VERSION ""

NS_ :

BS_:

BU_:

BO_ 3221225472 VECTOR__INDEPENDENT_SIG_MSG: 0 Vector__XXX
 SG_ ascii_space : 0|8@1+ (1,0) [0|255] "" Vector__XXX
 SG_ TransmissionCurrentRange : 0|8@1+ (1,0) [0|255] "" Vector__XXX
 SG_ ONCmd : 0|1@1+ (1,0) [0|1] "" Vector__XXX
 SG_ NotOff2Cmd : 0|1@1+ (1,0) [0|1] "" Vector__XXX
 SG_ NotOff3Cmd : 0|1@1+ (1,0) [0|1] "" Vector__XXX
 SG_ Enable : 0|1@1+ (1,0) [0|1] "" Vector__XXX
 SG_ NotHLGResetCmd : 0|1@1+ (1,0) [0|1] "" Vector__XXX
 SG_ NotRFGStopCmd : 0|1@1+ (1,0) [0|1] "" Vector__XXX
 SG_ SetpointEn : 0|1@1+ (1,0) [0|1] "" Vector__XXX
 SG_ AckResetQuit : 0|1@1+ (1,0) [0|1] "" Vector__XXX
 SG_ AuxInv1Spd : 0|16@1- (1,0) [-32768|32767] "rpm" Vector__XXX
 SG_ ONCmd : 0|1@1+ (1,0) [0|1] "" Vector__XXX
 SG_ NotOff2Cmd : 0|1@1+ (1,0) [0|1] "" Vector__XXX
 SG_ NotOff3Cmd : 0|1@1+ (1,0) [0|1] "" Vector__XXX
 SG_ Enable : 0|1@1+ (1,0) [0|1] "" Vector__XXX
 SG_ NotHLGResetCmd : 0|1@1+ (1,0) [0|1] "" Vector__XXX
 SG_ NotRFGStopCmd : 0|1@1+ (1,0) [0|1] "" Vector__XXX
 SG_ SetpointEn : 0|1@1+ (1,0) [0|1] "" Vector__XXX
 SG_ AckResetQuit : 0|1@1+ (1,0) [0|1] "" Vector__XXX
 SG_ AuxInv2Spd : 0|16@1- (1,0) [-32768|32767] "rpm" Vector__XXX
 SG_ Requestgear : 0|8@1+ (1,0) [0|255] "" Vector__XXX
 SG_ DNR_led_CurrentLED : 0|8@1+ (1,0) [0|255] "" Vector__XXX
 SG_ DNR_LED_Curt_ASCCI : 0|8@1+ (1,0) [0|255] "" Vector__XXX
 SG_ OBC_charge_enable : 0|2@1+ (1,0) [0|3] "" Vector__XXX
 SG_ Plug_lock_request : 0|2@1+ (1,0) [0|3] "" Vector__XXX
 SG_ Vehicle_Insulation_Monitoring : 0|2@1+ (1,0) [0|3] "" Vector__XXX
 SG_ reserved7 : 0|2@1+ (1,0) [0|3] "" Vector__XXX
 SG_ EV_DisconnectingDevice : 0|2@1+ (1,0) [0|3] "" Vector__XXX
 SG_ reserved8 : 0|12@1+ (1,0) [0|4095] "" Vector__XXX
 SG_ reserved9 : 0|32@1+ (1,0) [0|65535] "" Vector__XXX
 SG_ Inlet_LED_Green : 0|2@1+ (1,0) [0|3] "" Vector__XXX
 SG_ Inlet_LED_Blue : 0|2@1+ (1,0) [0|3] "" Vector__XXX
 SG_ Inlet_LED_Red : 0|2@1+ (1,0) [0|3] "" Vector__XXX
 SG_ EV_DisconnectingDevicePlus : 0|2@1+ (1,0) [0|3] "" Vector__XXX
 SG_ EV_DisconnectingDeviceMinus : 0|2@1+ (1,0) [0|3] "" Vector__XXX
 SG_ EVEnergyRequest : 0|16@1+ (100,0) [0|3276700] "Wh" Vector__XXX
 SG_ EVEnergyCapacity : 0|16@1+ (100,0) [0|3276700] "Wh" Vector__XXX
 SG_ reserved43 : 0|32@1+ (1,0) [0|4294967295] "" Vector__XXX
 SG_ EVSECompatible : 0|2@1+ (1,0) [0|3] "" Vector__XXX
 SG_ VoltageMatch : 0|2@1+ (1,0) [0|3] "" Vector__XXX
 SG_ ControlPilotState : 0|4@1+ (1,0) [0|15] "" Vector__XXX
 SG_ ControlPilotDutyCycle : 0|7@1+ (1,0) [0|100] "%" Vector__XXX
 SG_ TCPStatus : 0|2@1+ (1,0) [0|3] "" Vector__XXX
 SG_ ActualChargeProtocol : 0|4@1+ (1,0) [0|15] "" Vector__XXX
 SG_ Charge_Plug_Locked : 0|2@1+ (1,0) [0|3] "" Vector__XXX
 SG_ ProximityPinState : 0|4@1+ (1,0) [0|15] "" Vector__XXX
 SG_ StateMachineState : 0|4@1+ (1,0) [0|15] "" Vector__XXX
 SG_ reserved3 : 0|1@1+ (1,0) [0|1] "" Vector__XXX
 SG_ reserved4 : 0|2@1+ (1,0) [0|3] "" Vector__XXX
 SG_ reserved5 : 0|6@1+ (1,0) [0|63] "" Vector__XXX
 SG_ reserved6 : 0|24@1+ (1,0) [0|16777215] "" Vector__XXX
 SG_ EVSECurrentRegulationTolerance : 0|8@1+ (0.2,0) [0|50] "A" Vector__XXX
 SG_ EVSEPeakCurrentRipple : 0|8@1+ (0.2,0) [0|50] "A" Vector__XXX
 SG_ EVSEMinVoltage : 0|16@1+ (0.1,0) [0|6500] "V" Vector__XXX
 SG_ EVSEMinCurrent : 0|16@1+ (0.1,-3250) [-3250|3250] "A" Vector__XXX
 SG_ reserved13 : 0|16@1+ (1,0) [0|65535] "" Vector__XXX
 SG_ EVSEEnergyToBeDelivered : 0|16@1+ (100,0) [0|3276700] "Wh" Vector__XXX
 SG_ EVSEMaxPower : 0|16@1+ (100,0) [0|3276700] "W" Vector__XXX
 SG_ EVSEMaxVoltage : 0|16@1+ (0.1,0) [0|6500] "V" Vector__XXX
 SG_ EVSEMaxCurrent : 0|16@1+ (0.1,0) [0|6500] "A" Vector__XXX
 SG_ EVWeldingDetectionEnable : 0|2@1+ (1,0) [0|3] "" Vector__XXX
 SG_ EVReady : 0|2@1+ (1,0) [0|3] "" Vector__XXX
 SG_ ChargeStopIndication : 0|2@1+ (1,0) [0|3] "" Vector__XXX
 SG_ ChargeProgressIndication : 0|2@1+ (1,0) [0|3] "" Vector__XXX
 SG_ reserved19 : 0|24@1+ (1,0) [0|16777215] "" Vector__XXX
 SG_ reserved20 : 0|24@1+ (1,0) [0|16777215] "" Vector__XXX
 SG_ ChargeProtocolPriority : 0|8@1+ (1,0) [0|255] "" Vector__XXX
 SG_ EVRESSConditioning : 0|2@1+ (1,0) [0|3] "" Vector__XXX
 SG_ EVTimeToFullSoC : 0|18@1+ (1,0) [0|262142] "s" Vector__XXX
 SG_ EVTimeToBulkSoC : 0|18@1+ (1,0) [0|262142] "s" Vector__XXX
 SG_ EVErrorCode : 0|4@1+ (1,0) [0|15] "" Vector__XXX
 SG_ EVCabinConditioning : 0|2@1+ (1,0) [0|3] "" Vector__XXX
 SG_ EVBulkChargingComplete : 0|2@1+ (1,0) [0|3] "" Vector__XXX
 SG_ EVChargingComplete : 0|2@1+ (1,0) [0|3] "" Vector__XXX
 SG_ EVSoC : 0|8@1+ (0.5,0) [0|100] "" Vector__XXX
 SG_ reserved21 : 0|2@1+ (1,0) [0|3] "" Vector__XXX
 SG_ reserved22 : 0|6@1+ (1,0) [0|63] "" Vector__XXX
 SG_ EVPreChargeVoltage : 0|16@1+ (0.1,0) [0|6500] "V" Vector__XXX
 SG_ EVTargetVoltage : 0|16@1+ (0.1,0) [0|6500] "V" Vector__XXX
 SG_ EVTargetCurrent : 0|16@1+ (0.1,-3250) [-3250|3250] "A" Vector__XXX
 SG_ reserved17 : 0|16@1+ (1,0) [0|65535] "" Vector__XXX
 SG_ EVBulkSoC : 0|8@1+ (0.5,0) [0|100] "%" Vector__XXX
 SG_ EVFullSoC : 0|8@1+ (0.5,0) [0|100] "%" Vector__XXX
 SG_ EVMaxVoltage : 0|16@1+ (0.1,0) [0|6500] "V" Vector__XXX
 SG_ EVMaxPower : 0|16@1+ (100,0) [0|3276700] "W" Vector__XXX
 SG_ EVMaxCurrent : 0|16@1+ (0.1,0) [0|6500] "A" Vector__XXX
 SG_ EVSEStatusCode : 0|4@1+ (1,0) [0|15] "" Vector__XXX
 SG_ EVSEPowerLimitAchieved : 0|2@1+ (1,0) [0|3] "" Vector__XXX
 SG_ EVSEVoltageLimitAchieved : 0|2@1+ (1,0) [0|3] "" Vector__XXX
 SG_ EVSECurrentLimitAchieved : 0|2@1+ (1,0) [0|3] "" Vector__XXX
 SG_ EVSEIsolationStatus : 0|3@1+ (1,0) [0|7] "" Vector__XXX
 SG_ EVSEPresentCurrent : 0|16@1+ (0.1,-3250) [-3250|3250] "A" Vector__XXX
 SG_ EVSEPresentVoltage : 0|16@1+ (0.1,0) [0|6500] "V" Vector__XXX
 SG_ reserved14 : 0|1@1+ (1,0) [0|1] "" Vector__XXX
 SG_ reserved15 : 0|2@1+ (1,0) [0|3] "" Vector__XXX
 SG_ reserved16 : 0|16@1+ (1,0) [0|65535] "" Vector__XXX
 SG_ EVPreChargeVoltage : 0|16@1+ (0.1,0) [0|6500] "V" Vector__XXX
 SG_ EVTargetVoltage : 0|16@1+ (0.1,0) [0|6500] "V" Vector__XXX
 SG_ EVTargetCurrent : 0|16@1+ (0.1,-3250) [-3250|3250] "A" Vector__XXX
 SG_ reserved18 : 0|16@1+ (1,0) [0|65535] "" Vector__XXX
 SG_ AdjustSeconds : 0|8@1+ (0.25,0) [0|62.5] "s" Vector__XXX
 SG_ AdjustMinutes : 0|8@1+ (1,0) [0|250] "min" Vector__XXX
 SG_ AdjustHours : 0|8@1+ (1,0) [0|250] "h" Vector__XXX
 SG_ AdjustMonth : 0|8@1+ (1,0) [0|250] "month" Vector__XXX
 SG_ AdjustDay : 0|8@1+ (0.25,0) [0|62.5] "Days" Vector__XXX
 SG_ AdjustYear : 0|8@1+ (1,1985) [1985|2235] "year" Vector__XXX
 SG_ AdjustLocalMinuteOffset : 0|8@1+ (1,-125) [-125|125] "min" Vector__XXX
 SG_ AdjustLocalHourOffset : 0|8@1+ (1,-125) [-125|125] "h" Vector__XXX
 SG_ BatteryVoltage : 0|16@1+ (0.1,0) [0|6553.5] "V" Vector__XXX
 SG_ Reserved : 0|2@1+ (1,0) [0|3] "" Vector__XXX
 SG_ Tire_Press_Threshold_Detection : 0|3@1+ (1,0) [0|7] "" Vector__XXX
 SG_ Tire_Temp_Threshold_Detection : 0|3@1+ (1,0) [0|7] "" Vector__XXX
 SG_ Sensor_Battery_Level_Status : 0|2@1+ (1,0) [0|3] "" Vector__XXX
 SG_ Sensor_Battery_Level : 0|8@1+ (1,0) [0|100] "%" Vector__XXX
 SG_ Sensor_RSSI : 0|8@1+ (1,0) [0|100] "dbm" Vector__XXX
 SG_ CTI_Wheel_End_Electrical_Fault : 0|2@1+ (1,0) [0|3] "" Vector__XXX
 SG_ CTI_Tire_Status : 0|2@1+ (1,0) [0|3] "" Vector__XXX
 SG_ Sensor_Status : 0|2@1+ (1,0) [0|3] "" Vector__XXX
 SG_ Tire_Temperature : 0|16@1- (0.03125,-273) [-273|750.96875] "deg C" Vector__XXX
 SG_ Tire_Pressure : 0|8@1+ (5.5,0) [0|1400] "kPa" Vector__XXX
 SG_ Tire_Location : 0|8@1+ (1,0) [0|255] "" Vector__XXX
 SG_ TP_Front_Left : 0|8@1+ (1,0) [0|1] "PSI" Vector__XXX
 SG_ TP_Front_Right : 0|8@1+ (1,0) [0|255] "PSI" Vector__XXX
 SG_ TP_Rear_Left_Outer : 0|8@1+ (1,0) [0|255] "PSI" Vector__XXX
 SG_ TP_Rear_Left_Inner : 0|8@1+ (1,0) [0|255] "PSI" Vector__XXX
 SG_ TP_Rear_Right_Outer : 0|8@1+ (1,0) [0|255] "PSI" Vector__XXX
 SG_ TP_Rear_Right_Inner : 0|8@1+ (1,0) [0|255] "PSI" Vector__XXX
 SG_ Seat_Belt : 0|1@1+ (1,0) [0|1] "" Vector__XXX
 SG_ Crash_Detection : 0|1@1+ (1,0) [0|1] "" Vector__XXX
 SG_ Harsh_Braking : 0|1@1+ (1,0) [0|1] "" Vector__XXX
 SG_ TP_Spare_Tire : 0|8@1+ (1,0) [0|255] "PSL" Vector__XXX
 SG_ TT_Front_Left : 0|8@1+ (1,0) [0|255] "degree C" Vector__XXX
 SG_ TT_Front_Right : 0|8@1+ (1,0) [0|255] "degree C" Vector__XXX
 SG_ TT_Rear_Left_Outer : 0|8@1+ (1,0) [0|255] "degree C" Vector__XXX
 SG_ TT_Rear_Left_Inner : 0|8@1+ (1,0) [0|1] "degree C" Vector__XXX
 SG_ TT_Rear_Right_Outer : 0|8@1+ (1,0) [0|255] "degree C" Vector__XXX
 SG_ TT_Rear_Right_Inner : 0|8@1+ (1,0) [0|255] "degree C" Vector__XXX
 SG_ TT_Spare_Tire : 0|8@1+ (1,0) [0|1] "degree C" Vector__XXX
 SG_ Tel_SOC : 0|8@1+ (1,0) [0|100] "" Vector__XXX
 SG_ Tel_Battery_Current : 0|16@1+ (1,-255) [-255|32767] "" Vector__XXX
 SG_ Tel_Battery_Voltage : 0|8@1+ (4,0) [0|1020] "" Vector__XXX
 SG_ Tel_KWh_remaining : 0|8@1+ (1,0) [0|200] "" Vector__XXX
 SG_ Tel_SOH : 0|8@1+ (1,0) [0|100] "" Vector__XXX
 SG_ Tel_Battery_System_Fault : 0|1@1+ (1,0) [0|1] "" Vector__XXX
 SG_ Tel_Regeneration : 0|1@1+ (1,0) [0|1] "" Vector__XXX
 SG_ Tel_Low_Pressure : 0|1@1+ (1,0) [0|1] "" Vector__XXX
 SG_ Tel_Charging_Status : 0|1@1+ (1,0) [0|1] "" Vector__XXX
 SG_ Tel_Charge_Plug_Status : 0|1@1+ (1,0) [0|1] "" Vector__XXX
 SG_ Tel_Bat_Temp : 0|8@1+ (1,0) [0|255] "C" Vector__XXX
 SG_ Tel_BCS_Comp_En : 0|1@1+ (1,0) [0|1] "" Vector__XXX
 SG_ Tel_BCS_Pump_En : 0|1@1+ (1,0) [0|1] "" Vector__XXX
 SG_ Tel_motor_speed : 0|8@1+ (10,0) [0|2550] "" Vector__XXX
 SG_ Tel_Vehicle_Speed : 0|8@1+ (1,0) [0|100] "" Vector__XXX
 SG_ Tel_Motor_Temperature : 0|8@1+ (1,0) [0|200] "" Vector__XXX
 SG_ Tel_Front_End_Aux_Fault : 0|1@1+ (1,0) [0|1] "" Vector__XXX
 SG_ Tel_Traction_System_Fault : 0|1@1+ (1,0) [0|1] "" Vector__XXX
 SG_ Tel_LV_System_Fault : 0|1@1+ (1,0) [0|1] "" Vector__XXX
 SG_ Energy_Consumption_per_km : 0|16@1- (0.001,0) [-32.768|32.767] "kwh/km" Vector__XXX
 SG_ Instant_Energy_Cons_per_km : 0|16@1- (0.001,0) [-32.768|32.767] "" Vector__XXX
 SG_ Charge_Plug_Locked : 0|1@1+ (1,0) [0|1] "" Vector__XXX
 SG_ State_Machine_State : 0|4@1+ (1,0) [0|15] "" Vector__XXX
 SG_ IVT_Voltage_Inlet_Value : 0|32@1- (0.001,0) [-2147483.648|2147483.647] "V" Vector__XXX
 SG_ IVT_Voltage_Inlet_ResultState : 0|4@1+ (1,0) [0|15] "" Vector__XXX
 SG_ IVT_Voltage_Inlet_MsgCount : 0|4@1+ (1,0) [0|15] "" Vector__XXX
 SG_ IVT_Voltage_Inlet_MuxId : 0|8@1+ (1,0) [0|255] "" Vector__XXX
 SG_ IVT_Voltage_Vehicle_Value : 0|32@1- (0.001,0) [-2147483.648|2147483.647] "" Vector__XXX
 SG_ IVT_Voltage_Vehicle_ResultState : 0|4@1+ (1,0) [0|15] "" Vector__XXX
 SG_ IVT_Voltage_Vehicle_MsgCount : 0|4@1+ (1,0) [0|15] "" Vector__XXX
 SG_ IVT_Voltage_Vehicle_MuxId : 0|8@1+ (1,0) [0|255] "" Vector__XXX
 SG_ IVT_Current_Value : 0|32@1- (0.001,0) [-2147483.648|2147483.647] "" Vector__XXX
 SG_ IVT_Current_ResultState : 0|4@1+ (1,0) [0|15] "" Vector__XXX
 SG_ IVT_Current_MsgCount : 0|4@1+ (1,0) [0|15] "" Vector__XXX
 SG_ IVT_Current_MuxId : 0|8@1+ (1,0) [0|255] "" Vector__XXX
 SG_ EVSEBptMinDischargeCurrent : 0|16@1+ (0.1,0) [0|160] "A" Vector__XXX
 SG_ EVSEBptMaxDischargeCurrent : 0|16@1+ (0.1,0) [0|160] "A" Vector__XXX
 SG_ EVSEBptGenMode : 0|2@1+ (1,0) [0|3] "" Vector__XXX
 SG_ EVBptTargetEnergyReq : 0|16@1+ (0.1,-1000) [-819|819] "kWh" Vector__XXX
 SG_ EVBptMinVoltage : 0|16@1+ (0.1,0) [0|1500] "V" Vector__XXX
 SG_ EVBptMinV2XEnergyReq : 0|16@1+ (0.1,-1000) [-819|819] "kWh" Vector__XXX
 SG_ EVBptMaxV2XEnergyReq : 0|16@1+ (0.1,-1000) [-819|819] "kWh" Vector__XXX
 SG_ EVBptMinEnergyReq : 0|16@1+ (0.1,-1000) [-819|819] "kWh" Vector__XXX
 SG_ EVBptMaxDischargePower : 0|24@1+ (1,0) [0|1300000] "W" Vector__XXX
 SG_ EVBptMaxDischargeCurrent : 0|16@1+ (0.1,0) [0|160] "A" Vector__XXX
 SG_ EVBptMaxEnergyReq : 0|16@1+ (0.1,-1000) [-819|819] "kWh" Vector__XXX
 SG_ EVBptMaxChargePower : 0|24@1+ (1,0) [0|1300000] "W" Vector__XXX
 SG_ EVBptMaxChargeCurrent : 0|16@1+ (0.1,0) [0|160] "A" Vector__XXX
 SG_ EVBptMinDischargeCurrent : 0|16@1+ (0.1,0) [0|160] "A" Vector__XXX
 SG_ EVBptMinChargeCurrent : 0|16@1+ (0.1,0) [0|160] "A" Vector__XXX
 SG_ EVBptTargetSoc : 0|8@1+ (1,0) [0|100] "" Vector__XXX
 SG_ EVBptReq : 0|1@1+ (1,0) [0|1] "" Vector__XXX
 SG_ EVBptCat : 0|2@1+ (1,0) [0|3] "" Vector__XXX
 SG_ EVBptMinDischargePower : 0|24@1+ (1,0) [0|1300000] "W" Vector__XXX
 SG_ EVBptMinChargePower : 0|24@1+ (1,0) [0|1300000] "W" Vector__XXX
 SG_ CCL_ControlPilotState : 0|8@1+ (1,0) [0|255] "" Vector__XXX
 SG_ CCL_ACChargingPossible : 0|1@1+ (1,0) [0|1] "" Vector__XXX
 SG_ CCL_ProximityPinState : 0|4@1+ (1,0) [0|15] "" Vector__XXX
 SG_ CCL_ControlPilotDutyCycle : 0|7@1+ (1,0) [0|100] "%" Vector__XXX
 SG_ CCL_InletACTemperature : 0|16@1+ (0.1,-50) [-50|150] "�C" Vector__XXX
 SG_ CCL_HVPlugTemperature : 0|16@1+ (0.1,-50) [-50|150] "�C" Vector__XXX
 SG_ CCL_HVSwitchTemperature : 0|16@1+ (0.1,-50) [-50|150] "�C" Vector__XXX
 SG_ CCL_InletDCTemperature : 0|16@1+ (0.1,-50) [-50|150] "�C" Vector__XXX
 SG_ EVSE_EVSEID : 0|64@1+ (1,0) [0|1.84467440737096E+19] "" Vector__XXX
 SG_ VCU_EVCCID : 0|64@1+ (1,0) [0|1.84467440737096E+19] "" Vector__XXX
 SG_ VCU_LED4PWM : 0|10@1+ (0.1,0) [0|100] "%" Vector__XXX
 SG_ VCU_LED3PWM : 0|10@1+ (0.1,0) [0|100] "%" Vector__XXX
 SG_ VCU_LED2PWM : 0|10@1+ (0.1,0) [0|100] "%" Vector__XXX
 SG_ VCU_LED1PWM : 0|10@1+ (0.1,0) [0|100] "%" Vector__XXX
 SG_ EVSE_PresentVoltage : 0|16@1+ (0.1,0) [0|6500] "V" Vector__XXX
 SG_ EVSE_PresentCurrent : 0|16@1+ (0.1,-3250) [-3250|3250] "A" Vector__XXX
 SG_ VCU_InletVoltage : 0|16@1+ (0.1,0) [0|6500] "V" Vector__XXX
 SG_ VCU_HVSW2State : 0|2@1+ (1,0) [0|3] "" Vector__XXX
 SG_ VCU_HVSW1State : 0|2@1+ (1,0) [0|3] "" Vector__XXX
 SG_ VCU_CRC : 0|8@1+ (1,0) [0|255] "" Vector__XXX
 SG_ VCU_SequenceCounter : 0|4@1+ (1,0) [0|15] "" Vector__XXX
 SG_ VCU_VehicleVoltage : 0|16@1+ (0.1,0) [0|6500] "V" Vector__XXX
 SG_ VCU_EmergencySeparation : 0|1@1+ (1,0) [0|1] "" Vector__XXX
 SG_ CCL_HVSW2StateRequest : 0|2@1+ (1,0) [0|3] "" Vector__XXX
 SG_ CCL_HVSW1StateRequest : 0|2@1+ (1,0) [0|3] "" Vector__XXX
 SG_ CCL_SequenceCounter : 0|4@1+ (1,0) [0|15] "" Vector__XXX
 SG_ CCL_CRC : 0|8@1+ (1,0) [0|255] "" Vector__XXX
 SG_ CCL_IL_HVInlet : 0|2@1+ (1,0) [0|1] "" Vector__XXX
 SG_ CCL_IL_HVGrid : 0|2@1+ (1,0) [0|1] "" Vector__XXX
 SG_ CCL_EmergencyShutdown : 0|1@1+ (1,0) [0|1] "" Vector__XXX
 SG_ CCL_PlugState : 0|4@1+ (1,0) [0|15] "" Vector__XXX
 SG_ VCU_EVCabinConditioning : 0|2@1+ (1,0) [0|1] "" Vector__XXX
 SG_ VCU_EVRESSConditioning : 0|2@1+ (1,0) [0|1] "" Vector__XXX
 SG_ VCU_EVRemainingTimeToFullSoC : 0|18@1+ (1,0) [0|172800] "s" Vector__XXX
 SG_ VCU_EVRemainingTimeToBulkSoC : 0|18@1+ (1,0) [0|172800] "s" Vector__XXX
 SG_ VCU_EVBulkChargingComplete : 0|2@1+ (1,0) [0|1] "" Vector__XXX
 SG_ VCU_EVFullSOC : 0|8@1+ (0.5,0) [0|100] "%" Vector__XXX
 SG_ VCU_EVBulkSOC : 0|8@1+ (0.5,0) [0|100] "%" Vector__XXX
 SG_ CCL_HWVersion : 0|8@1+ (1,0) [0|255] "" Vector__XXX
 SG_ CCL_CANVersion : 0|8@1+ (1,0) [0|255] "" Vector__XXX
 SG_ CCL_SWMajorVersion : 0|8@1+ (1,0) [0|255] "" Vector__XXX
 SG_ CCL_SWBuildVersion : 0|8@1+ (1,0) [0|255] "" Vector__XXX
 SG_ CCL_SWMinorVersion : 0|8@1+ (1,0) [0|255] "" Vector__XXX
 SG_ EVSE_MinimumCurrentLimit : 0|16@1+ (0.1,-3250) [-3250|3250] "A" Vector__XXX
 SG_ EVSE_MinimumVoltageLimit : 0|16@1+ (0.1,0) [0|6500] "V" Vector__XXX
 SG_ EVSE_State : 0|4@1+ (1,0) [0|15] "" Vector__XXX
 SG_ EVSE_EnergyToBeDelivered : 0|16@1+ (100,0) [0|3276700] "Wh" Vector__XXX
 SG_ EVSE_PeakCurrentRipple : 0|8@1+ (0.2,0) [0|50] "A" Vector__XXX
 SG_ EVSE_CurrentRegTolerance : 0|8@1+ (0.2,0) [0|50] "A" Vector__XXX
 SG_ EVSE_CurrentLimitAchieved : 0|1@1+ (1,0) [0|1] "" Vector__XXX
 SG_ EVSE_VoltageLimitAchieved : 0|1@1+ (1,0) [0|1] "" Vector__XXX
 SG_ EVSE_PowerLimitAchieved : 0|1@1+ (1,0) [0|1] "" Vector__XXX
 SG_ CCL_ActualChargingProtocol : 0|4@1+ (1,0) [0|15] "" Vector__XXX
 SG_ CCL_DTC_RSL : 0|1@1+ (1,0) [0|1] "" Vector__XXX
 SG_ CCL_DTC_PL : 0|1@1+ (1,0) [0|1] "" Vector__XXX
 SG_ CCL_DTC_AWL : 0|1@1+ (1,0) [0|1] "" Vector__XXX
 SG_ CCL_ChargingMode : 0|4@1+ (1,0) [0|15] "" Vector__XXX
 SG_ CCL_WakeUpReason : 0|4@1+ (1,0) [0|15] "" Vector__XXX
 SG_ CCL_LockState : 0|4@1+ (1,0) [0|15] "" Vector__XXX
 SG_ CCL_HVSWState : 0|4@1+ (1,0) [0|15] "" Vector__XXX
 SG_ CCL_TargetCurrent : 0|16@1+ (0.1,-3250) [-3250|3250] "A" Vector__XXX
 SG_ CCL_State : 0|4@1+ (1,0) [0|15] "" Vector__XXX
 SG_ EVSE_MaximumCurrentLimit : 0|16@1+ (0.1,0) [0|6500] "A" Vector__XXX
 SG_ EVSE_MaximumVoltageLimit : 0|16@1+ (0.1,0) [0|6500] "V" Vector__XXX
 SG_ EVSE_MaximumPowerLimit : 0|16@1+ (100,0) [0|3276700] "W" Vector__XXX
 SG_ CCL_ShutdownRequest : 0|1@1+ (1,0) [0|1] "" Vector__XXX
 SG_ CCL_ErrorNumber : 0|16@1+ (1,0) [0|65535] "" Vector__XXX
 SG_ EVSE_StatusCode : 0|4@1+ (1,0) [0|15] "" Vector__XXX
 SG_ CCL_ButtonState : 0|2@1+ (1,0) [0|3] "" Vector__XXX
 SG_ VCU_EVEnergyRequest : 0|16@1+ (100,0) [0|3276700] "Wh" Vector__XXX
 SG_ VCU_EVTargetCurrent : 0|16@1+ (0.1,-3250) [-3250|3250] "A" Vector__XXX
 SG_ VCU_EVTargetVoltage : 0|16@1+ (0.1,0) [0|6500] "V" Vector__XXX
 SG_ VCU_EVSOC : 0|8@1+ (0.5,0) [0|100] "%" Vector__XXX
 SG_ VCU_EVError : 0|8@1+ (1,0) [0|255] "" Vector__XXX
 SG_ VCU_EVDCMaximumCurrentLimit : 0|16@1+ (0.1,0) [0|3250] "A" Vector__XXX
 SG_ VCU_EVDCMaximumPowerLimit : 0|16@1+ (100,0) [0|3276700] "W" Vector__XXX
 SG_ VCU_EVDCMaximumVoltageLimit : 0|16@1+ (0.1,0) [0|6500] "V" Vector__XXX
 SG_ VCU_EVEnergyCapacity : 0|16@1+ (100,0) [0|3276700] "Wh" Vector__XXX
 SG_ VCU_LockPermission : 0|1@1+ (1,0) [0|1] "" Vector__XXX
 SG_ VCU_UnlockPermission : 0|1@1+ (1,0) [0|1] "" Vector__XXX
 SG_ VCU_HVReady : 0|1@1+ (1,0) [0|1] "" Vector__XXX
 SG_ VCU_ChargePermission : 0|1@1+ (1,0) [0|1] "" Vector__XXX
 SG_ COUNT : 0|64@1+ (1,0) [0|1.84467440737096E+19] "" Vector__XXX
 SG_ Time_to_Full : 0|16@1+ (1,0) [0|65535] "" Vector__XXX
 SG_ Distance_To_Empty : 0|16@1+ (1,0) [0|65535] "" Vector__XXX
 SG_ Traction_BATTERY_VOLTAGE : 0|12@1+ (0.25,0) [0|1000] "volts" Vector__XXX
 SG_ Motor_Regenration_Status : 0|2@1+ (1,0) [0|3] "" Vector__XXX
 SG_ LV_Battery_Not_Charging : 0|2@1+ (1,0) [0|1] "" Vector__XXX
 SG_ Low_Air_Pressure : 0|2@1+ (1,0) [0|1] "" Vector__XXX
 SG_ Limp_home : 0|2@1+ (1,0) [0|1] "" Vector__XXX
 SG_ Ev_Isolation : 0|2@1+ (1,0) [0|1] "" Vector__XXX
 SG_ Hill_Hold : 0|2@1+ (1,0) [0|1] "" Vector__XXX
 SG_ Charge_Plug_Connected : 0|2@1+ (1,0) [0|1] "" Vector__XXX
 SG_ Motor_Temp_Warning : 0|2@1+ (1,0) [0|1] "" Vector__XXX
 SG_ SOC_Level : 0|2@1+ (1,0) [0|1] "" Vector__XXX
 SG_ Drive_D : 0|1@1+ (1,0) [0|1] "" Vector__XXX
 SG_ Neutral_N : 0|1@1+ (1,0) [0|1] "" Vector__XXX
 SG_ Reverse_R : 0|1@1+ (1,0) [0|1] "" Vector__XXX
 SG_ SOC : 0|8@1+ (0.5,0) [0|100] "%" Vector__XXX
 SG_ TotalVehicleDistance_ODO : 0|32@1+ (0.1,0) [0|429496729.5] "km" Vector__XXX
 SG_ TripDistance : 0|32@1+ (0.1,0) [0|429496729.5] "km" Vector__XXX
 SG_ Traction_Battery_Total_Used : 0|32@1+ (0.05,0) [0|214748364.75] "Wh" Vector__XXX
 SG_ Traction_Battery_Temperature : 0|8@1+ (1,-40) [-40|210] "deg C" Vector__XXX
 SG_ Traction_Motor_Temp : 0|8@1+ (1,-40) [-40|210] "deg C" Vector__XXX
 SG_ Motor_Speed_RPM : 0|16@1+ (0.125,0) [0|8191.875] "rpm" Vector__XXX
 SG_ WheelBasedVehicleSpeed : 0|16@1+ (0.004,0) [0|255.9961] "km/h" Vector__XXX
 SG_ Air_Pressure1 : 0|8@1+ (1,0) [0|210] "" Vector__XXX
 SG_ Air_Pressure2 : 0|8@1+ (1,0) [0|210] "" Vector__XXX
 SG_ ODO : 0|24@1+ (0.1,0) [0|1677721.5] "" Vector__XXX
 SG_ Air_Comp_Energy_Cons : 0|8@1+ (0.1,0) [0|25.5] "kwh" Vector__XXX
 SG_ PS_Energy_Cons : 0|8@1+ (0.2,0) [0|51] "kwh" Vector__XXX
 SG_ BCS_Energy_Cons : 0|8@1+ (0.2,0) [0|51] "kwh" Vector__XXX
 SG_ DCDC_Energy_Consumption : 0|8@1+ (0.2,0) [0|51] "kwh" Vector__XXX
 SG_ Motor_Energy_Consumption : 0|8@1+ (1,0) [0|255] "kwh" Vector__XXX
 SG_ Total_Energy_Consumption : 0|8@1+ (1,0) [0|255] "kwh" Vector__XXX
 SG_ Reg_Energy : 0|8@1+ (1,0) [0|1] "" Vector__XXX
 SG_ Battery_Pack_A_Engy : 0|8@1+ (1,0) [0|255] "KWh" Vector__XXX
 SG_ Battery_Pack_B_Engy : 0|8@1+ (1,0) [0|255] "KWh" Vector__XXX
 SG_ Total_Battery_Engy : 0|16@1+ (1,0) [0|255] "KWh" Vector__XXX
 SG_ EVSE_Engy_Delv : 0|8@1+ (1,0) [0|1] "KWH" Vector__XXX
 SG_ Coasting_Regn_KWH : 0|8@1+ (1,0) [0|255] "KWH" Vector__XXX
 SG_ BRK_Regn : 0|8@1+ (1,0) [0|255] "KWH" Vector__XXX
 SG_ EPKM_trip1 : 0|8@1+ (0.01,0) [0|2.55] "KWH/KM" Vector__XXX
 SG_ EPKM_trip2 : 0|8@1+ (0.01,0) [0|2.55] "KWH/KM" Vector__XXX
 SG_ EPKM_trip3 : 0|8@1+ (0.01,0) [0|2.55] "KWH/KM" Vector__XXX
 SG_ KM_Trip1 : 0|9@1+ (1,0) [0|511] "KWH/KM" Vector__XXX
 SG_ KM_Trip2 : 0|9@1+ (1,0) [0|511] "KWH/KM" Vector__XXX
 SG_ KM_Trip3 : 0|9@1+ (1,0) [0|511] "KWH/KM" Vector__XXX
 SG_ CHARGER_PRESENT_CURRENT : 0|16@0+ (0.1,0) [0|6553.5] "Amps" Vector__XXX
 SG_ CHARGER_PRESENT_VOLTAGE : 0|16@0+ (0.1,0) [0|6553.5] "Volts" Vector__XXX
 SG_ CHARGER_MAX_POWER : 0|16@0+ (10,0) [0|655350] "Watt" Vector__XXX
 SG_ CHARGER_MIN_VOLTAGE : 0|16@0+ (0.1,0) [0|6553.5] "Volts" Vector__XXX
 SG_ SOFTWARE_VERSION : 0|8@0+ (0.1,0) [0|25.5] "Num" Vector__XXX
 SG_ CHARGER_MAX_VOLTAGE : 0|16@0+ (0.1,0) [0|6553.5] "Volts" Vector__XXX
 SG_ CHARGER_MIN_CURRENT : 0|16@0+ (0.1,0) [0|6553.5] "Amps" Vector__XXX
 SG_ CHARGER_MAX_CURRENT : 0|16@0+ (0.1,0) [0|6553.5] "Amps" Vector__XXX
 SG_ SELECTED_APP_PROTOCOL : 0|8@0+ (1,0) [0|3] "" Vector__XXX
 SG_ CP_STATE : 0|8@0+ (1,0) [0|255] "" Vector__XXX
 SG_ EVSE_ERROR_CODE : 0|8@0+ (1,0) [0|255] "" Vector__XXX
 SG_ EVCC_ERROR_CODES : 0|8@0+ (1,0) [0|255] "" Vector__XXX
 SG_ TERMINATION_DETAIL : 0|8@0+ (1,0) [0|255] "" Vector__XXX
 SG_ HV_READY : 0|1@0+ (1,0) [0|1] "" Vector__XXX
 SG_ FORCE_ACTUATOR_UNLOCK : 0|1@0+ (1,0) [0|1] "" Vector__XXX
 SG_ NOMINAL_BATT_CAPACITY : 0|16@0+ (1,0) [0|1000] "Ah" Vector__XXX
 SG_ REMAINING_BATT_CAPACITY : 0|8@0+ (1,0) [0|255] "KWh" Vector__XXX
 SG_ EV_ERROR_CODE : 0|8@0+ (1,0) [0|255] "" Vector__XXX
 SG_ VEH_STOP_CHARGING_FLAG : 0|1@0+ (1,0) [0|1] "" Vector__XXX
 SG_ CHARGING_COMPLETE_FLAG : 0|1@0+ (1,0) [0|1] "" Vector__XXX
 SG_ EV_READY_FLAG : 0|1@0+ (1,0) [0|1] "" Vector__XXX
 SG_ EVSE_Protocol_Priority_Selection : 0|8@0+ (1,0) [0|1] "" Vector__XXX
 SG_ BATT_PACK_PRESENT_VOLTAGE : 0|16@0+ (0.25,0) [0|1000] "Volt" Vector__XXX
 SG_ EV_CONTINEOUS_CHRG_CURR_LIMIT : 0|8@0+ (1,0) [0|255] "Amps" Vector__XXX
 SG_ SOC : 0|8@0+ (0.5,0) [0|100] "%" Vector__XXX
 SG_ EV_MAX_CHRG_CURR_LIMIT : 0|16@0+ (0.25,0) [0|1000] "Amps" Vector__XXX
 SG_ VEHICLE_IMMOBILIZE : 0|1@0+ (1,0) [0|1] "" Vector__XXX
 SG_ EVCC_GUN_UNLOCK_REQUEST_STATUS : 0|1@0+ (1,0) [0|1] "" Vector__XXX
 SG_ EVCC_GUN_LOCK_REQUEST_STATUS : 0|1@0+ (1,0) [0|1] "" Vector__XXX
 SG_ GUN_LOCK_FEEDBACK : 0|1@0+ (1,0) [0|1] "" Vector__XXX
 SG_ GUN_LOCK_FAULT : 0|1@0+ (1,0) [0|1] "" Vector__XXX
 SG_ TEMP_2_FAULT : 0|1@0+ (1,0) [0|1] "" Vector__XXX
 SG_ TEMP_1_FAULT : 0|1@0+ (1,0) [0|1] "" Vector__XXX
 SG_ OBC_DERATING_FACTOR : 0|8@0+ (1,0) [0|100] "%" Vector__XXX
 SG_ TEMPERATURE_2_VALUE : 0|16@0- (0.1,0) [-50|200] "DegC" Vector__XXX
 SG_ TEMPERATURE_1_VALUE : 0|16@0- (0.1,0) [-50|200] "DegC" Vector__XXX
 SG_ EV_Error_Code : 0|8@0+ (1,0) [0|255] "" Vector__XXX
 SG_ SELECTED_ATTENUATION_IN_DB : 0|8@0+ (1,0) [0|255] "" Vector__XXX
 SG_ CP_DUTY_CYCLE : 0|8@0+ (1,0) [0|100] "%" Vector__XXX
 SG_ PP_GUN_RESISTANCE : 0|16@0+ (1,0) [0|65535] "Ohm" Vector__XXX
 SG_ DIFFERENTIAL_CURRENT_MEAS : 0|8@0+ (1,0) [0|255] "" Vector__XXX
 SG_ NEGATIVE_CONTACTOR_CONTROL : 0|1@0+ (1,0) [0|1] "" Vector__XXX
 SG_ CHARGING_STATUS : 0|1@0+ (1,0) [0|1] "" Vector__XXX
 SG_ POSITIVE_CONTACTOR_CONTROL : 0|1@0+ (1,0) [0|1] "" Vector__XXX
 SG_ GUN_DETECTED : 0|1@0+ (1,0) [0|1] "" Vector__XXX
 SG_ EVCC_READY : 0|1@0+ (1,0) [0|1] "" Vector__XXX
 SG_ EVCC_STATUS_CODE : 0|8@0+ (1,0) [0|255] "" Vector__XXX
 SG_ TMS_Comp_Spd : 0|16@0+ (1,0) [0|6000] "rpm" Vector__XXX
 SG_ TMS_DCDC_Voltage : 0|16@1- (0.1,0) [-3276.8|3276.7] "V" Vector__XXX
 SG_ TMS_DCDC_Current : 0|16@1- (0.1,0) [-3276.8|3276.7] "A" Vector__XXX
 SG_ TMS_Comp_Voltage : 0|16@0- (0.1,0) [-3276.8|3276.7] "V" Vector__XXX
 SG_ TMS_Comp_Current : 0|16@0- (0.1,0) [-3276.8|3276.7] "A" Vector__XXX
 SG_ VCU_T_SetpointReq : 0|8@1+ (1,-40) [-40|215] "�C" Vector__XXX
 SG_ VCU_Mode : 0|2@1+ (1,0) [0|3] "" Vector__XXX
 SG_ VCU_Ctrl_Mode : 0|1@1+ (1,0) [0|1] "" Vector__XXX
 SG_ VCU_Blower_SpdReq : 0|3@1+ (20,0) [0|100] "%" Vector__XXX
 SG_ TMS_T_Room : 0|16@1+ (0.03125,-273) [-273|1774.96875] "�C" Vector__XXX
 SG_ TMS_T_Ambient : 0|16@1+ (0.03125,-273) [-273|1774.96875] "�C" Vector__XXX
 SG_ SetPointCompressor : 0|8@1+ (0.4,0) [0|102] "%" Vector__XXX
 SG_ SetPointAxialFans : 0|8@1+ (0.4,0) [0|102] "%" Vector__XXX
 SG_ SetPointRadialBlowers : 0|8@1+ (0.4,0) [0|102] "%" Vector__XXX
 SG_ Error_Error_T_Coolant_1 : 0|2@1+ (1,0) [0|3] "" Vector__XXX
 SG_ Error_Error_T_Coolant_2 : 0|2@1+ (1,0) [0|3] "" Vector__XXX
 SG_ Error_PTCAOvertemp : 0|2@1+ (1,0) [0|3] "" Vector__XXX
 SG_ Error_PTCBOvertemp : 0|2@1+ (1,0) [0|3] "" Vector__XXX
 SG_ Error_Slave : 0|2@1+ (1,0) [0|3] "" Vector__XXX
 SG_ Error_Error_Tice_local : 0|2@1+ (1,0) [0|3] "" Vector__XXX
 SG_ Error_Undervoltage_local : 0|2@1+ (1,0) [0|3] "" Vector__XXX
 SG_ Error_T_InnerHX : 0|2@1+ (1,0) [0|3] "" Vector__XXX
 SG_ Error_T_OuterHX : 0|2@1+ (1,0) [0|3] "" Vector__XXX
 SG_ Error_SwitchingValve : 0|2@1+ (1,0) [0|3] "" Vector__XXX
 SG_ Error_HVACCAN : 0|2@1+ (1,0) [0|3] "" Vector__XXX
 SG_ Error_PTC_CU_Defect : 0|2@1+ (1,0) [0|3] "" Vector__XXX
 SG_ Error_PTC_CU_SLIFail : 0|2@1+ (1,0) [0|3] "" Vector__XXX
 SG_ Error_PTC_CU_HVFail : 0|2@1+ (1,0) [0|3] "" Vector__XXX
 SG_ Error_PTC_Defect : 0|2@1+ (1,0) [0|3] "" Vector__XXX
 SG_ Error_PTC_StuckOnDefect : 0|2@1+ (1,0) [0|3] "" Vector__XXX
 SG_ Error_SLIVTooHigh : 0|2@1+ (1,0) [0|3] "" Vector__XXX
 SG_ Error_Undervoltage : 0|2@1+ (1,0) [0|3] "" Vector__XXX
 SG_ Error_CompressorBLimit : 0|2@1+ (1,0) [0|3] "" Vector__XXX
 SG_ Error_CompressorHighPressure : 0|2@1+ (1,0) [0|3] "" Vector__XXX
 SG_ Error_HVTooHigh : 0|2@1+ (1,0) [0|3] "" Vector__XXX
 SG_ Error_CompressorALimit : 0|2@1+ (1,0) [0|3] "" Vector__XXX
 SG_ Error_CompressorAInverter : 0|2@1+ (1,0) [0|3] "" Vector__XXX
 SG_ Error_RoomTemperatureSensor : 0|2@1+ (1,0) [0|3] "" Vector__XXX
 SG_ Error_Motor2 : 0|2@1+ (1,0) [0|3] "" Vector__XXX
 SG_ Error_Motor1 : 0|2@1+ (1,0) [0|3] "" Vector__XXX
 SG_ Error_LowPressureSensor : 0|2@1+ (1,0) [0|3] "" Vector__XXX
 SG_ Error_HVACType : 0|2@1+ (1,0) [0|3] "" Vector__XXX
 SG_ Error_HighPressureSensor : 0|2@1+ (1,0) [0|3] "" Vector__XXX
 SG_ Error_DuctTemperatureSensor : 0|2@1+ (1,0) [0|3] "" Vector__XXX
 SG_ Error_CAN : 0|2@1+ (1,0) [0|3] "" Vector__XXX
 SG_ Error_ApplicationAddressing : 0|2@1+ (1,0) [0|3] "" Vector__XXX
 SG_ Error_AmbientTemperatureSensor : 0|2@1+ (1,0) [0|3] "" Vector__XXX
 SG_ Error_CompressorALimitInfo : 0|2@1+ (1,0) [0|3] "" Vector__XXX
 SG_ Error_CompressorBLimitInfo : 0|2@1+ (1,0) [0|3] "" Vector__XXX
 SG_ Error_EmergStop : 0|2@1+ (1,0) [0|3] "" Vector__XXX
 SG_ Error_T_Ice : 0|2@1+ (1,0) [0|3] "" Vector__XXX
 SG_ Error_Heater : 0|2@1+ (1,0) [0|3] "" Vector__XXX
 SG_ Error_Motor3 : 0|2@1+ (1,0) [0|3] "" Vector__XXX
 SG_ Error_Motor4 : 0|2@1+ (1,0) [0|3] "" Vector__XXX
 SG_ Error_CompressorACommonEDS : 0|2@1+ (1,0) [0|3] "" Vector__XXX
 SG_ Error_CompressorBCommonEDS : 0|2@1+ (1,0) [0|3] "" Vector__XXX
 SG_ Error_CompressorBInverter : 0|2@1+ (1,0) [0|3] "" Vector__XXX
 SG_ Error_CompressorLowPressure : 0|2@1+ (1,0) [0|3] "" Vector__XXX
 SG_ Error_CompressorIcing : 0|2@1+ (1,0) [0|3] "" Vector__XXX
 SG_ Error_UndervoltageHV : 0|2@1+ (1,0) [0|3] "" Vector__XXX
 SG_ Inp_bError_T_Floor_1 : 0|2@1+ (1,0) [0|3] "" Vector__XXX
 SG_ Error_T_Floor_2 : 0|2@1+ (1,0) [0|3] "" Vector__XXX
 SG_ VCU_BenchTestSpeedLimitEnable : 0|1@1+ (1,0) [0|1] "" Vector__XXX
 SG_ VCU_ZeroTorqueSlope : 0|8@1+ (1,0) [0|255] "ms/20Nm" Vector__XXX
 SG_ VCU_Mode_R : 0|1@1+ (1,0) [0|1] "" Vector__XXX
 SG_ VCU_Mode_Braking : 0|1@1+ (1,0) [0|1] "" Vector__XXX
 SG_ VCU_Reserved : 0|1@1+ (1,0) [0|1] "" Vector__XXX
 SG_ VCU_Mode_D : 0|1@1+ (1,0) [0|1] "" Vector__XXX
 SG_ VCU_ASCEnable : 0|1@1+ (1,0) [0|1] "" Vector__XXX
 SG_ VCU_HillHoldEnable : 0|1@1+ (1,0) [0|1] "" Vector__XXX
 SG_ VCU_ControlMode : 0|1@1+ (1,0) [0|1] "" Vector__XXX
 SG_ VCU_Mode_N : 0|1@1+ (1,0) [0|1] "" Vector__XXX
 SG_ VCU_Canlife : 0|4@1+ (1,0) [0|15] "" Vector__XXX
 SG_ VCU_MainRelay : 0|1@1+ (1,0) [0|1] "" Vector__XXX
 SG_ VCU_PreChargedStatus : 0|1@1+ (1,0) [0|1] "" Vector__XXX
 SG_ VCU_Discharge : 0|1@1+ (1,0) [0|1] "" Vector__XXX
 SG_ VCU_Enable : 0|1@1+ (1,0) [0|1] "" Vector__XXX
 SG_ VCU_SpdReq : 0|16@1+ (1,-32000) [-32000|33535] "rpm" Vector__XXX
 SG_ VCU_TrqReq : 0|16@1+ (0.1,-3200) [-3200|3353.5] "Nm" Vector__XXX
 SG_ D_BMS_DOD : 0|10@1+ (0.1,0) [0|102.3] "%" Vector__XXX
 SG_ D_BMS_Serial_number : 0|16@1+ (1,0) [0|65535] "" Vector__XXX
 SG_ D_BMS_Rank_3_Fault : 0|8@1+ (1,0) [0|255] "" Vector__XXX
 SG_ D_BMS_Rank_2_Fault : 0|8@1+ (1,0) [0|255] "" Vector__XXX
 SG_ D_BMS_Rank_1_Fault : 0|8@1+ (1,0) [0|255] "" Vector__XXX
 SG_ C_BMS_DOD : 0|10@1+ (0.1,0) [0|102.3] "%" Vector__XXX
 SG_ C_BMS_Serial_number : 0|16@1+ (1,0) [0|65535] "" Vector__XXX
 SG_ C_BMS_Rank_3_Fault : 0|8@1+ (1,0) [0|255] "" Vector__XXX
 SG_ C_BMS_Rank_2_Fault : 0|8@1+ (1,0) [0|255] "" Vector__XXX
 SG_ C_BMS_Rank_1_Fault : 0|8@1+ (1,0) [0|255] "" Vector__XXX
 SG_ B_BMS_DOD : 0|10@1+ (0.1,0) [0|102.3] "%" Vector__XXX
 SG_ B_BMS_Serial_number : 0|16@1+ (1,0) [0|65535] "" Vector__XXX
 SG_ B_BMS_Rank_3_Fault : 0|8@1+ (1,0) [0|255] "" Vector__XXX
 SG_ B_BMS_Rank_2_Fault : 0|8@1+ (1,0) [0|255] "" Vector__XXX
 SG_ B_BMS_Rank_1_Fault : 0|8@1+ (1,0) [0|255] "" Vector__XXX
 SG_ A_BMS_DOD : 0|10@1+ (0.1,0) [0|102.3] "%" Vector__XXX
 SG_ A_BMS_Serial_number : 0|16@1+ (1,0) [0|65535] "" Vector__XXX
 SG_ A_BMS_Rank_3_Fault : 0|8@1+ (1,0) [0|255] "" Vector__XXX
 SG_ A_BMS_Rank_2_Fault : 0|8@1+ (1,0) [0|255] "" Vector__XXX
 SG_ A_BMS_Rank_1_Fault : 0|8@1+ (1,0) [0|255] "" Vector__XXX
 SG_ D_BMS_Accu_Regen_Energy : 0|21@1+ (0.1,0) [0|209714] "KWh" Vector__XXX
 SG_ D_BMS_Accu_Dischg_Energy : 0|21@1+ (0.1,0) [0|209714] "KWh" Vector__XXX
 SG_ D_BMS_Accu_Chrg_Energy : 0|21@1+ (0.1,0) [0|209714] "KWh" Vector__XXX
 SG_ C_BMS_Accu_Regen_Energy : 0|21@1+ (0.1,0) [0|209714] "KWh" Vector__XXX
 SG_ C_BMS_Accu_Dischg_Energy : 0|21@1+ (0.1,0) [0|209714] "KWh" Vector__XXX
 SG_ C_BMS_Accu_Chrg_Energy : 0|21@1+ (0.1,0) [0|209714] "KWh" Vector__XXX
 SG_ B_BMS_Accu_Regen_Energy : 0|21@1+ (0.1,0) [0|209714] "KWh" Vector__XXX
 SG_ B_BMS_Accu_Dischg_Energy : 0|21@1+ (0.1,0) [0|209714] "KWh" Vector__XXX
 SG_ B_BMS_Accu_Chrg_Energy : 0|21@1+ (0.1,0) [0|209714] "KWh" Vector__XXX
 SG_ A_BMS_Accu_Regen_Energy : 0|21@1+ (0.1,0) [0|209714] "KWh" Vector__XXX
 SG_ A_BMS_Accu_Dischg_Energy : 0|21@1+ (0.1,0) [0|209714] "KWh" Vector__XXX
 SG_ A_BMS_Accu_Chrg_Energy : 0|21@1+ (0.1,0) [0|209714] "KWh" Vector__XXX
 SG_ Local_hour_offser : 0|8@1+ (1,-125) [-125|125] "hr" Vector__XXX
 SG_ Local_minute_offset : 0|8@1+ (1,-125) [-125|130] "min" Vector__XXX
 SG_ Year : 0|8@1+ (1,1985) [1985|2235] "year" Vector__XXX
 SG_ Day : 0|8@1+ (0.25,0) [0|62.5] "day" Vector__XXX
 SG_ Month : 0|8@1+ (1,0) [0|250] "month" Vector__XXX
 SG_ Hours : 0|8@1+ (1,0) [0|250] "hr" Vector__XXX
 SG_ Minutes : 0|8@1+ (1,0) [0|255] "mins" Vector__XXX
 SG_ Seconds : 0|8@1+ (0.25,0) [0|62.5] "sec" Vector__XXX
 SG_ VCU_CRC : 0|8@1+ (1,0) [0|255] "" Vector__XXX
 SG_ VCU_RC : 0|4@1+ (1,0) [0|7] "" Vector__XXX
 SG_ VCU_BMS_No_of_Packs : 0|3@1+ (1,0) [0|4] "" Vector__XXX
 SG_ VCU_Busbar_Voltage : 0|16@1+ (0.02,0) [0|1000] "V" Vector__XXX
 SG_ Reserved : 0|1@1+ (1,0) [0|1] "" Vector__XXX
 SG_ VCU_BMS_Response_CRC_Fail : 0|1@1+ (1,0) [0|1] "" Vector__XXX
 SG_ VCU_BMS_Charge_Flag : 0|1@1+ (1,0) [0|1] "" Vector__XXX
 SG_ VCU_BMS_Insulation_Enable : 0|1@1+ (1,0) [0|1] "" Vector__XXX
 SG_ VCU_BMS_MainC_Close : 0|1@1+ (1,0) [0|1] "" Vector__XXX
 SG_ VCU_BMS_EPO : 0|1@1+ (1,0) [0|1] "" Vector__XXX
 SG_ VCU_BMS_Enable : 0|1@1+ (1,0) [0|1] "" Vector__XXX
 SG_ A_BMS_Smoke_Concentration : 0|14@1+ (1,0) [0|16383] "ug/m3" Vector__XXX
 SG_ A_BMS_Smoke_Sensor_Status : 0|5@1+ (1,0) [0|31] "" Vector__XXX
 SG_ A_BMS_IR_Value_Neg : 0|14@1+ (1,0) [0|12000] "kOhm" Vector__XXX
 SG_ A_BMS_IR_Value_Pos : 0|14@1+ (1,0) [0|12000] "kOhm" Vector__XXX
 SG_ A_BMS_Insulation_Value : 0|14@1+ (1,0) [0|12000] "kOhm" Vector__XXX
 SG_ A_BMS_Cell_Temp_N_plus_5 : 0|8@1+ (1,-40) [-40|215] "DegC" Vector__XXX
 SG_ A_BMS_Cell_Temp_N_plus_4 : 0|8@1+ (1,-40) [-40|215] "DegC" Vector__XXX
 SG_ A_BMS_Cell_Temp_N_plus_3 : 0|8@1+ (1,-40) [-40|215] "DegC" Vector__XXX
 SG_ A_BMS_Cell_Temp_N_plus_2 : 0|8@1+ (1,-40) [-40|215] "DegC" Vector__XXX
 SG_ A_BMS_Cell_Temp_N_plus_1 : 0|8@1+ (1,-40) [-40|215] "DegC" Vector__XXX
 SG_ A_BMS_Cell_Temp_N : 0|8@1+ (1,-40) [-40|215] "DegC" Vector__XXX
 SG_ A_BMS_Mux_Temp_Data_Counter : 0|3@1+ (1,0) [0|7] "" Vector__XXX
 SG_ A_BMS_CRC_18FFF1F3 : 0|8@1+ (1,0) [0|255] "" Vector__XXX
 SG_ A_BMS_Counter_18FFF1F3 : 0|4@1+ (1,0) [0|7] "" Vector__XXX
 SG_ A_BMS_P2P_Comm_Status4 : 0|1@1+ (1,0) [0|1] "" Vector__XXX
 SG_ A_BMS_P2P_Comm_Status3 : 0|1@1+ (1,0) [0|1] "" Vector__XXX
 SG_ A_BMS_P2P_Comm_Status2 : 0|1@1+ (1,0) [0|1] "" Vector__XXX
 SG_ A_BMS_P2P_Comm_Status1 : 0|1@1+ (1,0) [0|1] "" Vector__XXX
 SG_ A_BMS_CCL_Derate : 0|2@1+ (1,0) [0|3] "" Vector__XXX
 SG_ A_BMS_Pack_Voltage : 0|13@1+ (0.1,0) [0|800] "V" Vector__XXX
 SG_ A_BMS_Abs_Current : 0|14@1+ (0.1,0) [0|1638] "A" Vector__XXX
 SG_ A_BMS_Pack_No : 0|4@1+ (1,0) [0|15] "" Vector__XXX
 SG_ A_BMS_Oper_Mode : 0|4@1+ (1,0) [0|15] "" Vector__XXX
 SG_ A_BMS_IR_Measure_Seq : 0|3@1+ (1,0) [0|7] "" Vector__XXX
 SG_ A_BMS_CRC_CFF32F3 : 0|8@1+ (1,0) [0|255] "" Vector__XXX
 SG_ A_BMS_Counter_CFF32F3 : 0|4@1+ (1,0) [0|7] "" Vector__XXX
 SG_ A_BMS_Total_No_Cells : 0|8@1+ (1,0) [0|255] "" Vector__XXX
 SG_ A_BMS_Total_Energy : 0|10@1+ (0.1,0) [0|102.3] "Kwh" Vector__XXX
 SG_ A_BMS_Nominal_Capacity : 0|8@1+ (1,0) [0|255] "Ah" Vector__XXX
 SG_ A_BMS_Nominal_Voltage : 0|10@1+ (1,0) [0|1000] "V" Vector__XXX
 SG_ A_BMS_SW_Version : 0|16@1+ (1,0) [0|65535] "" Vector__XXX
 SG_ A_BMS_CRC_CFF43F3 : 0|8@1+ (1,0) [0|255] "" Vector__XXX
 SG_ A_BMS_Counter_CFF43F3 : 0|4@1+ (1,0) [0|7] "" Vector__XXX
 SG_ A_BMS_Slave_Rolling_Counter : 0|4@1+ (1,0) [0|7] "" Vector__XXX
 SG_ A_BMS_Slave_Comm_Status : 0|1@1+ (1,0) [0|1] "" Vector__XXX
 SG_ A_BMS_Slave_Vsense_Status : 0|1@1+ (1,0) [0|1] "" Vector__XXX
 SG_ A_BMS_Slave_AFE_Status : 0|1@1+ (1,0) [0|1] "" Vector__XXX
 SG_ A_BMS_Slave_LV_Supply : 0|9@1+ (0.1,0) [0|40] "V" Vector__XXX
 SG_ A_BMS_Slave_SW_Version : 0|16@1+ (1,0) [0|65535] "" Vector__XXX
 SG_ A_BMS_Slave_No : 0|2@1+ (1,0) [0|2] "" Vector__XXX
 SG_ A_BMS_Remain_Energy : 0|10@1+ (0.1,0) [0|102.3] "kwh" Vector__XXX
 SG_ A_BMS_CRC_CFF8FF3 : 0|8@1+ (1,0) [0|255] "" Vector__XXX
 SG_ A_BMS_Counter_CFF8FF3 : 0|4@1+ (1,0) [0|7] "" Vector__XXX
 SG_ A_BMS_SOC_Diff_Value : 0|10@1+ (0.1,0) [0|100] "%" Vector__XXX
 SG_ A_BMS_SOCCal_Flag : 0|8@1+ (1,0) [0|255] "" Vector__XXX
 SG_ A_BMS_Real_SOC : 0|10@1+ (0.1,0) [0|100] "%" Vector__XXX
 SG_ A_BMS_User_SOC : 0|10@1+ (0.1,0) [0|100] "%" Vector__XXX
 SG_ A_BMS_Smoke_Sensor_RC : 0|4@1+ (1,0) [0|15] "" Vector__XXX
 SG_ A_BMS_Coolant_Leak_Value : 0|12@1+ (1,0) [0|4095] "" Vector__XXX
 SG_ A_BMS_Vsense_Loose_No : 0|8@1+ (1,0) [0|255] "" Vector__XXX
 SG_ A_BMS_DTC_Code : 0|8@1+ (1,0) [0|255] "" Vector__XXX
 SG_ A_BMS_MapAccumAhSoh : 0|20@1+ (1,1) [1|1048575] "Ah" Vector__XXX
 SG_ A_BMS_SOH_Value : 0|10@1+ (0.1,0) [0|100] "%" Vector__XXX
 SG_ A_BMS_Coolant_Temp_Diff : 0|8@1+ (1,0) [0|255] "degC" Vector__XXX
 SG_ A_BMS_Cell_Temp_Diff : 0|8@1+ (1,0) [0|255] "degC" Vector__XXX
 SG_ A_BMS_Coolant_Temp_Out : 0|8@1+ (1,-40) [-40|215] "DegC" Vector__XXX
 SG_ A_BMS_Coolant_Temp_In : 0|8@1+ (1,-40) [-40|215] "DegC" Vector__XXX
 SG_ A_BMS_Min_Cell_Temp_No : 0|8@1+ (1,0) [0|255] "" Vector__XXX
 SG_ A_BMS_Max_Cell_Temp_No : 0|8@1+ (1,0) [0|255] "" Vector__XXX
 SG_ A_BMS_Min_Cell_Temp : 0|8@1+ (1,-40) [-40|215] "DegC" Vector__XXX
 SG_ A_BMS_Max_Cell_Temp : 0|8@1+ (1,-40) [-40|215] "DegC" Vector__XXX
 SG_ A_BMS_Cell_Volt_Diff : 0|13@1+ (1,0) [0|5000] "mV" Vector__XXX
 SG_ A_BMS_Min_Cell_Volt_No : 0|8@1+ (1,0) [0|255] "" Vector__XXX
 SG_ A_BMS_Max_Cell_Volt_No : 0|8@1+ (1,0) [0|255] "" Vector__XXX
 SG_ A_BMS_Min_Cell_Volt : 0|13@1+ (0.001,0) [0|5] "V" Vector__XXX
 SG_ A_BMS_Max_Cell_Volt : 0|13@1+ (0.001,0) [0|5] "V" Vector__XXX
 SG_ A_BMS_CRC_18FFF0F3 : 0|8@1+ (1,0) [0|255] "" Vector__XXX
 SG_ A_BMS_Counter_18FFF0F3 : 0|4@1+ (1,0) [0|7] "" Vector__XXX
 SG_ A_BMS_BMS_Cell_Sum_Volt : 0|13@1+ (0.1,0) [0|800] "V" Vector__XXX
 SG_ A_BMS_Pack_Voltage_V2 : 0|13@1+ (0.001,0) [0|5] "V" Vector__XXX
 SG_ A_BMS_Pack_Voltage_V3 : 0|13@1+ (0.1,0) [0|800] "V" Vector__XXX
 SG_ A_BMS_Pack_Voltage_V1 : 0|13@1+ (0.1,0) [0|800] "V" Vector__XXX
 SG_ A_BMS_CRC_CFF8BF3 : 0|8@1+ (1,0) [0|255] "" Vector__XXX
 SG_ A_BMS_Counter_CFF8BF3 : 0|4@1+ (1,0) [0|7] "" Vector__XXX
 SG_ A_BMS_Chrg_Curr_Limit : 0|16@1+ (0.1,0) [0|6553] "A" Vector__XXX
 SG_ A_BMS_Regen_Curr_Limit : 0|16@1+ (0.1,0) [0|6553] "A" Vector__XXX
 SG_ A_BMS_Dischg_Curr_Limit : 0|16@1+ (0.1,0) [0|6553] "A" Vector__XXX
 SG_ A_BMS_No_Pack_Feedback : 0|3@1+ (1,0) [0|4] "" Vector__XXX
 SG_ A_BMS_CRC_CFF8DF3 : 0|8@1+ (1,0) [0|255] "" Vector__XXX
 SG_ A_BMS_Counter_CFF8DF3 : 0|4@1+ (1,0) [0|7] "" Vector__XXX
 SG_ A_BMS_Balacing_Cell_No : 0|8@1+ (1,0) [0|255] "" Vector__XXX
 SG_ A_BMS_Balance_Enable_Flag : 0|1@1+ (1,0) [0|1] "" Vector__XXX
 SG_ A_BMS_Pack_Curr : 0|16@1+ (0.5,-1000) [-500|500] "A" Vector__XXX
 SG_ A_BMS_Fault_Rank : 0|3@1+ (1,0) [0|4] "" Vector__XXX
 SG_ A_BMS_Wake_Up_Source : 0|2@1+ (1,0) [0|2] "" Vector__XXX
 SG_ A_BMS_Key_Status : 0|1@1+ (1,0) [0|1] "" Vector__XXX
 SG_ A_BMS_IR_Enable_Flag : 0|1@1+ (1,0) [0|1] "" Vector__XXX
 SG_ A_BMS_LV_Power_Supply : 0|9@1+ (0.1,0) [0|40] "V" Vector__XXX
 SG_ A_BMS_Pre_Relay_Status : 0|1@1+ (1,0) [0|1] "" Vector__XXX
 SG_ A_BMS_Neg_Relay_Status : 0|1@1+ (1,0) [0|1] "" Vector__XXX
 SG_ A_BMS_Pos_Relay_Status : 0|1@1+ (1,0) [0|1] "" Vector__XXX
 SG_ A_BMS_HV_Circuit_Status : 0|2@1+ (1,0) [0|2] "" Vector__XXX
 SG_ A_BMS_HVIL_Status : 0|1@1+ (1,0) [0|1] "" Vector__XXX
 SG_ A_BMS_Charging_Done : 0|1@1+ (1,0) [0|1] "" Vector__XXX
 SG_ A_BMS_Pack_Ready : 0|1@1+ (1,0) [0|1] "" Vector__XXX
 SG_ B_BMS_Smoke_Concentration : 0|14@1+ (1,0) [0|16383] "ug/m3" Vector__XXX
 SG_ B_BMS_Smoke_Sensor_Status : 0|5@1+ (1,0) [0|31] "" Vector__XXX
 SG_ B_BMS_IR_Value_Neg : 0|14@1+ (1,0) [0|12000] "kOhm" Vector__XXX
 SG_ B_BMS_IR_Value_Pos : 0|14@1+ (1,0) [0|12000] "kOhm" Vector__XXX
 SG_ B_BMS_Insulation_Value : 0|14@1+ (1,0) [0|12000] "kOhm" Vector__XXX
 SG_ B_BMS_Cell_Temp_N_plus_5 : 0|8@1+ (1,-40) [-40|215] "DegC" Vector__XXX
 SG_ B_BMS_Cell_Temp_N_plus_4 : 0|8@1+ (1,-40) [-40|215] "DegC" Vector__XXX
 SG_ B_BMS_Cell_Temp_N_plus_3 : 0|8@1+ (1,-40) [-40|215] "DegC" Vector__XXX
 SG_ B_BMS_Cell_Temp_N_plus_2 : 0|8@1+ (1,-40) [-40|215] "DegC" Vector__XXX
 SG_ B_BMS_Cell_Temp_N_plus_1 : 0|8@1+ (1,-40) [-40|215] "DegC" Vector__XXX
 SG_ B_BMS_Cell_Temp_N : 0|8@1+ (1,-40) [-40|215] "DegC" Vector__XXX
 SG_ B_BMS_Mux_Temp_Data_Counter : 0|3@1+ (1,0) [0|7] "" Vector__XXX
 SG_ B_BMS_CRC_18FFF3F4 : 0|8@1+ (1,0) [0|255] "" Vector__XXX
 SG_ B_BMS_Counter_18FFF3F4 : 0|4@1+ (1,0) [0|7] "" Vector__XXX
 SG_ B_BMS_P2P_Comm_Status4 : 0|1@1+ (1,0) [0|1] "" Vector__XXX
 SG_ B_BMS_P2P_Comm_Status3 : 0|1@1+ (1,0) [0|1] "" Vector__XXX
 SG_ B_BMS_P2P_Comm_Status2 : 0|1@1+ (1,0) [0|1] "" Vector__XXX
 SG_ B_BMS_P2P_Comm_Status1 : 0|1@1+ (1,0) [0|1] "" Vector__XXX
 SG_ B_BMS_CCL_Derate : 0|2@1+ (1,0) [0|3] "" Vector__XXX
 SG_ B_BMS_Pack_Voltage : 0|13@1+ (0.1,0) [0|800] "V" Vector__XXX
 SG_ B_BMS_Abs_Current : 0|14@1+ (0.1,0) [0|1638] "A" Vector__XXX
 SG_ B_BMS_Pack_No : 0|4@1+ (1,0) [0|15] "" Vector__XXX
 SG_ B_BMS_Oper_Mode : 0|4@1+ (1,0) [0|15] "" Vector__XXX
 SG_ B_BMS_IR_Measure_Seq : 0|3@1+ (1,0) [0|7] "" Vector__XXX
 SG_ B_BMS_CRC_18FF38F4 : 0|8@1+ (1,0) [0|255] "" Vector__XXX
 SG_ B_BMS_Counter_18FF38F4 : 0|4@1+ (1,0) [0|7] "" Vector__XXX
 SG_ B_BMS_Total_No_Cells : 0|8@1+ (1,0) [0|255] "" Vector__XXX
 SG_ B_BMS_Total_Energy : 0|10@1+ (0.1,0) [0|102.3] "Kwh" Vector__XXX
 SG_ B_BMS_Nominal_Capacity : 0|8@1+ (1,0) [0|255] "Ah" Vector__XXX
 SG_ B_BMS_Nominal_Voltage : 0|10@1+ (1,0) [0|1000] "V" Vector__XXX
 SG_ B_BMS_SW_Version : 0|16@1+ (1,0) [0|65535] "" Vector__XXX
 SG_ B_BMS_CRC_CFFB5F4 : 0|8@1+ (1,0) [0|255] "" Vector__XXX
 SG_ B_BMS_Counter_CFFB5F4 : 0|4@1+ (1,0) [0|7] "" Vector__XXX
 SG_ B_BMS_Slave_Rolling_Counter : 0|4@1+ (1,0) [0|7] "" Vector__XXX
 SG_ B_BMS_Slave_Comm_Status : 0|1@1+ (1,0) [0|1] "" Vector__XXX
 SG_ B_BMS_Slave_Vsense_Status : 0|1@1+ (1,0) [0|1] "" Vector__XXX
 SG_ B_BMS_Slave_AFE_Status : 0|1@1+ (1,0) [0|1] "" Vector__XXX
 SG_ B_BMS_Slave_LV_Supply : 0|9@1+ (0.1,0) [0|40] "V" Vector__XXX
 SG_ B_BMS_Slave_SW_Version : 0|16@1+ (1,0) [0|65535] "" Vector__XXX
 SG_ B_BMS_Slave_No : 0|2@1+ (1,0) [0|2] "" Vector__XXX
 SG_ B_BMS_Remain_Energy : 0|10@1+ (0.1,0) [0|102.3] "kwh" Vector__XXX
 SG_ B_BMS_CRC_CFFB3F4 : 0|8@1+ (1,0) [0|255] "" Vector__XXX
 SG_ B_BMS_Counter_CFFB3F4 : 0|4@1+ (1,0) [0|7] "" Vector__XXX
 SG_ B_BMS_SOC_Diff_Value : 0|10@1+ (0.1,0) [0|100] "%" Vector__XXX
 SG_ B_BMS_SOCCal_Flag : 0|8@1+ (1,0) [0|255] "" Vector__XXX
 SG_ B_BMS_Real_SOC : 0|10@1+ (0.1,0) [0|100] "%" Vector__XXX
 SG_ B_BMS_User_SOC : 0|10@1+ (0.1,0) [0|100] "%" Vector__XXX
 SG_ B_BMS_Smoke_Sensor_RC : 0|4@1+ (1,0) [0|15] "" Vector__XXX
 SG_ B_BMS_Coolant_Leak_Value : 0|12@1+ (1,0) [0|4095] "" Vector__XXX
 SG_ B_BMS_Vsense_Loose_No : 0|8@1+ (1,0) [0|255] "" Vector__XXX
 SG_ B_BMS_DTC_Code : 0|8@1+ (1,0) [0|255] "" Vector__XXX
 SG_ B_BMS_MapAccumAhSoh : 0|20@1+ (1,1) [1|1048575] "Ah" Vector__XXX
 SG_ B_BMS_SOH_Value : 0|10@1+ (0.1,0) [0|100] "%" Vector__XXX
 SG_ B_BMS_Coolant_Temp_Diff : 0|8@1+ (1,0) [0|255] "degC" Vector__XXX
 SG_ B_BMS_Cell_Temp_Diff : 0|8@1+ (1,0) [0|255] "degC" Vector__XXX
 SG_ B_BMS_Coolant_Temp_Out : 0|8@1+ (1,-40) [-40|215] "DegC" Vector__XXX
 SG_ B_BMS_Coolant_Temp_In : 0|8@1+ (1,-40) [-40|215] "DegC" Vector__XXX
 SG_ B_BMS_Min_Cell_Temp_No : 0|8@1+ (1,0) [0|255] "" Vector__XXX
 SG_ B_BMS_Max_Cell_Temp_No : 0|8@1+ (1,0) [0|255] "" Vector__XXX
 SG_ B_BMS_Min_Cell_Temp : 0|8@1+ (1,-40) [-40|215] "DegC" Vector__XXX
 SG_ B_BMS_Max_Cell_Temp : 0|8@1+ (1,-40) [-40|215] "DegC" Vector__XXX
 SG_ B_BMS_Cell_Volt_Diff : 0|13@1+ (1,0) [0|5000] "mV" Vector__XXX
 SG_ B_BMS_Min_Cell_Volt_No : 0|8@1+ (1,0) [0|255] "" Vector__XXX
 SG_ B_BMS_Max_Cell_Volt_No : 0|8@1+ (1,0) [0|255] "" Vector__XXX
 SG_ B_BMS_Min_Cell_Volt : 0|13@1+ (0.001,0) [0|5] "V" Vector__XXX
 SG_ B_BMS_Max_Cell_Volt : 0|13@1+ (0.001,0) [0|5] "V" Vector__XXX
 SG_ B_BMS_CRC_18FFF2F4 : 0|8@1+ (1,0) [0|255] "" Vector__XXX
 SG_ B_BMS_Counter_18FFF2F4 : 0|4@1+ (1,0) [0|7] "" Vector__XXX
 SG_ B_BMS_BMS_Cell_Sum_Volt : 0|13@1+ (0.1,0) [0|800] "V" Vector__XXX
 SG_ B_BMS_Pack_Voltage_V2 : 0|13@1+ (0.001,0) [0|5] "V" Vector__XXX
 SG_ B_BMS_Pack_Voltage_V3 : 0|13@1+ (0.1,0) [0|800] "V" Vector__XXX
 SG_ B_BMS_Pack_Voltage_V1 : 0|13@1+ (0.1,0) [0|800] "V" Vector__XXX
 SG_ B_BMS_CRC_CFFAFF4 : 0|8@1+ (1,0) [0|255] "" Vector__XXX
 SG_ B_BMS_Counter_CFFAFF4 : 0|4@1+ (1,0) [0|7] "" Vector__XXX
 SG_ B_BMS_Chrg_Curr_Limit : 0|16@1+ (0.1,0) [0|6553] "A" Vector__XXX
 SG_ B_BMS_Regen_Curr_Limit : 0|16@1+ (0.1,0) [0|6553] "A" Vector__XXX
 SG_ B_BMS_Dischg_Curr_Limit : 0|16@1+ (0.1,0) [0|6553] "A" Vector__XXX
 SG_ B_BMS_No_Pack_Feedback : 0|3@1+ (1,0) [0|4] "" Vector__XXX
 SG_ B_BMS_CRC_CFFB1F4 : 0|8@1+ (1,0) [0|255] "" Vector__XXX
 SG_ B_BMS_Counter_CFFB1F4 : 0|4@1+ (1,0) [0|7] "" Vector__XXX
 SG_ B_BMS_Balacing_Cell_No : 0|8@1+ (1,0) [0|255] "" Vector__XXX
 SG_ B_BMS_Balance_Enable_Flag : 0|1@1+ (1,0) [0|1] "" Vector__XXX
 SG_ B_BMS_Pack_Curr : 0|16@1+ (0.5,-1000) [-500|500] "A" Vector__XXX
 SG_ B_BMS_Fault_Rank : 0|3@1+ (1,0) [0|4] "" Vector__XXX
 SG_ B_BMS_Wake_Up_Source : 0|2@1+ (1,0) [0|2] "" Vector__XXX
 SG_ B_BMS_Key_Status : 0|1@1+ (1,0) [0|1] "" Vector__XXX
 SG_ B_BMS_IR_Enable_Flag : 0|1@1+ (1,0) [0|1] "" Vector__XXX
 SG_ B_BMS_LV_Power_Supply : 0|9@1+ (0.1,0) [0|40] "V" Vector__XXX
 SG_ B_BMS_Pre_Relay_Status : 0|1@1+ (1,0) [0|1] "" Vector__XXX
 SG_ B_BMS_Neg_Relay_Status : 0|1@1+ (1,0) [0|1] "" Vector__XXX
 SG_ B_BMS_Pos_Relay_Status : 0|1@1+ (1,0) [0|1] "" Vector__XXX
 SG_ B_BMS_HV_Circuit_Status : 0|2@1+ (1,0) [0|2] "" Vector__XXX
 SG_ B_BMS_HVIL_Status : 0|1@1+ (1,0) [0|1] "" Vector__XXX
 SG_ B_BMS_Charging_Done : 0|1@1+ (1,0) [0|1] "" Vector__XXX
 SG_ B_BMS_Pack_Ready : 0|1@1+ (1,0) [0|1] "" Vector__XXX
 SG_ C_BMS_Smoke_Concentration : 0|14@1+ (1,0) [0|16383] "ug/m3" Vector__XXX
 SG_ C_BMS_Smoke_Sensor_Status : 0|5@1+ (1,0) [0|31] "" Vector__XXX
 SG_ C_BMS_IR_Value_Neg : 0|14@1+ (1,0) [0|12000] "kOhm" Vector__XXX
 SG_ C_BMS_IR_Value_Pos : 0|14@1+ (1,0) [0|12000] "kOhm" Vector__XXX
 SG_ C_BMS_Insulation_Value : 0|14@1+ (1,0) [0|12000] "kOhm" Vector__XXX
 SG_ C_BMS_Cell_Temp_N_plus_5 : 0|8@1+ (1,-40) [-40|215] "DegC" Vector__XXX
 SG_ C_BMS_Cell_Temp_N_plus_4 : 0|8@1+ (1,-40) [-40|215] "DegC" Vector__XXX
 SG_ C_BMS_Cell_Temp_N_plus_3 : 0|8@1+ (1,-40) [-40|215] "DegC" Vector__XXX
 SG_ C_BMS_Cell_Temp_N_plus_2 : 0|8@1+ (1,-40) [-40|215] "DegC" Vector__XXX
 SG_ C_BMS_Cell_Temp_N_plus_1 : 0|8@1+ (1,-40) [-40|215] "DegC" Vector__XXX
 SG_ C_BMS_Cell_Temp_N : 0|8@1+ (1,-40) [-40|215] "DegC" Vector__XXX
 SG_ C_BMS_Mux_Temp_Data_Counter : 0|3@1+ (1,0) [0|7] "" Vector__XXX
 SG_ C_BMS_CRC_18FFF1F5 : 0|8@1+ (1,0) [0|255] "" Vector__XXX
 SG_ C_BMS_Counter_18FFF1F5 : 0|4@1+ (1,0) [0|7] "" Vector__XXX
 SG_ C_BMS_P2P_Comm_Status4 : 0|1@1+ (1,0) [0|1] "" Vector__XXX
 SG_ C_BMS_P2P_Comm_Status3 : 0|1@1+ (1,0) [0|1] "" Vector__XXX
 SG_ C_BMS_P2P_Comm_Status2 : 0|1@1+ (1,0) [0|1] "" Vector__XXX
 SG_ C_BMS_P2P_Comm_Status1 : 0|1@1+ (1,0) [0|1] "" Vector__XXX
 SG_ C_BMS_CCL_Derate : 0|2@1+ (1,0) [0|3] "" Vector__XXX
 SG_ C_BMS_Pack_Voltage : 0|13@1+ (0.1,0) [0|800] "V" Vector__XXX
 SG_ C_BMS_Abs_Current : 0|14@1+ (0.1,0) [0|1638] "A" Vector__XXX
 SG_ C_BMS_Pack_No : 0|4@1+ (1,0) [0|15] "" Vector__XXX
 SG_ C_BMS_Oper_Mode : 0|4@1+ (1,0) [0|15] "" Vector__XXX
 SG_ C_BMS_IR_Measure_Seq : 0|3@1+ (1,0) [0|7] "" Vector__XXX
 SG_ C_BMS_CRC_CFF32F5 : 0|8@1+ (1,0) [0|255] "" Vector__XXX
 SG_ C_BMS_Counter_CFF32F5 : 0|4@1+ (1,0) [0|7] "" Vector__XXX
 SG_ C_BMS_Total_No_Cells : 0|8@1+ (1,0) [0|255] "" Vector__XXX
 SG_ C_BMS_Total_Energy : 0|10@1+ (0.1,0) [0|102.3] "Kwh" Vector__XXX
 SG_ C_BMS_Nominal_Capacity : 0|8@1+ (1,0) [0|255] "Ah" Vector__XXX
 SG_ C_BMS_Nominal_Voltage : 0|10@1+ (1,0) [0|1000] "V" Vector__XXX
 SG_ C_BMS_SW_Version : 0|16@1+ (1,0) [0|65535] "" Vector__XXX
 SG_ C_BMS_CRC_CFF43F5 : 0|8@1+ (1,0) [0|255] "" Vector__XXX
 SG_ C_BMS_Counter_CFF43F5 : 0|4@1+ (1,0) [0|7] "" Vector__XXX
 SG_ C_BMS_Slave_Rolling_Counter : 0|4@1+ (1,0) [0|7] "" Vector__XXX
 SG_ C_BMS_Slave_Comm_Status : 0|1@1+ (1,0) [0|1] "" Vector__XXX
 SG_ C_BMS_Slave_Vsense_Status : 0|1@1+ (1,0) [0|1] "" Vector__XXX
 SG_ C_BMS_Slave_AFE_Status : 0|1@1+ (1,0) [0|1] "" Vector__XXX
 SG_ C_BMS_Slave_LV_Supply : 0|9@1+ (0.1,0) [0|40] "V" Vector__XXX
 SG_ C_BMS_Slave_SW_Version : 0|16@1+ (1,0) [0|65535] "" Vector__XXX
 SG_ C_BMS_Slave_No : 0|2@1+ (1,0) [0|2] "" Vector__XXX
 SG_ C_BMS_Remain_Energy : 0|10@1+ (0.1,0) [0|102.3] "kwh" Vector__XXX
 SG_ C_BMS_CRC_CFF8FF5 : 0|8@1+ (1,0) [0|255] "" Vector__XXX
 SG_ C_BMS_Counter_CFF8FF5 : 0|4@1+ (1,0) [0|7] "" Vector__XXX
 SG_ C_BMS_SOC_Diff_Value : 0|10@1+ (0.1,0) [0|100] "%" Vector__XXX
 SG_ C_BMS_SOCCal_Flag : 0|8@1+ (1,0) [0|255] "" Vector__XXX
 SG_ C_BMS_Real_SOC : 0|10@1+ (0.1,0) [0|100] "%" Vector__XXX
 SG_ C_BMS_User_SOC : 0|10@1+ (0.1,0) [0|100] "%" Vector__XXX
 SG_ C_BMS_Smoke_Sensor_RC : 0|4@1+ (1,0) [0|15] "" Vector__XXX
 SG_ C_BMS_Coolant_Leak_Value : 0|12@1+ (1,0) [0|4095] "" Vector__XXX
 SG_ C_BMS_Vsense_Loose_No : 0|8@1+ (1,0) [0|255] "" Vector__XXX
 SG_ C_BMS_DTC_Code : 0|8@1+ (1,0) [0|255] "" Vector__XXX
 SG_ C_BMS_MapAccumAhSoh : 0|20@1+ (1,1) [1|1048575] "Ah" Vector__XXX
 SG_ C_BMS_SOH_Value : 0|10@1+ (0.1,0) [0|100] "%" Vector__XXX
 SG_ C_BMS_Coolant_Temp_Diff : 0|8@1+ (1,0) [0|255] "degC" Vector__XXX
 SG_ C_BMS_Cell_Temp_Diff : 0|8@1+ (1,0) [0|255] "degC" Vector__XXX
 SG_ C_BMS_Coolant_Temp_Out : 0|8@1+ (1,-40) [-40|215] "DegC" Vector__XXX
 SG_ C_BMS_Coolant_Temp_In : 0|8@1+ (1,-40) [-40|215] "DegC" Vector__XXX
 SG_ C_BMS_Min_Cell_Temp_No : 0|8@1+ (1,0) [0|255] "" Vector__XXX
 SG_ C_BMS_Max_Cell_Temp_No : 0|8@1+ (1,0) [0|255] "" Vector__XXX
 SG_ C_BMS_Min_Cell_Temp : 0|8@1+ (1,-40) [-40|215] "DegC" Vector__XXX
 SG_ C_BMS_Max_Cell_Temp : 0|8@1+ (1,-40) [-40|215] "DegC" Vector__XXX
 SG_ C_BMS_Cell_Volt_Diff : 0|13@1+ (1,0) [0|5000] "mV" Vector__XXX
 SG_ C_BMS_Min_Cell_Volt_No : 0|8@1+ (1,0) [0|255] "" Vector__XXX
 SG_ C_BMS_Max_Cell_Volt_No : 0|8@1+ (1,0) [0|255] "" Vector__XXX
 SG_ C_BMS_Min_Cell_Volt : 0|13@1+ (0.001,0) [0|5] "V" Vector__XXX
 SG_ C_BMS_Max_Cell_Volt : 0|13@1+ (0.001,0) [0|5] "V" Vector__XXX
 SG_ C_BMS_CRC_18FFF0F5 : 0|8@1+ (1,0) [0|255] "" Vector__XXX
 SG_ C_BMS_Counter_18FFF0F5 : 0|4@1+ (1,0) [0|7] "" Vector__XXX
 SG_ C_BMS_BMS_Cell_Sum_Volt : 0|13@1+ (0.1,0) [0|800] "V" Vector__XXX
 SG_ C_BMS_Pack_Voltage_V2 : 0|13@1+ (0.001,0) [0|5] "V" Vector__XXX
 SG_ C_BMS_Pack_Voltage_V3 : 0|13@1+ (0.1,0) [0|800] "V" Vector__XXX
 SG_ C_BMS_Pack_Voltage_V1 : 0|13@1+ (0.1,0) [0|800] "V" Vector__XXX
 SG_ C_BMS_CRC_CFF8DF3 : 0|8@1+ (1,0) [0|255] "" Vector__XXX
 SG_ C_BMS_Counter_CFF8BF5 : 0|4@1+ (1,0) [0|7] "" Vector__XXX
 SG_ C_BMS_Chrg_Curr_Limit : 0|16@1+ (0.1,0) [0|6553] "A" Vector__XXX
 SG_ C_BMS_Regen_Curr_Limit : 0|16@1+ (0.1,0) [0|6553] "A" Vector__XXX
 SG_ C_BMS_Dischg_Curr_Limit : 0|16@1+ (0.1,0) [0|6553] "A" Vector__XXX
 SG_ C_BMS_No_Pack_Feedback : 0|3@1+ (1,0) [0|4] "" Vector__XXX
 SG_ C_BMS_CRC_CFF8DF3 : 0|8@1+ (1,0) [0|255] "" Vector__XXX
 SG_ C_BMS_Counter_CFF8DF3 : 0|4@1+ (1,0) [0|7] "" Vector__XXX
 SG_ C_BMS_Balacing_Cell_No : 0|8@1+ (1,0) [0|255] "" Vector__XXX
 SG_ C_BMS_Balance_Enable_Flag : 0|1@1+ (1,0) [0|1] "" Vector__XXX
 SG_ C_BMS_Pack_Curr : 0|16@1+ (0.5,-1000) [-500|500] "A" Vector__XXX
 SG_ C_BMS_Fault_Rank : 0|3@1+ (1,0) [0|4] "" Vector__XXX
 SG_ C_BMS_Wake_Up_Source : 0|2@1+ (1,0) [0|2] "" Vector__XXX
 SG_ C_BMS_Key_Status : 0|1@1+ (1,0) [0|1] "" Vector__XXX
 SG_ C_BMS_IR_Enable_Flag : 0|1@1+ (1,0) [0|1] "" Vector__XXX
 SG_ C_BMS_LV_Power_Supply : 0|9@1+ (0.1,0) [0|40] "V" Vector__XXX
 SG_ C_BMS_Pre_Relay_Status : 0|1@1+ (1,0) [0|1] "" Vector__XXX
 SG_ C_BMS_Neg_Relay_Status : 0|1@1+ (1,0) [0|1] "" Vector__XXX
 SG_ C_BMS_Pos_Relay_Status : 0|1@1+ (1,0) [0|1] "" Vector__XXX
 SG_ C_BMS_HV_Circuit_Status : 0|2@1+ (1,0) [0|2] "" Vector__XXX
 SG_ C_BMS_HVIL_Status : 0|1@1+ (1,0) [0|1] "" Vector__XXX
 SG_ C_BMS_Charging_Done : 0|1@1+ (1,0) [0|1] "" Vector__XXX
 SG_ C_BMS_Pack_Ready : 0|1@1+ (1,0) [0|1] "" Vector__XXX
 SG_ D_BMS_Smoke_Concentration : 0|14@1+ (1,0) [0|16383] "ug/m3" Vector__XXX
 SG_ D_BMS_Smoke_Sensor_Status : 0|5@1+ (1,0) [0|31] "" Vector__XXX
 SG_ D_BMS_IR_Value_Neg : 0|14@1+ (1,0) [0|12000] "kOhm" Vector__XXX
 SG_ D_BMS_IR_Value_Pos : 0|14@1+ (1,0) [0|12000] "kOhm" Vector__XXX
 SG_ D_BMS_Insulation_Value : 0|14@1+ (1,0) [0|12000] "kOhm" Vector__XXX
 SG_ D_BMS_Cell_Temp_N_plus_5 : 0|8@1+ (1,-40) [-40|215] "DegC" Vector__XXX
 SG_ D_BMS_Cell_Temp_N_plus_4 : 0|8@1+ (1,-40) [-40|215] "DegC" Vector__XXX
 SG_ D_BMS_Cell_Temp_N_plus_3 : 0|8@1+ (1,-40) [-40|215] "DegC" Vector__XXX
 SG_ D_BMS_Cell_Temp_N_plus_2 : 0|8@1+ (1,-40) [-40|215] "DegC" Vector__XXX
 SG_ D_BMS_Cell_Temp_N_plus_1 : 0|8@1+ (1,-40) [-40|215] "DegC" Vector__XXX
 SG_ D_BMS_Cell_Temp_N : 0|8@1+ (1,-40) [-40|215] "DegC" Vector__XXX
 SG_ D_BMS_Mux_Temp_Data_Counter : 0|3@1+ (1,0) [0|7] "" Vector__XXX
 SG_ D_BMS_CRC_18FFF3F6 : 0|8@1+ (1,0) [0|255] "" Vector__XXX
 SG_ D_BMS_Counter_18FFF3F6 : 0|4@1+ (1,0) [0|7] "" Vector__XXX
 SG_ D_BMS_P2P_Comm_Status4 : 0|1@1+ (1,0) [0|1] "" Vector__XXX
 SG_ D_BMS_P2P_Comm_Status3 : 0|1@1+ (1,0) [0|1] "" Vector__XXX
 SG_ D_BMS_P2P_Comm_Status2 : 0|1@1+ (1,0) [0|1] "" Vector__XXX
 SG_ D_BMS_P2P_Comm_Status1 : 0|1@1+ (1,0) [0|1] "" Vector__XXX
 SG_ D_BMS_CCL_Derate : 0|2@1+ (1,0) [0|3] "" Vector__XXX
 SG_ D_BMS_Pack_Voltage : 0|13@1+ (0.1,0) [0|800] "V" Vector__XXX
 SG_ D_BMS_Abs_Current : 0|14@1+ (0.1,0) [0|1638] "A" Vector__XXX
 SG_ D_BMS_Pack_No : 0|4@1+ (1,0) [0|15] "" Vector__XXX
 SG_ D_BMS_Oper_Mode : 0|4@1+ (1,0) [0|15] "" Vector__XXX
 SG_ D_BMS_IR_Measure_Seq : 0|3@1+ (1,0) [0|7] "" Vector__XXX
 SG_ D_BMS_CRC_18FF38F6 : 0|8@1+ (1,0) [0|255] "" Vector__XXX
 SG_ D_BMS_Counter_18FF38F6 : 0|4@1+ (1,0) [0|7] "" Vector__XXX
 SG_ D_BMS_Total_No_Cells : 0|8@1+ (1,0) [0|255] "" Vector__XXX
 SG_ D_BMS_Total_Energy : 0|10@1+ (0.1,0) [0|102.3] "Kwh" Vector__XXX
 SG_ D_BMS_Nominal_Capacity : 0|8@1+ (1,0) [0|255] "Ah" Vector__XXX
 SG_ D_BMS_Nominal_Voltage : 0|10@1+ (1,0) [0|1000] "V" Vector__XXX
 SG_ D_BMS_SW_Version : 0|16@1+ (1,0) [0|65535] "" Vector__XXX
 SG_ D_BMS_CRC_CFFB5F6 : 0|8@1+ (1,0) [0|255] "" Vector__XXX
 SG_ D_BMS_Counter_CFFB5F6 : 0|4@1+ (1,0) [0|7] "" Vector__XXX
 SG_ D_BMS_Slave_Rolling_Counter : 0|4@1+ (1,0) [0|7] "" Vector__XXX
 SG_ D_BMS_Slave_Comm_Status : 0|1@1+ (1,0) [0|1] "" Vector__XXX
 SG_ D_BMS_Slave_Vsense_Status : 0|1@1+ (1,0) [0|1] "" Vector__XXX
 SG_ D_BMS_Slave_AFE_Status : 0|1@1+ (1,0) [0|1] "" Vector__XXX
 SG_ D_BMS_Slave_LV_Supply : 0|9@1+ (0.1,0) [0|40] "V" Vector__XXX
 SG_ D_BMS_Slave_SW_Version : 0|16@1+ (1,0) [0|65535] "" Vector__XXX
 SG_ D_BMS_Slave_No : 0|2@1+ (1,0) [0|2] "" Vector__XXX
 SG_ D_BMS_Remain_Energy : 0|10@1+ (0.1,0) [0|102.3] "kwh" Vector__XXX
 SG_ D_BMS_CRC_CFFB3F6 : 0|8@1+ (1,0) [0|255] "" Vector__XXX
 SG_ D_BMS_Counter_CFFB3F6 : 0|4@1+ (1,0) [0|7] "" Vector__XXX
 SG_ D_BMS_SOC_Diff_Value : 0|10@1+ (0.1,0) [0|100] "%" Vector__XXX
 SG_ D_BMS_SOCCal_Flag : 0|8@1+ (1,0) [0|255] "" Vector__XXX
 SG_ D_BMS_Real_SOC : 0|10@1+ (0.1,0) [0|100] "%" Vector__XXX
 SG_ D_BMS_User_SOC : 0|10@1+ (0.1,0) [0|100] "%" Vector__XXX
 SG_ D_BMS_Smoke_Sensor_RC : 0|4@1+ (1,0) [0|15] "" Vector__XXX
 SG_ D_BMS_Coolant_Leak_Value : 0|12@1+ (1,0) [0|4095] "" Vector__XXX
 SG_ D_BMS_Vsense_Loose_No : 0|8@1+ (1,0) [0|255] "" Vector__XXX
 SG_ D_BMS_DTC_Code : 0|8@1+ (1,0) [0|255] "" Vector__XXX
 SG_ D_BMS_MapAccumAhSoh : 0|20@1+ (1,1) [1|1048575] "Ah" Vector__XXX
 SG_ D_BMS_SOH_Value : 0|10@1+ (0.1,0) [0|100] "%" Vector__XXX
 SG_ D_BMS_Coolant_Temp_Diff : 0|8@1+ (1,0) [0|255] "degC" Vector__XXX
 SG_ D_BMS_Cell_Temp_Diff : 0|8@1+ (1,0) [0|255] "degC" Vector__XXX
 SG_ D_BMS_Coolant_Temp_Out : 0|8@1+ (1,-40) [-40|215] "DegC" Vector__XXX
 SG_ D_BMS_Coolant_Temp_In : 0|8@1+ (1,-40) [-40|215] "DegC" Vector__XXX
 SG_ D_BMS_Min_Cell_Temp_No : 0|8@1+ (1,0) [0|255] "" Vector__XXX
 SG_ D_BMS_Max_Cell_Temp_No : 0|8@1+ (1,0) [0|255] "" Vector__XXX
 SG_ D_BMS_Min_Cell_Temp : 0|8@1+ (1,-40) [-40|215] "DegC" Vector__XXX
 SG_ D_BMS_Max_Cell_Temp : 0|8@1+ (1,-40) [-40|215] "DegC" Vector__XXX
 SG_ D_BMS_Cell_Volt_Diff : 0|13@1+ (1,0) [0|5000] "mV" Vector__XXX
 SG_ D_BMS_Min_Cell_Volt_No : 0|8@1+ (1,0) [0|255] "" Vector__XXX
 SG_ D_BMS_Max_Cell_Volt_No : 0|8@1+ (1,0) [0|255] "" Vector__XXX
 SG_ D_BMS_Min_Cell_Volt : 0|13@1+ (0.001,0) [0|5] "V" Vector__XXX
 SG_ D_BMS_Max_Cell_Volt : 0|13@1+ (0.001,0) [0|5] "V" Vector__XXX
 SG_ D_BMS_CRC_18FFF2F6 : 0|8@1+ (1,0) [0|255] "" Vector__XXX
 SG_ D_BMS_Counter_18FFF2F6 : 0|4@1+ (1,0) [0|7] "" Vector__XXX
 SG_ D_BMS_BMS_Cell_Sum_Volt : 0|13@1+ (0.1,0) [0|800] "V" Vector__XXX
 SG_ D_BMS_Pack_Voltage_V2 : 0|13@1+ (0.001,0) [0|5] "V" Vector__XXX
 SG_ D_BMS_Pack_Voltage_V3 : 0|13@1+ (0.1,0) [0|800] "V" Vector__XXX
 SG_ D_BMS_Pack_Voltage_V1 : 0|13@1+ (0.1,0) [0|800] "V" Vector__XXX
 SG_ D_BMS_CRC_CFFAFF6 : 0|8@1+ (1,0) [0|255] "" Vector__XXX
 SG_ D_BMS_Counter_CFFAFF6 : 0|4@1+ (1,0) [0|7] "" Vector__XXX
 SG_ D_BMS_Chrg_Curr_Limit : 0|16@1+ (0.1,0) [0|6553] "A" Vector__XXX
 SG_ D_BMS_Regen_Curr_Limit : 0|16@1+ (0.1,0) [0|6553] "A" Vector__XXX
 SG_ D_BMS_Dischg_Curr_Limit : 0|16@1+ (0.1,0) [0|6553] "A" Vector__XXX
 SG_ D_BMS_No_Pack_Feedback : 0|3@1+ (1,0) [0|4] "" Vector__XXX
 SG_ D_BMS_CRC_CFFB1F6 : 0|8@1+ (1,0) [0|255] "" Vector__XXX
 SG_ D_BMS_Counter_CFFB1F6 : 0|4@1+ (1,0) [0|7] "" Vector__XXX
 SG_ D_BMS_Balacing_Cell_No : 0|8@1+ (1,0) [0|255] "" Vector__XXX
 SG_ D_BMS_Balance_Enable_Flag : 0|1@1+ (1,0) [0|1] "" Vector__XXX
 SG_ D_BMS_Pack_Curr : 0|16@1+ (0.5,-1000) [-500|500] "A" Vector__XXX
 SG_ D_BMS_Fault_Rank : 0|3@1+ (1,0) [0|4] "" Vector__XXX
 SG_ D_BMS_Wake_Up_Source : 0|2@1+ (1,0) [0|2] "" Vector__XXX
 SG_ D_BMS_Key_Status : 0|1@1+ (1,0) [0|1] "" Vector__XXX
 SG_ D_BMS_IR_Enable_Flag : 0|1@1+ (1,0) [0|1] "" Vector__XXX
 SG_ D_BMS_LV_Power_Supply : 0|9@1+ (0.1,0) [0|40] "V" Vector__XXX
 SG_ D_BMS_Pre_Relay_Status : 0|1@1+ (1,0) [0|1] "" Vector__XXX
 SG_ D_BMS_Neg_Relay_Status : 0|1@1+ (1,0) [0|1] "" Vector__XXX
 SG_ D_BMS_Pos_Relay_Status : 0|1@1+ (1,0) [0|1] "" Vector__XXX
 SG_ D_BMS_HV_Circuit_Status : 0|2@1+ (1,0) [0|2] "" Vector__XXX
 SG_ D_BMS_HVIL_Status : 0|1@1+ (1,0) [0|1] "" Vector__XXX
 SG_ D_BMS_Charging_Done : 0|1@1+ (1,0) [0|1] "" Vector__XXX
 SG_ D_BMS_Pack_Ready : 0|1@1+ (1,0) [0|1] "" Vector__XXX

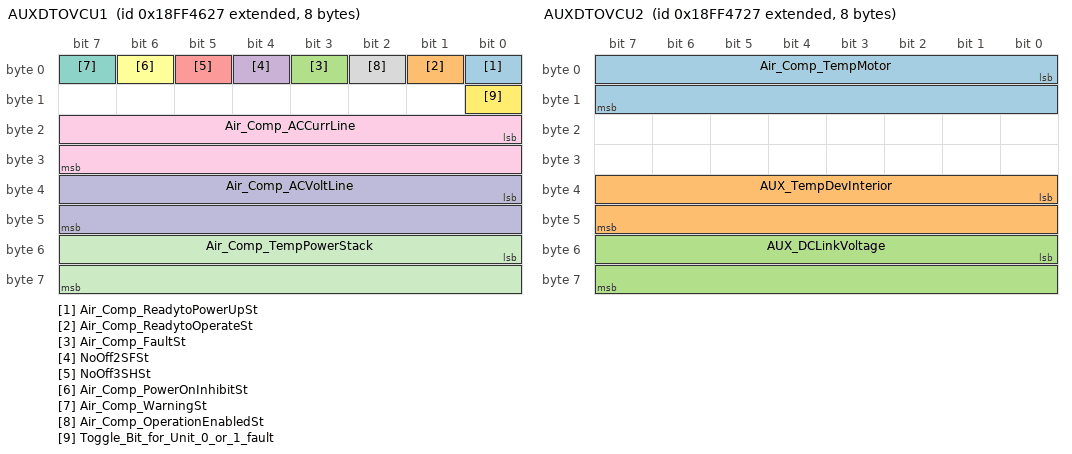
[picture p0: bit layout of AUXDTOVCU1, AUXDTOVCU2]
BO_ 2566866471 AUXDTOVCU1: 8 Vector__XXX
 SG_ Air_Comp_ReadytoPowerUpSt : 0|1@1+ (1,0) [0|1] "" Vector__XXX
 SG_ Air_Comp_ReadytoOperateSt : 1|1@1+ (1,0) [0|1] "" Vector__XXX
 SG_ Air_Comp_FaultSt : 3|1@1+ (1,0) [0|1] "" Vector__XXX
 SG_ NoOff2SFSt : 4|1@1+ (1,0) [0|1] "" Vector__XXX
 SG_ NoOff3SHSt : 5|1@1+ (1,0) [0|1] "" Vector__XXX
 SG_ Air_Comp_PowerOnInhibitSt : 6|1@1+ (1,0) [0|1] "" Vector__XXX
 SG_ Air_Comp_WarningSt : 7|1@1+ (1,0) [0|1] "" Vector__XXX
 SG_ Air_Comp_OperationEnabledSt : 2|1@1+ (1,0) [0|1] "" Vector__XXX
 SG_ Air_Comp_ACCurrLine : 16|16@1- (1,0) [-3276.8|3276.7] "A" Vector__XXX
 SG_ Air_Comp_ACVoltLine : 32|16@1- (1,0) [-3276.8|3276.7] "V" Vector__XXX
 SG_ Air_Comp_TempPowerStack : 48|16@1- (0.1,0) [-3276.8|3276.7] "degC" Vector__XXX
 SG_ Toggle_Bit_for_Unit_0_or_1_fault : 8|1@1+ (1,0) [0|1] "" Vector__XXX

BO_ 2566866727 AUXDTOVCU2: 8 Vector__XXX
 SG_ Air_Comp_TempMotor : 0|16@1- (0.1,0) [-3276.8|3276.7] "degC" Vector__XXX
 SG_ AUX_TempDevInterior : 32|16@1- (0.1,0) [-3276.8|3276.7] "degC" Vector__XXX
 SG_ AUX_DCLinkVoltage : 48|16@1- (1,0) [-32767.9|32767] "" Vector__XXX

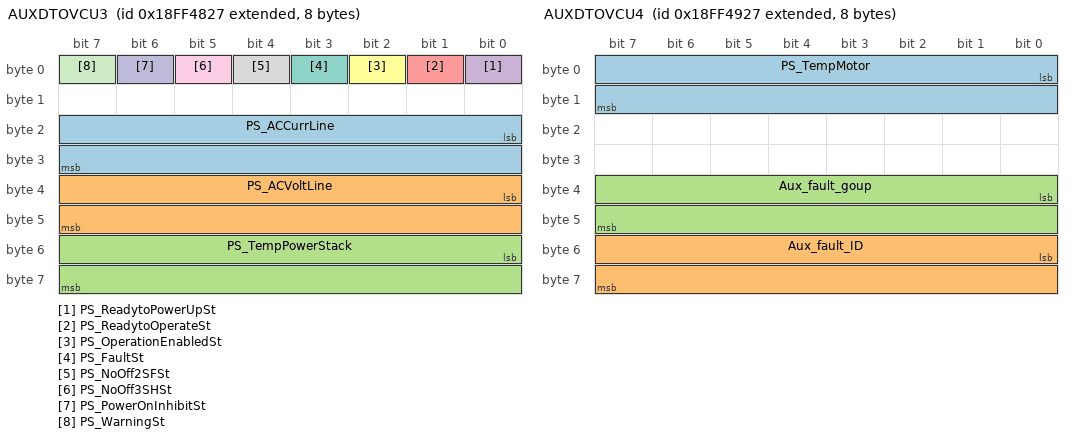
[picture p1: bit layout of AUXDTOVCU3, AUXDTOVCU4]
BO_ 2566866983 AUXDTOVCU3: 8 Vector__XXX
 SG_ PS_ACCurrLine : 16|16@1- (1,0) [-3276.8|3276.7] "A" Vector__XXX
 SG_ PS_ACVoltLine : 32|16@1- (1,0) [-3276.8|3276.7] "V" Vector__XXX
 SG_ PS_TempPowerStack : 48|16@1- (0.1,0) [-3276.8|3276.7] "degC" Vector__XXX
 SG_ PS_ReadytoPowerUpSt : 0|1@1+ (1,0) [0|1] "" Vector__XXX
 SG_ PS_ReadytoOperateSt : 1|1@1+ (1,0) [0|1] "" Vector__XXX
 SG_ PS_OperationEnabledSt : 2|1@1+ (1,0) [0|1] "" Vector__XXX
 SG_ PS_FaultSt : 3|1@1+ (1,0) [0|1] "" Vector__XXX
 SG_ PS_NoOff2SFSt : 4|1@1+ (1,0) [0|1] "" Vector__XXX
 SG_ PS_NoOff3SHSt : 5|1@1+ (1,0) [0|1] "" Vector__XXX
 SG_ PS_PowerOnInhibitSt : 6|1@1+ (1,0) [0|1] "" Vector__XXX
 SG_ PS_WarningSt : 7|1@1+ (1,0) [0|1] "" Vector__XXX

BO_ 2566867239 AUXDTOVCU4: 8 Vector__XXX
 SG_ PS_TempMotor : 0|16@1- (0.1,0) [-3276.8|3276.7] "degC" Vector__XXX
 SG_ Aux_fault_ID : 48|16@1+ (1,0) [0|65535] "" Vector__XXX
 SG_ Aux_fault_goup : 32|16@1+ (1,0) [0|65535] "" Vector__XXX

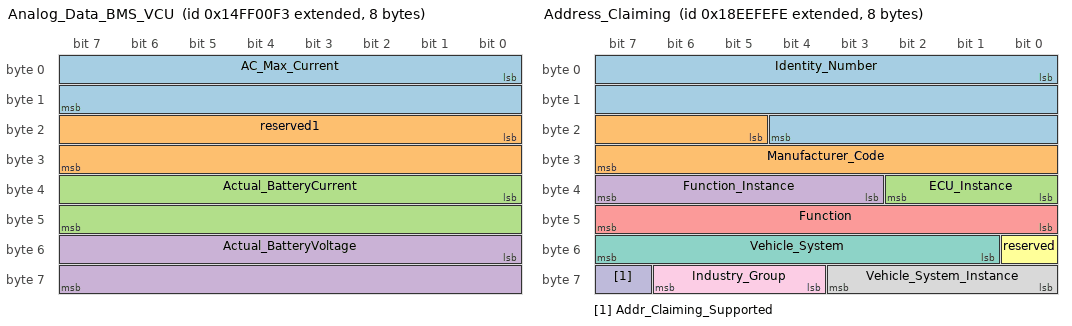
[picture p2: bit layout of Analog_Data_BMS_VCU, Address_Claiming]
BO_ 2499739891 Analog_Data_BMS_VCU: 8 Vector__XXX
 SG_ AC_Max_Current : 0|16@1+ (0.1,-3212.7) [-3212.7|3212.8] "A" Vector__XXX
 SG_ reserved1 : 16|16@1+ (1,0) [0|65535] "" Vector__XXX
 SG_ Actual_BatteryCurrent : 32|16@1+ (0.1,-3212.7) [-3212.7|3212.8] "A" Vector__XXX
 SG_ Actual_BatteryVoltage : 48|16@1+ (0.1,-3212.7) [-3212.7|3212.8] "V" Vector__XXX

BO_ 2565799678 Address_Claiming: 8 Vector__XXX
 SG_ Identity_Number : 0|21@1+ (1,0) [0|1048575] "" Vector__XXX
 SG_ Manufacturer_Code : 21|11@1+ (1,0) [0|2047] "" Vector__XXX
 SG_ ECU_Instance : 32|3@1+ (1,0) [0|3] "" Vector__XXX
 SG_ Function_Instance : 35|5@1+ (1,0) [0|15] "" Vector__XXX
 SG_ Function : 40|8@1+ (1,0) [0|127] "" Vector__XXX
 SG_ reserved : 48|1@1+ (1,0) [0|1] "" Vector__XXX
 SG_ Vehicle_System : 49|7@1+ (1,0) [0|63] "" Vector__XXX
 SG_ Vehicle_System_Instance : 56|4@1+ (1,0) [0|7] "" Vector__XXX
 SG_ Industry_Group : 60|3@1+ (1,0) [0|3] "" Vector__XXX
 SG_ Addr_Claiming_Supported : 63|1@1+ (1,0) [0|1] "" Vector__XXX

BO_ 2566857200 OBC_digital_data_1: 8 Vector__XXX
 SG_ EV_DisconnectingDevice_Status : 0|2@1+ (1,0) [0|3] "" Vector__XXX
 SG_ PLC_available : 6|2@1+ (1,0) [0|3] "" Vector__XXX
 SG_ CCS_AC_ContactTemp_Sens : 8|2@1+ (1,0) [0|3] "" Vector__XXX
 SG_ CCS_DC_ContactTempSens : 10|2@1+ (1,0) [0|3] "" Vector__XXX
 SG_ DC_charging_active : 12|2@1+ (1,0) [0|3] "" Vector__XXX
 SG_ CCS_PlugLockFailure : 14|2@1+ (1,0) [0|3] "" Vector__XXX
 SG_ Vac_InRange : 16|2@1+ (1,0) [0|3] "" Vector__XXX
 SG_ Fac_InRange : 18|2@1+ (1,0) [0|3] "" Vector__XXX
 SG_ AC_Mode : 20|2@1+ (1,0) [0|3] "" Vector__XXX
 SG_ DeratingVoltage : 22|2@1+ (1,0) [0|3] "" Vector__XXX
 SG_ reserved26 : 24|2@1+ (1,0) [0|3] "" Vector__XXX
 SG_ reserved27 : 26|2@1+ (1,0) [0|3] "" Vector__XXX
 SG_ PreChargeRelay_status : 28|2@1+ (1,0) [0|3] "" Vector__XXX
 SG_ MainRelay_status : 30|2@1+ (1,0) [0|3] "" Vector__XXX
 SG_ DeratingTemperature : 32|2@1+ (1,0) [0|3] "" Vector__XXX
 SG_ OBC_Availability : 34|2@1+ (1,0) [0|3] "" Vector__XXX
 SG_ InternalCAN_Error : 36|2@1+ (1,0) [0|3] "" Vector__XXX
 SG_ ChargeStopActive : 38|2@1+ (1,0) [0|3] "" Vector__XXX
 SG_ OBC1_StateAct : 40|4@1+ (1,0) [0|15] "" Vector__XXX
 SG_ OBC2_StateAct : 44|4@1+ (1,0) [0|15] "" Vector__XXX
 SG_ OBC3_StateAct : 48|4@1+ (1,0) [0|15] "" Vector__XXX
 SG_ OBC4_StateAct : 52|4@1+ (1,0) [0|15] "" Vector__XXX
 SG_ reserved28 : 56|4@1+ (1,0) [0|15] "" Vector__XXX
 SG_ reserved29 : 60|4@1+ (1,0) [0|15] "" Vector__XXX
 SG_ EV_DisconnectingDevPlus_Status : 2|2@1+ (1,0) [0|3] "" Vector__XXX
 SG_ EV_DisconnectingDevMinus_Status : 4|2@1+ (1,0) [0|3] "" Vector__XXX

BO_ 2566857456 OBC_digital_data_2: 8 Vector__XXX
 SG_ reserved30 : 0|4@1+ (1,0) [0|15] "" Vector__XXX
 SG_ reserved31 : 4|4@1+ (1,0) [0|15] "" Vector__XXX
 SG_ OBC1_Error : 8|2@1+ (1,0) [0|3] "" Vector__XXX
 SG_ OBC2_Error : 10|2@1+ (1,0) [0|3] "" Vector__XXX
 SG_ OBC3_Error : 12|2@1+ (1,0) [0|3] "" Vector__XXX
 SG_ OBC4_Error : 14|2@1+ (1,0) [0|3] "" Vector__XXX
 SG_ reserved32 : 16|2@1+ (1,0) [0|3] "" Vector__XXX
 SG_ reserved33 : 18|2@1+ (1,0) [0|3] "" Vector__XXX
 SG_ reserved34 : 20|2@1+ (1,0) [0|3] "" Vector__XXX
 SG_ reserved35 : 22|2@1+ (1,0) [0|3] "" Vector__XXX
 SG_ OBC1_OverTemp : 24|2@1+ (1,0) [0|3] "" Vector__XXX
 SG_ OBC2_OverTemp : 26|2@1+ (1,0) [0|3] "" Vector__XXX
 SG_ OBC3_OverTemp : 28|2@1+ (1,0) [0|3] "" Vector__XXX
 SG_ OBC4_OverTemp : 30|2@1+ (1,0) [0|3] "" Vector__XXX
 SG_ reserved36 : 32|2@1+ (1,0) [0|3] "" Vector__XXX
 SG_ reserved37 : 34|2@1+ (1,0) [0|3] "" Vector__XXX
 SG_ reserved38 : 36|2@1+ (1,0) [0|3] "" Vector__XXX
 SG_ reserved39 : 38|2@1+ (1,0) [0|3] "" Vector__XXX
 SG_ reserved40 : 40|8@1+ (1,0) [0|255] "" Vector__XXX
 SG_ reserved41 : 48|8@1+ (1,0) [0|255] "" Vector__XXX
 SG_ reserved42 : 56|8@1+ (1,0) [0|255] "" Vector__XXX

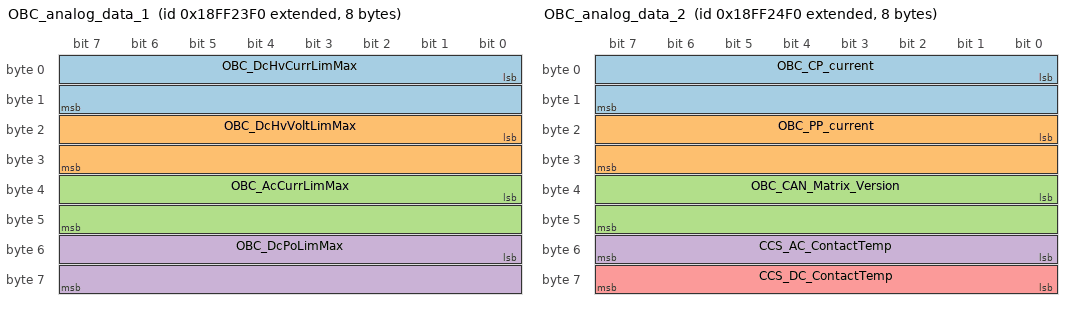
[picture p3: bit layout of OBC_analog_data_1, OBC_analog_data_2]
BO_ 2566857712 OBC_analog_data_1: 8 Vector__XXX
 SG_ OBC_DcHvCurrLimMax : 0|16@1+ (0.1,-3212.7) [-3212.7|3212.8] "A" Vector__XXX
 SG_ OBC_DcHvVoltLimMax : 16|16@1+ (0.1,-3212.7) [-3212.7|3212.8] "V" Vector__XXX
 SG_ OBC_AcCurrLimMax : 32|16@1+ (0.1,-3212.7) [-3212.7|3212.8] "A" Vector__XXX
 SG_ OBC_DcPoLimMax : 48|16@1+ (0.1,-3212.7) [-3212.7|3212.8] "kW" Vector__XXX

BO_ 2566857968 OBC_analog_data_2: 8 Vector__XXX
 SG_ OBC_CP_current : 0|16@1+ (0.1,-3212.7) [-3212.7|3212.8] "A" Vector__XXX
 SG_ OBC_PP_current : 16|16@1+ (0.1,-3212.7) [-3212.7|3212.8] "A" Vector__XXX
 SG_ OBC_CAN_Matrix_Version : 32|16@1+ (1,0) [0|65535] "" Vector__XXX
 SG_ CCS_AC_ContactTemp : 48|8@1+ (1,-40) [-40|215] "�C" Vector__XXX
 SG_ CCS_DC_ContactTemp : 56|8@1+ (1,-40) [-40|215] "�C" Vector__XXX

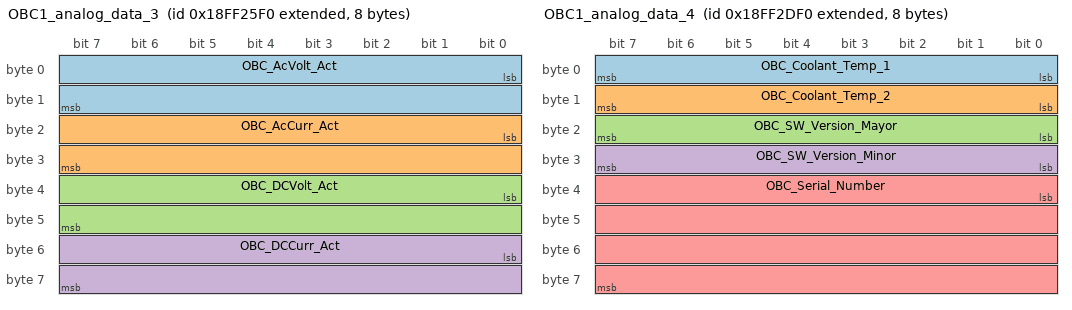
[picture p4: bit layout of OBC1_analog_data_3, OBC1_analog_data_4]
BO_ 2566858224 OBC1_analog_data_3: 8 Vector__XXX
 SG_ OBC_AcVolt_Act : 0|16@1+ (0.1,-3212.7) [-3212.7|3212.8] "V" Vector__XXX
 SG_ OBC_AcCurr_Act : 16|16@1+ (0.1,-3212.7) [-3212.7|3212.8] "A" Vector__XXX
 SG_ OBC_DCVolt_Act : 32|16@1+ (0.1,-3212.7) [-3212.7|3212.8] "V" Vector__XXX
 SG_ OBC_DCCurr_Act : 48|16@1+ (0.1,-3212.7) [-3212.7|3212.8] "A" Vector__XXX

BO_ 2566860272 OBC1_analog_data_4: 8 Vector__XXX
 SG_ OBC_Coolant_Temp_1 : 0|8@1+ (1,-40) [-40|215] "�C" Vector__XXX
 SG_ OBC_Coolant_Temp_2 : 8|8@1+ (1,-40) [-40|215] "�C" Vector__XXX
 SG_ OBC_SW_Version_Mayor : 16|8@1+ (1,0) [0|255] "" Vector__XXX
 SG_ OBC_SW_Version_Minor : 24|8@1+ (1,0) [0|255] "" Vector__XXX
 SG_ OBC_Serial_Number : 32|32@1+ (1,0) [0|999999] "" Vector__XXX

BO_ 2281766656 WakeUp_Frame: 0 Vector__XXX

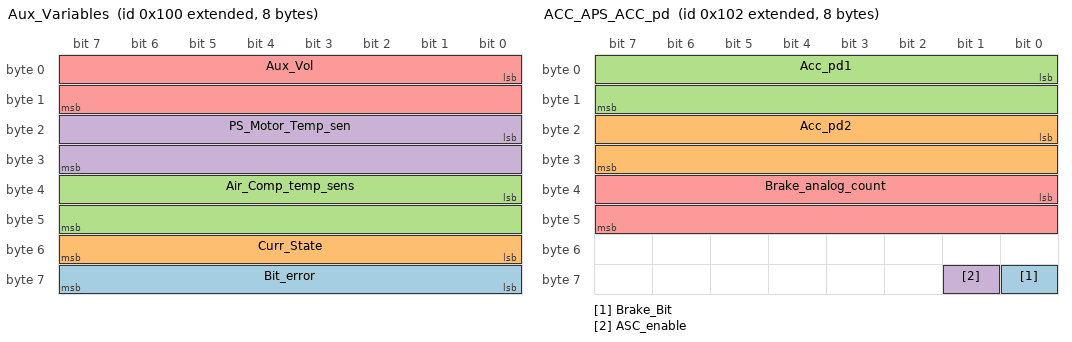
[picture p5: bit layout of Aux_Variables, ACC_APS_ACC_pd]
BO_ 2147483904 Aux_Variables: 8 Vector__XXX
 SG_ Bit_error : 56|8@1+ (1,0) [0|255] "" Vector__XXX
 SG_ Curr_State : 48|8@1+ (1,0) [0|255] "" Vector__XXX
 SG_ Air_Comp_temp_sens : 32|16@1+ (1,0) [0|65535] "" Vector__XXX
 SG_ PS_Motor_Temp_sen : 16|16@1+ (1,0) [0|65535] "" Vector__XXX
 SG_ Aux_Vol : 0|16@1+ (1,0) [0|65535] "" Vector__XXX

BO_ 2147483906 ACC_APS_ACC_pd: 8 Vector__XXX
 SG_ Brake_Bit : 56|1@1+ (1,0) [0|1] "" Vector__XXX
 SG_ Acc_pd2 : 16|16@1+ (1,0) [0|65535] "" Vector__XXX
 SG_ Acc_pd1 : 0|16@1+ (1,0) [0|65535] "" Vector__XXX
 SG_ ASC_enable : 57|1@1+ (1,0) [0|1] "" Vector__XXX
 SG_ Brake_analog_count : 32|16@1+ (1,0) [0|1] "" Vector__XXX

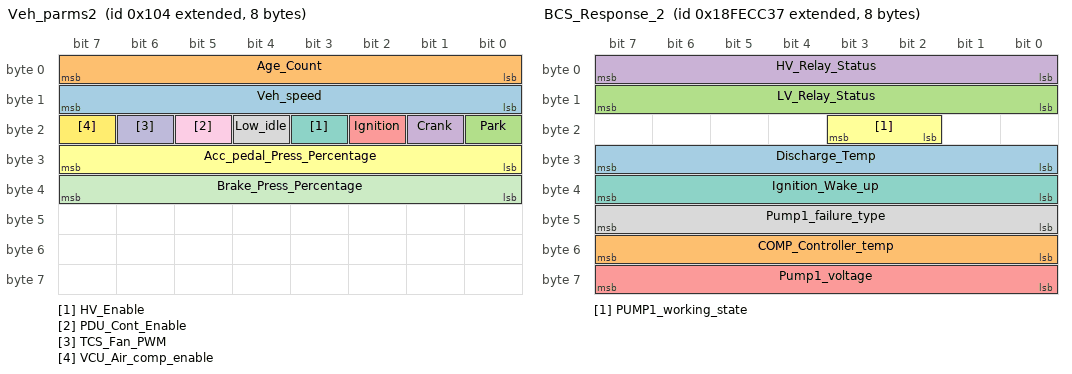
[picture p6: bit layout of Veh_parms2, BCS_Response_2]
BO_ 2147483908 Veh_parms2: 8 Vector__XXX
 SG_ Veh_speed : 8|8@1- (1,0) [-128|127] "" Vector__XXX
 SG_ Age_Count : 0|8@1+ (1,0) [0|255] "" Vector__XXX
 SG_ Park : 16|1@1+ (1,0) [0|1] "" Vector__XXX
 SG_ Crank : 17|1@1+ (1,0) [0|1] "" Vector__XXX
 SG_ Ignition : 18|1@1+ (1,0) [0|1] "" Vector__XXX
 SG_ Acc_pedal_Press_Percentage : 24|8@1+ (1,0) [0|1] "" Vector__XXX
 SG_ HV_Enable : 19|1@1+ (1,0) [0|1] "" Vector__XXX
 SG_ Low_idle : 20|1@1+ (1,0) [0|1] "" Vector__XXX
 SG_ PDU_Cont_Enable : 21|1@1+ (1,0) [0|1] "" Vector__XXX
 SG_ TCS_Fan_PWM : 22|1@1+ (1,0) [0|1] "" Vector__XXX
 SG_ Brake_Press_Percentage : 32|8@1+ (1,0) [0|1] "" Vector__XXX
 SG_ VCU_Air_comp_enable : 23|1@1+ (1,0) [0|1] "" Vector__XXX

BO_ 2566835255 BCS_Response_2: 8 Vector__XXX
 SG_ Discharge_Temp : 24|8@1+ (1,0) [0|255] "" Vector__XXX
 SG_ COMP_Controller_temp : 48|8@1+ (1,-40) [-40|215] "C" Vector__XXX
 SG_ LV_Relay_Status : 8|8@1+ (1,0) [0|1] "" Vector__XXX
 SG_ HV_Relay_Status : 0|8@1+ (1,0) [0|1] "" Vector__XXX
 SG_ Pump1_voltage : 56|8@1+ (0.2,0) [0|51] "V" Vector__XXX
 SG_ PUMP1_working_state : 18|2@1+ (1,0) [0|3] "" Vector__XXX
 SG_ Ignition_Wake_up : 32|8@1+ (1,0) [0|255] "" Vector__XXX
 SG_ Pump1_failure_type : 40|8@1+ (1,0) [0|255] "" Vector__XXX

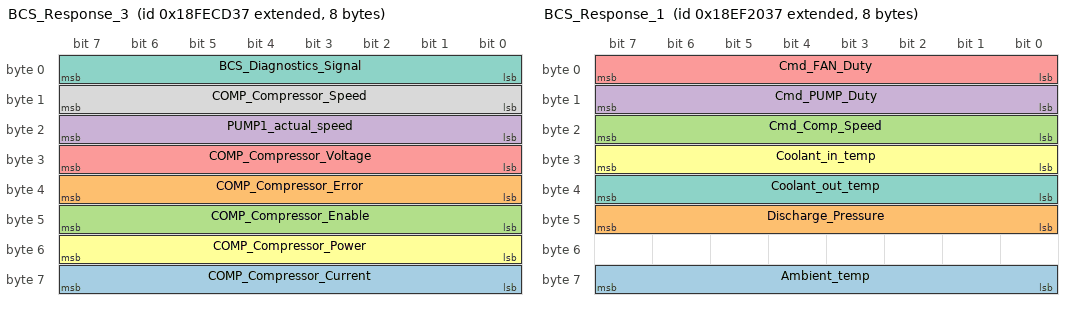
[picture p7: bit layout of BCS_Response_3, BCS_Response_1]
BO_ 2566835511 BCS_Response_3: 8 Vector__XXX
 SG_ COMP_Compressor_Current : 56|8@1+ (0.1,0) [0|25.5] "A" Vector__XXX
 SG_ COMP_Compressor_Error : 32|8@1+ (1,0) [0|255] "" Vector__XXX
 SG_ COMP_Compressor_Enable : 40|8@1+ (1,0) [0|255] "" Vector__XXX
 SG_ PUMP1_actual_speed : 16|8@1+ (50,0) [0|12750] "RPM" Vector__XXX
 SG_ COMP_Compressor_Voltage : 24|8@1+ (4,0) [0|1020] "V" Vector__XXX
 SG_ COMP_Compressor_Power : 48|8@1+ (0.1,0) [0|25.5] "KW" Vector__XXX
 SG_ BCS_Diagnostics_Signal : 0|8@1+ (1,0) [0|255] "" Vector__XXX
 SG_ COMP_Compressor_Speed : 8|8@1+ (50,0) [0|12750] "RPM" Vector__XXX

BO_ 2565808167 CommandBCS: 8 Vector__XXX
 SG_ Battery_Temperature : 8|8@1+ (0.5,-40) [-40|85] "C" Vector__XXX

BO_ 2565808183 BCS_Response_1: 8 Vector__XXX
 SG_ Ambient_temp : 56|8@1- (1,0) [-128|127] "C" Vector__XXX
 SG_ Discharge_Pressure : 40|8@1+ (1,0) [0|255] "Bar" Vector__XXX
 SG_ Cmd_Comp_Speed : 16|8@1+ (50,0) [0|5500] "RPM" Vector__XXX
 SG_ Cmd_PUMP_Duty : 8|8@1+ (1,0) [0|255] "%" Vector__XXX
 SG_ Cmd_FAN_Duty : 0|8@1+ (1,0) [0|255] "%" Vector__XXX
 SG_ Coolant_in_temp : 24|8@1- (1,0) [-128|127] "C" Vector__XXX
 SG_ Coolant_out_temp : 32|8@1- (1,0) [-128|127] "C" Vector__XXX

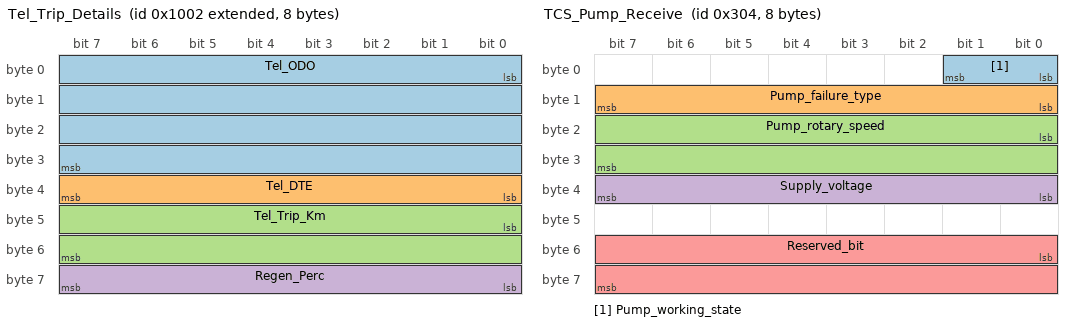
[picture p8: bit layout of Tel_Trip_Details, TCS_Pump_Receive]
BO_ 2147487746 Tel_Trip_Details: 8 Vector__XXX
 SG_ Tel_ODO : 0|32@1+ (1,0) [0|200000] "" Vector__XXX
 SG_ Tel_DTE : 32|8@1+ (1,0) [0|250] "" Vector__XXX
 SG_ Tel_Trip_Km : 40|16@1+ (1,0) [0|10000] "" Vector__XXX
 SG_ Regen_Perc : 56|8@1+ (1,0) [0|100] "%" Vector__XXX

BO_ 773 TCS_Pump_Transmit: 8 Vector__XXX
 SG_ Pump_control_instruction : 0|8@1+ (1,0) [0|255] "" Vector__XXX

BO_ 772 TCS_Pump_Receive: 8 Vector__XXX
 SG_ Pump_working_state : 0|2@1+ (1,0) [0|3] "" Vector__XXX
 SG_ Pump_failure_type : 8|8@1+ (1,0) [0|255] "" Vector__XXX
 SG_ Pump_rotary_speed : 16|16@1+ (1,0) [0|65535] "" Vector__XXX
 SG_ Supply_voltage : 32|8@1+ (0.2,0) [0|51] "" Vector__XXX
 SG_ Reserved_bit : 48|16@1+ (1,0) [0|0] "" Vector__XXX

BO_ 2147548160 DCDC_FAULTS: 8 Vector__XXX
 SG_ INPUT_UV : 0|1@1+ (1,0) [0|1] "" Vector__XXX
 SG_ INPUT_OV : 1|1@1+ (1,0) [0|1] "" Vector__XXX
 SG_ LVPS_UV : 2|1@1+ (1,0) [0|1] "" Vector__XXX
 SG_ LVPS_OV : 3|1@1+ (1,0) [0|1] "" Vector__XXX
 SG_ OP_OV : 5|1@1+ (1,0) [0|1] "" Vector__XXX
 SG_ OP_UV : 4|1@1+ (1,0) [0|1] "" Vector__XXX
 SG_ EXTERNAL_ENB_FAULT : 6|1@1+ (1,0) [0|1] "" Vector__XXX
 SG_ PSFB_REF_FAULT : 7|1@1+ (1,0) [0|1] "" Vector__XXX
 SG_ SEC_UT : 12|1@1+ (1,0) [0|1] "" Vector__XXX
 SG_ SHIM_UT : 8|1@1+ (1,0) [0|1] "" Vector__XXX
 SG_ SHIM_OT : 9|1@1+ (1,0) [0|1] "" Vector__XXX
 SG_ SEC_OT : 13|1@1+ (1,0) [0|1] "" Vector__XXX
 SG_ TRANS_OT : 11|1@1+ (1,0) [0|1] "" Vector__XXX
 SG_ TRANS_UT : 10|1@1+ (1,0) [0|1] "" Vector__XXX
 SG_ PRI_UT : 14|1@1+ (1,0) [0|1] "" Vector__XXX
 SG_ PRI_OT : 15|1@1+ (1,0) [0|1] "" Vector__XXX
 SG_ HVIL_FAULT : 16|1@1+ (1,0) [0|1] "" Vector__XXX
 SG_ Output_Over_Current_Fault : 17|1@1+ (1,0) [0|1] "" Vector__XXX
 SG_ Input_Over_Current_Fault : 18|1@1+ (1,0) [0|1] "" Vector__XXX
 SG_ Hys_Fault : 19|1@1+ (1,0) [0|1] "" Vector__XXX
 SG_ Output_CUR_Misc_Fault : 20|1@1+ (1,0) [0|1] "" Vector__XXX

BO_ 2147548161 DCDC_FLAGS: 8 Vector__XXX
 SG_ DCDC_FLAG : 0|1@1+ (1,0) [0|1] "" Vector__XXX
 SG_ EXT_EN_FLAG : 1|1@1+ (1,0) [0|1] "" Vector__XXX

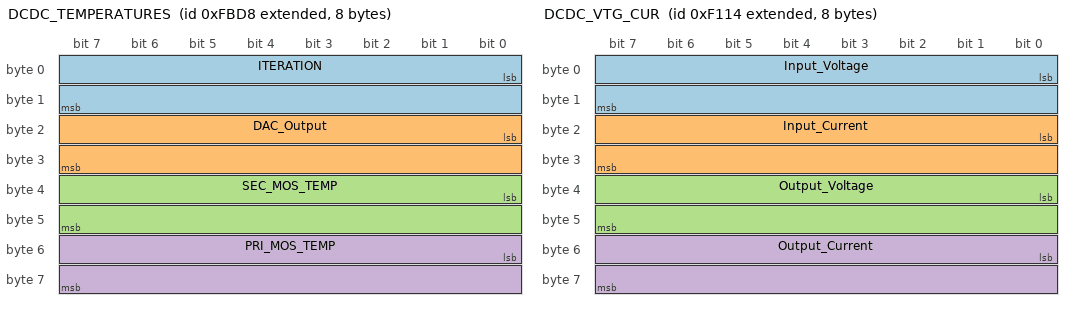
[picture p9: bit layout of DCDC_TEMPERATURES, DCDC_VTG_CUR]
BO_ 2147548120 DCDC_TEMPERATURES: 8 Vector__XXX
 SG_ ITERATION : 0|16@1+ (1,0) [0|65535] "" Vector__XXX
 SG_ DAC_Output : 16|16@1+ (0.1,0) [0|655.35] "" Vector__XXX
 SG_ SEC_MOS_TEMP : 32|16@1+ (1,-60) [-40|195] "Deg C" Vector__XXX
 SG_ PRI_MOS_TEMP : 48|16@1+ (1,-60) [-60|65475] "Deg C" Vector__XXX

BO_ 2147545364 DCDC_VTG_CUR: 8 Vector__XXX
 SG_ Input_Voltage : 0|16@1+ (1,0) [0|6553.5] "V" Vector__XXX
 SG_ Input_Current : 16|16@1+ (0.1,0) [0|6553.5] "A" Vector__XXX
 SG_ Output_Voltage : 32|16@1+ (0.1,0) [0|6553.5] "V" Vector__XXX
 SG_ Output_Current : 48|16@1+ (1,0) [0|819.1] "A" Vector__XXX

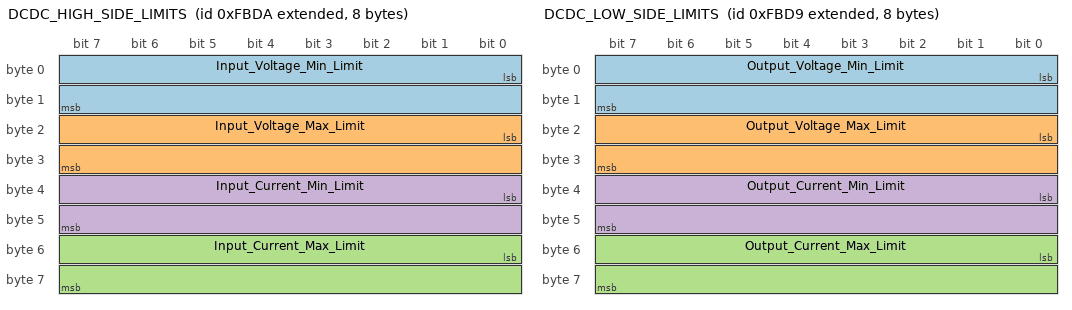
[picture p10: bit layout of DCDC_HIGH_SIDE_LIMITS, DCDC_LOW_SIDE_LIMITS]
BO_ 2147548122 DCDC_HIGH_SIDE_LIMITS: 8 Vector__XXX
 SG_ Input_Voltage_Min_Limit : 0|16@1+ (1,0) [0|65535] "V" Vector__XXX
 SG_ Input_Voltage_Max_Limit : 16|16@1+ (1,0) [0|65535] "V" Vector__XXX
 SG_ Input_Current_Max_Limit : 48|16@1+ (1,0) [0|65535] "A" Vector__XXX
 SG_ Input_Current_Min_Limit : 32|16@1+ (1,0) [0|65535] "A" Vector__XXX

BO_ 2147548121 DCDC_LOW_SIDE_LIMITS: 8 Vector__XXX
 SG_ Output_Voltage_Min_Limit : 0|16@1+ (1,0) [0|65535] "V" Vector__XXX
 SG_ Output_Voltage_Max_Limit : 16|16@1+ (1,0) [0|65535] "V" Vector__XXX
 SG_ Output_Current_Max_Limit : 48|16@1+ (1,0) [0|65535] "A" Vector__XXX
 SG_ Output_Current_Min_Limit : 32|16@1+ (1,0) [0|65535] "A" Vector__XXX

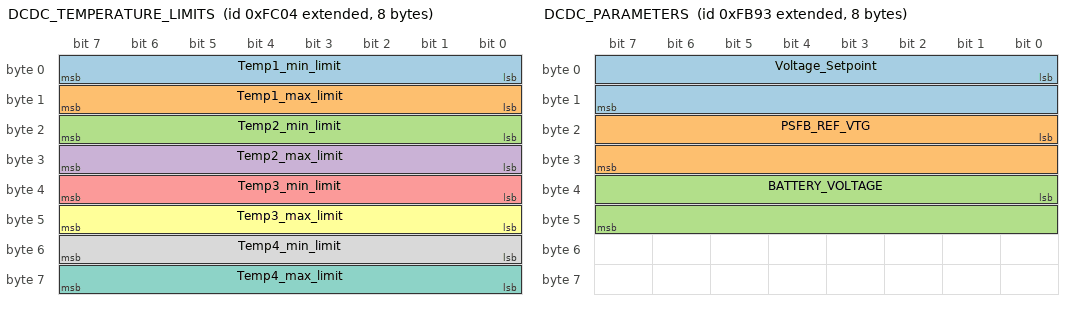
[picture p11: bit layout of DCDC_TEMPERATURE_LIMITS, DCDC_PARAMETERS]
BO_ 2147548164 DCDC_TEMPERATURE_LIMITS: 8 Vector__XXX
 SG_ Temp1_min_limit : 0|8@1+ (1,0) [0|1] "Degree C" Vector__XXX
 SG_ Temp1_max_limit : 8|8@1+ (1,0) [0|1] "Degree C" Vector__XXX
 SG_ Temp2_min_limit : 16|8@1+ (1,0) [0|1] "Degree C" Vector__XXX
 SG_ Temp2_max_limit : 24|8@1+ (1,0) [0|1] "Degree C" Vector__XXX
 SG_ Temp3_min_limit : 32|8@1+ (1,0) [0|1] "Degree C" Vector__XXX
 SG_ Temp3_max_limit : 40|8@1+ (1,0) [0|1] "Degree C" Vector__XXX
 SG_ Temp4_max_limit : 56|8@1+ (1,0) [0|1] "Degree C" Vector__XXX
 SG_ Temp4_min_limit : 48|8@1+ (1,0) [0|1] "Degree C" Vector__XXX

BO_ 2147548051 DCDC_PARAMETERS: 8 Vector__XXX
 SG_ Voltage_Setpoint : 0|16@1+ (0.01,0) [0|655.35] "V" Vector__XXX
 SG_ PSFB_REF_VTG : 16|16@1+ (0.01,0) [0|655.35] "V" Vector__XXX
 SG_ BATTERY_VOLTAGE : 32|16@1+ (0.1,0) [0|6553.5] "V" Vector__XXX

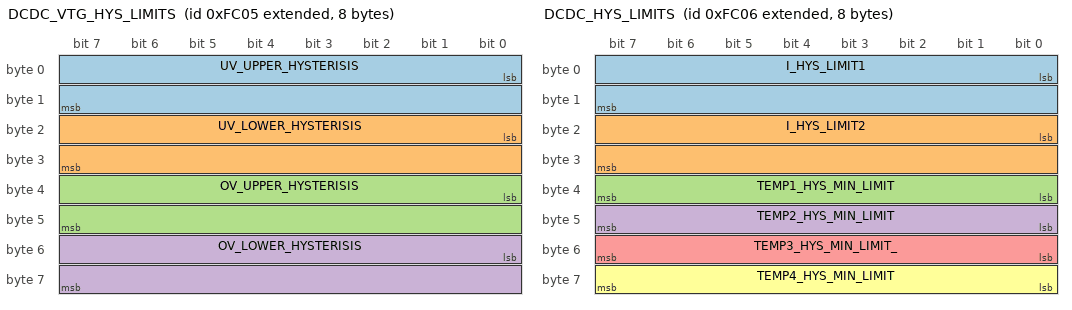
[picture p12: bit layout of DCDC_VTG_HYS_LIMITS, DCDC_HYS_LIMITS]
BO_ 2147548165 DCDC_VTG_HYS_LIMITS: 8 Vector__XXX
 SG_ UV_UPPER_HYSTERISIS : 0|16@1+ (1,0) [0|1] "V" Vector__XXX
 SG_ UV_LOWER_HYSTERISIS : 16|16@1+ (1,0) [0|1] "V" Vector__XXX
 SG_ OV_UPPER_HYSTERISIS : 32|16@1+ (1,0) [0|1] "V" Vector__XXX
 SG_ OV_LOWER_HYSTERISIS : 48|16@1+ (1,0) [0|1] "V" Vector__XXX

BO_ 2147548166 DCDC_HYS_LIMITS: 8 Vector__XXX
 SG_ I_HYS_LIMIT1 : 0|16@1+ (1,0) [0|1] "A" Vector__XXX
 SG_ I_HYS_LIMIT2 : 16|16@1+ (1,0) [0|1] "A" Vector__XXX
 SG_ TEMP1_HYS_MIN_LIMIT : 32|8@1+ (1,0) [0|1] "Deg Celcius" Vector__XXX
 SG_ TEMP2_HYS_MIN_LIMIT : 40|8@1+ (1,0) [0|1] "Deg Celcius" Vector__XXX
 SG_ TEMP3_HYS_MIN_LIMIT_ : 48|8@1+ (1,0) [0|1] "Deg Celcius" Vector__XXX
 SG_ TEMP4_HYS_MIN_LIMIT : 56|8@1+ (1,0) [0|1] "Deg Celcius" Vector__XXX

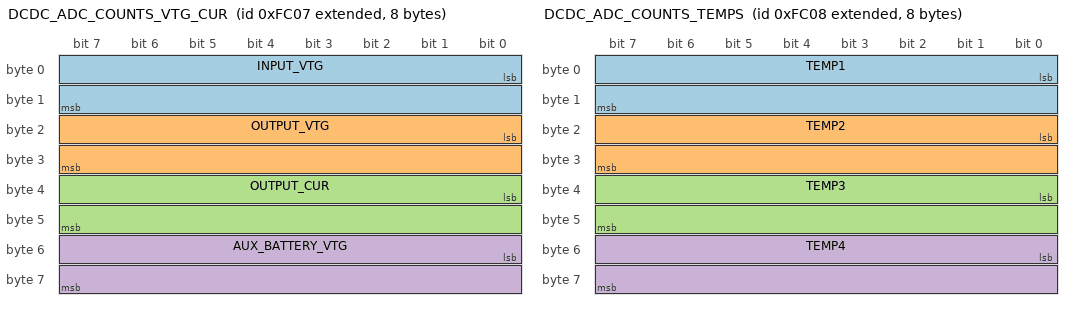
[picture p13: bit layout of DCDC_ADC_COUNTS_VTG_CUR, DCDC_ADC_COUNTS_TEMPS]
BO_ 2147548167 DCDC_ADC_COUNTS_VTG_CUR: 8 Vector__XXX
 SG_ INPUT_VTG : 0|16@1+ (1,0) [0|1] "" Vector__XXX
 SG_ OUTPUT_VTG : 16|16@1+ (1,0) [0|1] "" Vector__XXX
 SG_ OUTPUT_CUR : 32|16@1+ (1,0) [0|1] "" Vector__XXX
 SG_ AUX_BATTERY_VTG : 48|16@1+ (1,0) [0|1] "" Vector__XXX

BO_ 2147548168 DCDC_ADC_COUNTS_TEMPS: 8 Vector__XXX
 SG_ TEMP1 : 0|16@1+ (1,0) [0|1] "" Vector__XXX
 SG_ TEMP2 : 16|16@1+ (1,0) [0|1] "" Vector__XXX
 SG_ TEMP3 : 32|16@1+ (1,0) [0|1] "" Vector__XXX
 SG_ TEMP4 : 48|16@1+ (1,0) [0|1] "" Vector__XXX

BO_ 2147547648 DCDC_OV_CURR_FAULT: 8 Vector__XXX
 SG_ Occurence_Count : 0|8@1+ (1,0) [0|1] "" Vector__XXX

BO_ 273 OPERATING_STATUS: 8 Vector__XXX
 SG_ MODE : 0|8@1+ (1,0) [0|190] "" Vector__XXX
 SG_ BAUD_RATE : 8|16@1+ (1,0) [0|65535] "" Vector__XXX

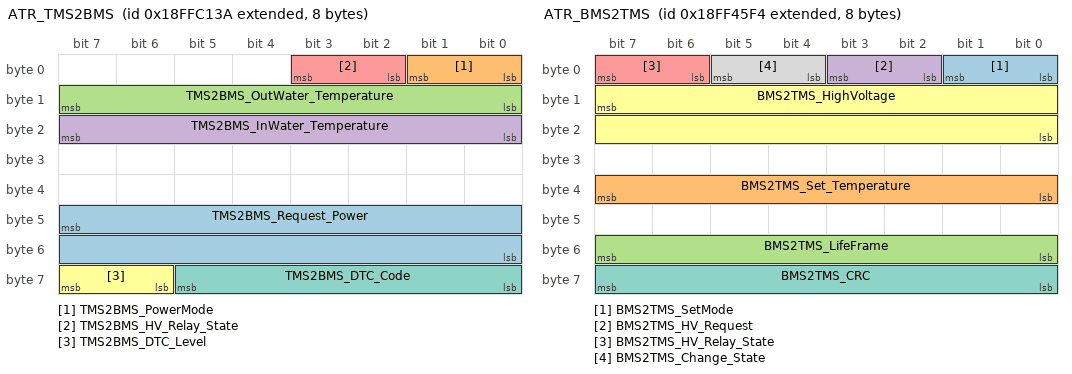
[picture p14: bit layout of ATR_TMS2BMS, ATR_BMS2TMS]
BO_ 2566897978 ATR_TMS2BMS: 8 Vector__XXX
 SG_ TMS2BMS_Request_Power : 47|16@0+ (0.1,0) [0|100] "Kw" Vector__XXX
 SG_ TMS2BMS_PowerMode : 1|2@0+ (1,0) [0|3] "" Vector__XXX
 SG_ TMS2BMS_OutWater_Temperature : 15|8@0+ (1,-40) [-40|210] "��" Vector__XXX
 SG_ TMS2BMS_InWater_Temperature : 23|8@0+ (1,-40) [-40|210] "��" Vector__XXX
 SG_ TMS2BMS_HV_Relay_State : 3|2@0+ (1,0) [0|3] "" Vector__XXX
 SG_ TMS2BMS_DTC_Level : 63|2@0+ (1,0) [0|3] "" Vector__XXX
 SG_ TMS2BMS_DTC_Code : 61|6@0+ (1,0) [0|51] "" Vector__XXX

BO_ 2566866420 ATR_BMS2TMS: 8 Vector__XXX
 SG_ BMS2TMS_SetMode : 1|2@0+ (1,0) [0|3] "" Vector__XXX
 SG_ BMS2TMS_Set_Temperature : 39|8@0+ (1,-40) [-40|210] "��" Vector__XXX
 SG_ BMS2TMS_LifeFrame : 55|8@0+ (1,0) [0|255] "" Vector__XXX
 SG_ BMS2TMS_HV_Request : 3|2@0+ (1,0) [0|3] "" Vector__XXX
 SG_ BMS2TMS_HV_Relay_State : 7|2@0+ (1,0) [0|3] "" Vector__XXX
 SG_ BMS2TMS_HighVoltage : 15|16@0+ (1,0) [0|1000] "V" Vector__XXX
 SG_ BMS2TMS_CRC : 63|8@0+ (1,0) [0|255] "" Vector__XXX
 SG_ BMS2TMS_Change_State : 5|2@0+ (1,0) [0|3] "" Vector__XXX

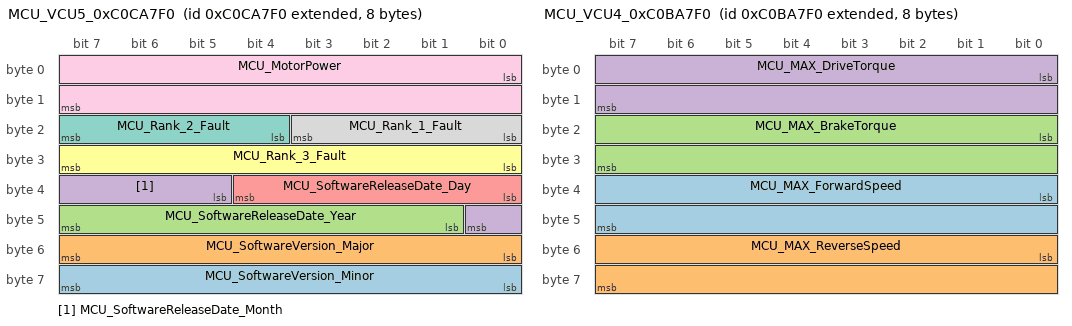
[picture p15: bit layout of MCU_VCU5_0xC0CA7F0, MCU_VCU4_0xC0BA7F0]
BO_ 2349639664 MCU_VCU5_0xC0CA7F0: 8 Vector__XXX
 SG_ MCU_SoftwareVersion_Minor : 56|8@1+ (1,0) [0|255] "" Vector__XXX
 SG_ MCU_SoftwareVersion_Major : 48|8@1+ (1,0) [0|255] "" Vector__XXX
 SG_ MCU_SoftwareReleaseDate_Year : 41|7@1+ (1,0) [0|127] "" Vector__XXX
 SG_ MCU_SoftwareReleaseDate_Month : 37|4@1+ (1,0) [0|15] "" Vector__XXX
 SG_ MCU_SoftwareReleaseDate_Day : 32|5@1+ (1,0) [0|31] "" Vector__XXX
 SG_ MCU_Rank_3_Fault : 24|8@1+ (1,0) [0|255] "" Vector__XXX
 SG_ MCU_Rank_2_Fault : 20|4@1+ (1,0) [0|15] "" Vector__XXX
 SG_ MCU_Rank_1_Fault : 16|4@1+ (1,0) [0|15] "" Vector__XXX
 SG_ MCU_MotorPower : 0|16@1+ (0.1,-3200) [-3200|3353.5] "kW" Vector__XXX

BO_ 2349574128 MCU_VCU4_0xC0BA7F0: 8 Vector__XXX
 SG_ MCU_MAX_ForwardSpeed : 32|16@1+ (1,0) [0|65535] "rpm" Vector__XXX
 SG_ MCU_MAX_ReverseSpeed : 48|16@1+ (1,0) [0|65535] "rpm" Vector__XXX
 SG_ MCU_MAX_BrakeTorque : 16|16@1+ (0.1,0) [0|6553.5] "Nm" Vector__XXX
 SG_ MCU_MAX_DriveTorque : 0|16@1+ (0.1,0) [0|6553.5] "Nm" Vector__XXX

BO_ 2349508592 MCU_VCU3_0xC0AA7F0: 8 Vector__XXX
 SG_ MCU_N_FaultNUM : 56|8@1+ (1,0) [0|255] "" Vector__XXX
 SG_ MCU_N_FaultGrade : 52|4@1+ (1,0) [0|15] "" Vector__XXX
 SG_ MCU_F_SPEED_OV_WARNING : 49|1@1+ (1,0) [0|1] "" Vector__XXX
 SG_ MCU_F_ACC_UV_WARNING : 48|1@1+ (1,0) [0|1] "" Vector__XXX
 SG_ MCU_F_MOTOR_TEMP_SENSOR : 46|1@1+ (1,0) [0|1] "" Vector__XXX
 SG_ MCU_F_IGBT_TEMP_SENSOR : 45|1@1+ (1,0) [0|1] "" Vector__XXX
 SG_ MCU_F_H_W_OC : 44|1@1+ (1,0) [0|1] "" Vector__XXX
 SG_ MCU_F_H_V_OC : 43|1@1+ (1,0) [0|1] "" Vector__XXX
 SG_ MCU_F_H_U_OC : 42|1@1+ (1,0) [0|1] "" Vector__XXX
 SG_ MCU_F_IGBT : 0|1@1+ (1,0) [0|1] "" Vector__XXX
 SG_ MCU_F_H_OC : 1|1@1+ (1,0) [0|1] "" Vector__XXX
 SG_ MCU_F_H_OV : 3|1@1+ (1,0) [0|1] "" Vector__XXX
 SG_ MCU_F_ENCORDE : 5|1@1+ (1,0) [0|1] "" Vector__XXX
 SG_ MCU_F_LACK_PHASE : 6|1@1+ (1,0) [0|1] "" Vector__XXX
 SG_ MCU_F_CURRENT_DETECT : 7|1@1+ (1,0) [0|1] "" Vector__XXX
 SG_ MCU_F_GUN_SELF : 10|1@1+ (1,0) [0|1] "" Vector__XXX
 SG_ MCU_F_ACC_UV : 11|1@1+ (1,0) [0|1] "" Vector__XXX
 SG_ MCU_F_BUS_OV_H : 16|1@1+ (1,0) [0|1] "" Vector__XXX
 SG_ MCU_F_S_OC : 12|1@1+ (1,0) [0|1] "" Vector__XXX
 SG_ MCU_F_BUS_UV_L : 13|1@1+ (1,0) [0|1] "" Vector__XXX
 SG_ MCU_F_BUS_UV_H : 14|1@1+ (1,0) [0|1] "" Vector__XXX
 SG_ MCU_F_BUS_OV_L : 15|1@1+ (1,0) [0|1] "" Vector__XXX
 SG_ MCU_F_CONTROL_OL_L : 17|1@1+ (1,0) [0|1] "" Vector__XXX
 SG_ MCU_F_CONTROL_OL_H : 18|1@1+ (1,0) [0|1] "" Vector__XXX
 SG_ MCU_F_SPEED_OV : 21|1@1+ (1,0) [0|1] "" Vector__XXX
 SG_ MCU_F_CAN_OFFLINE : 22|1@1+ (1,0) [0|1] "" Vector__XXX
 SG_ MCU_F_IGBT_OT_L : 23|1@1+ (1,0) [0|1] "" Vector__XXX
 SG_ MCU_F_IGBT_OT_H : 24|1@1+ (1,0) [0|1] "" Vector__XXX
 SG_ MCU_F_MOTOR_OT_L : 29|1@1+ (1,0) [0|1] "" Vector__XXX
 SG_ MCU_F_MOTOR_OT_H : 30|1@1+ (1,0) [0|1] "" Vector__XXX
 SG_ MCU_F_U_UP_IGBT : 35|1@1+ (1,0) [0|1] "" Vector__XXX
 SG_ MCU_F_U_DOWN_IGBT : 36|1@1+ (1,0) [0|1] "" Vector__XXX
 SG_ MCU_F_V_UP_IGBT : 37|1@1+ (1,0) [0|1] "" Vector__XXX
 SG_ MCU_F_V_DOWN_IGBT : 38|1@1+ (1,0) [0|1] "" Vector__XXX
 SG_ MCU_F_W_UP_IGBT : 39|1@1+ (1,0) [0|1] "" Vector__XXX
 SG_ MCU_F_W_DOWN_IGBT : 40|1@1+ (1,0) [0|1] "" Vector__XXX

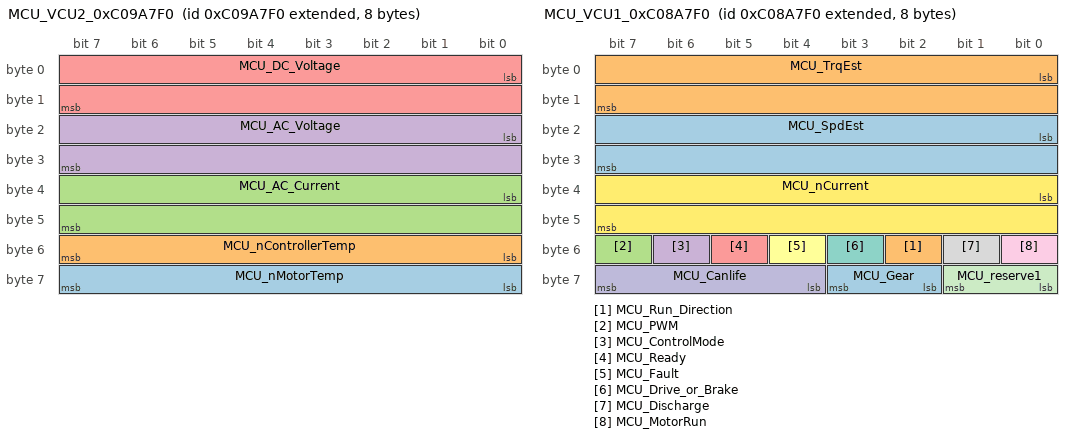
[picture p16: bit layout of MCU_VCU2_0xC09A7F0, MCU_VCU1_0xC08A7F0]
BO_ 2349443056 MCU_VCU2_0xC09A7F0: 8 Vector__XXX
 SG_ MCU_nMotorTemp : 56|8@1+ (1,-40) [-40|215] "��" Vector__XXX
 SG_ MCU_nControllerTemp : 48|8@1+ (1,-40) [-40|215] "��" Vector__XXX
 SG_ MCU_AC_Current : 32|16@1+ (0.1,0) [0|6553.5] "A" Vector__XXX
 SG_ MCU_AC_Voltage : 16|16@1+ (0.1,0) [0|6553.5] "V" Vector__XXX
 SG_ MCU_DC_Voltage : 0|16@1+ (0.1,0) [0|6553.5] "V" Vector__XXX

BO_ 2349377520 MCU_VCU1_0xC08A7F0: 8 Vector__XXX
 SG_ MCU_Gear : 58|2@1+ (1,0) [0|3] "" Vector__XXX
 SG_ MCU_Run_Direction : 50|1@1+ (1,0) [0|1] "" Vector__XXX
 SG_ MCU_PWM : 55|1@1+ (1,0) [0|1] "" Vector__XXX
 SG_ MCU_ControlMode : 54|1@1+ (1,0) [0|1] "" Vector__XXX
 SG_ MCU_Ready : 53|1@1+ (1,0) [0|1] "" Vector__XXX
 SG_ MCU_Fault : 52|1@1+ (1,0) [0|1] "" Vector__XXX
 SG_ MCU_Drive_or_Brake : 51|1@1+ (1,0) [0|1] "" Vector__XXX
 SG_ MCU_Discharge : 49|1@1+ (1,0) [0|1] "" Vector__XXX
 SG_ MCU_MotorRun : 48|1@1+ (1,0) [0|1] "" Vector__XXX
 SG_ MCU_Canlife : 60|4@1+ (1,0) [0|15] "" Vector__XXX
 SG_ MCU_reserve1 : 56|2@1+ (1,0) [0|3] "" Vector__XXX
 SG_ MCU_nCurrent : 32|16@1+ (0.1,-3200) [-3200|3353.5] "A" Vector__XXX
 SG_ MCU_SpdEst : 16|16@1+ (1,-32000) [-32000|33535] "rpm" Vector__XXX
 SG_ MCU_TrqEst : 0|16@1+ (0.1,-3200) [-3200|3353.5] "Nm" Vector__XXX

CM_ BO_ 3221225472 "This is a message for not used signals, created by Vector CANdb++ DBC OLE DB Provider.";
CM_ SG_ 3221225472 OBC_charge_enable "Charging requested";
CM_ SG_ 3221225472 Plug_lock_request "Charge plug locking is requested";
CM_ SG_ 3221225472 Vehicle_Insulation_Monitoring "Vehicle insulation in progress";
CM_ SG_ 3221225472 EV_DisconnectingDevice "DC contactors control";
CM_ SG_ 3221225472 Inlet_LED_Green "Vehicle LED (green) control";
CM_ SG_ 3221225472 Inlet_LED_Blue "Vehicle LED (blue) control";
CM_ SG_ 3221225472 Inlet_LED_Red "Vehicle LED (red) control";
CM_ SG_ 3221225472 EV_DisconnectingDevicePlus "Optional: DC contactors plus control";
CM_ SG_ 3221225472 EV_DisconnectingDeviceMinus "Optional: DC contactors minus control";
CM_ SG_ 3221225472 EVEnergyRequest "Amount of energy the EV requests from the EVSE";
CM_ SG_ 3221225472 EVEnergyCapacity "Maximum energy capacity supported by the EV";
CM_ SG_ 3221225472 EVSECompatible "This signal checks the  EV and EVSE compatibility.Ex: EVSE can charge only 400V But EV needs 800V then compatibiltiy is false      Also in compatable Standards";
CM_ SG_ 3221225472 VoltageMatch "change volate and pre charge is same (+ or - 20V)- TrueelseFalseSNA- The functionality is not available";
CM_ SG_ 3221225472 ControlPilotState "Control Pilot State A, B, C etc.";
CM_ SG_ 3221225472 ControlPilotDutyCycle "Duty Cycle of the Control Pilot.";
CM_ SG_ 3221225472 TCPStatus "TCP status PLC connection";
CM_ SG_ 3221225472 ActualChargeProtocol "The actual negotiated protocol of the ongoing charge. Default values is Not defined (0x03)";
CM_ SG_ 3221225472 Charge_Plug_Locked "Charge plug is locked";
CM_ SG_ 3221225472 ProximityPinState "State of the J1772 proximity detection. 0x0 Unknown 0x1 Not Connected 0x2 Connected 0x3 Connected but not latchedIt is also checks the proximity resistance and maps with the current (see value description,)";
CM_ SG_ 3221225472 StateMachineState "Actual progress of the charging session";
CM_ SG_ 3221225472 EVSECurrentRegulationTolerance "Absolute magnitude of the regulation tolerance of the EVSE.";
CM_ SG_ 3221225472 EVSEPeakCurrentRipple "Peak-to-peak magnitude of the current ripple of the EVSE.";
CM_ SG_ 3221225472 EVSEMinVoltage "Minimum voltage the EVSE can deliver with the expected accuracy.";
CM_ SG_ 3221225472 EVSEMinCurrent "Minimum current the EVSE can deliver with the expected accuracy.";
CM_ SG_ 3221225472 EVSEEnergyToBeDelivered "Amount of energy to be delivered by the EVSE.";
CM_ SG_ 3221225472 EVSEMaxPower "Maximum power the EVSE can deliver.";
CM_ SG_ 3221225472 EVSEMaxVoltage "Maximum voltage the EVSE can deliver.";
CM_ SG_ 3221225472 EVSEMaxCurrent "Maximum current the EVSE can deliver.";
CM_ SG_ 3221225472 EVWeldingDetectionEnable "Determines if the EV wants to do Welding Detection at the end of a charging procedure.";
CM_ SG_ 3221225472 EVReady "Indication that the vehicle is ready for the further process generally.";
CM_ SG_ 3221225472 ChargeStopIndication "Indication if the charge shall be stopped completely, paused or continue as supposed.DefaultValue shall be: NoStop";
CM_ SG_ 3221225472 ChargeProgressIndication "Indication that the vehicle is ready to accept a charge or wants to stop it";
CM_ SG_ 3221225472 ChargeProtocolPriority "Charge protocol priority";
CM_ SG_ 3221225472 EVRESSConditioning "Vehicle RESS Conditioning, The vehicle is using energy from the DC charger to condition the RESS to a target temperature.";
CM_ SG_ 3221225472 EVTimeToFullSoC "Estimated or calculated time until full charge is complete";
CM_ SG_ 3221225472 EVTimeToBulkSoC "Estimated or calculated time until bulk charge is complete";
CM_ SG_ 3221225472 EVErrorCode "Vehice Error Codes:";
CM_ SG_ 3221225472 EVCabinConditioning "Vehicle Cabin Conditioning, When True the EV is using energy from the DC supply to heat or cool the passenger compartment.";
CM_ SG_ 3221225472 EVBulkChargingComplete "This will NOT stop Charging. Its only for Display at the Charging Station";
CM_ SG_ 3221225472 EVChargingComplete "This will NOT stop Charging. Only for Display at Charging Station";
CM_ SG_ 3221225472 EVSoC "The Actual SoC of the EV. Will be displayed at the Charging Station. Nothing else.";
CM_ SG_ 3221225472 EVPreChargeVoltage "Used for PreCharge - should be the same as the actual Battery voltage";
CM_ SG_ 3221225472 EVTargetVoltage "Target Voltage during Charging. Set this to EVMaxVoltage, except you want something very special....";
CM_ SG_ 3221225472 EVTargetCurrent "The Current you want to receive from the Charging Station.";
CM_ SG_ 3221225472 EVBulkSoC "at what SoC will be the Bulk Charge finished? Set this to 80% or calculate it, depending on Temperature for Example";
CM_ SG_ 3221225472 EVFullSoC "When will be DC Charging finished. set this to 100% or calculate it depending on tempearute";
CM_ SG_ 3221225472 EVMaxVoltage "Maximum voltage supported by the EV.";
CM_ SG_ 3221225472 EVMaxPower "Maximum power supported by the EV.";
CM_ SG_ 3221225472 EVMaxCurrent "Maximum current supported by the EV.";
CM_ SG_ 3221225472 EVSEStatusCode "Actual status of the EVSE";
CM_ SG_ 3221225472 EVSEPowerLimitAchieved "If set to TRUE, the EVSE has reached its power limit";
CM_ SG_ 3221225472 EVSEVoltageLimitAchieved "If set to TRUE, the EVSE has reached its voltage limit";
CM_ SG_ 3221225472 EVSECurrentLimitAchieved "If set to TRUE, the EVSE has reached its current limit";
CM_ SG_ 3221225472 EVSEIsolationStatus "EVSE's isolation monitoring status";
CM_ SG_ 3221225472 EVSEPresentCurrent "Present output current of the EVSE. SNA = 65535";
CM_ SG_ 3221225472 EVSEPresentVoltage "Present output voltage of the EVSE. SNA = 65535";
CM_ SG_ 3221225472 EVPreChargeVoltage "Used for PreCharge - should be the same as the actual Battery voltage";
CM_ SG_ 3221225472 EVTargetVoltage "Target Voltage during Charging. Set this to EVMaxVoltage, except you want something very special....";
CM_ SG_ 3221225472 EVTargetCurrent "The Current you want to receive from the Charging Station.";
CM_ SG_ 3221225472 Reserved "Reserved Bit set as 11";
CM_ SG_ 3221225472 Tire_Press_Threshold_Detection "Tire Pressure Threshold Detection000 Extreme over pressure001 Over pressure010 No warning pressure (Ok Pressure)011 Under pressure100 Extreme under pressure110 Error indicator111 Not available (Not Supported)";
CM_ SG_ 3221225472 Tire_Temp_Threshold_Detection "Tire Temperature Threshold Detection000 Extreme over temperature 001 Over temperature010 No warning temperature (Ok Temperature)110 Error indicator111 Not available (Not supported)";
CM_ SG_ 3221225472 Sensor_Battery_Level_Status "Indicates the battery level status of the sensor.00 Ok ( No Fault)01 Low battery detected10 Error11 Not Supported";
CM_ SG_ 3221225472 Sensor_Battery_Level "TPMS Sensor Battery LevelRange of  0 to 100 %Battery Full - 100 % Battery low  - 0 %";
CM_ SG_ 3221225472 Sensor_RSSI "Signal strength between TPMS sensor and CAN Receiver Range of 0 to 100 dBm";
CM_ SG_ 3221225472 CTI_Wheel_End_Electrical_Fault "Indicates the status of electrical fault on CTI wheel interface.00 Ok ( No Fault)01 Not Defined10 Error11 Not SupportedNot used : set as 11";
CM_ SG_ 3221225472 CTI_Tire_Status "Indicates the status of the tire.00 Ok (no fault)01 Tire leak detected10 Error11 Not SupportedNot used : set as 11";
CM_ SG_ 3221225472 Sensor_Status "Indicates whether the current sensor data is received by the receiver 00 Data received (New data received)01 Data appended update same data from last 2 min )10 Data missing (Data not received )11 Not Supported";
CM_ SG_ 3221225472 Tire_Temperature "Temperature at the surface of the tire sidewall.Tire Temperature in  deg c = (Tire temperature * Multiplication factor) - Temperature offset Multiplication factor = 0.03125 Temperature offset = 273";
CM_ SG_ 3221225472 Tire_Pressure "Pressure at which air is contained in cavity formed by tire and rim.Pressure range of 0 to 1400 Kpa , data sent with multiplication factor of 5.5 kpa pressure value in kpa = (Pressure value * 5.5)";
CM_ SG_ 3221225472 Tire_Location "Tire Location 1. If standard mode selected it will sent data as per standard rule 2. If custom mode selected then it is sent as given below. The position value will start from 0x01.The value 0xFF indicates not available.";
CM_ SG_ 3221225472 IVT_Voltage_Inlet_Value "Results as signed long";
CM_ SG_ 3221225472 IVT_Voltage_Inlet_ResultState "Errorcode. bit 0: OCS. bit 1: result is out of range; this result has reduced precision;  this result has a measurement-error. bit 2: any result has a measurement-error. bit 3: system-error, sensor functionality is not ensured!";
CM_ SG_ 3221225472 IVT_Voltage_Inlet_MsgCount "Cyclic counter";
CM_ SG_ 3221225472 IVT_Voltage_Inlet_MuxId "Multiplexer channel number. IVT_Inlet_Result  = 0x02";
CM_ SG_ 3221225472 IVT_Voltage_Vehicle_Value "Results as signed long";
CM_ SG_ 3221225472 IVT_Voltage_Vehicle_ResultState "Errorcode. bit 0: OCS. bit 1: result is out of range; this result has reduced precision;  this result has a measurement-error. bit 2: any result has a measurement-error. bit 3: system-error, sensor functionality is not ensured!";
CM_ SG_ 3221225472 IVT_Voltage_Vehicle_MsgCount "Cyclic counter";
CM_ SG_ 3221225472 IVT_Voltage_Vehicle_MuxId "Multiplexer channel number. IVT_Vehicle_Result  = 0x01";
CM_ SG_ 3221225472 IVT_Current_Value "Results as signed long";
CM_ SG_ 3221225472 IVT_Current_ResultState "Errorcode. bit 0: OCS. bit 1: result is out of range; this result has reduced precision;  this result has a measurement-error. bit 2: any result has a measurement-error. bit 3: system-error, sensor functionality is not ensured!";
CM_ SG_ 3221225472 IVT_Current_MsgCount "Cyclic counter";
CM_ SG_ 3221225472 IVT_Current_MuxId "Multiplexer channel number. IVT_Current_Result  = 0x00";
CM_ SG_ 3221225472 CCL_ControlPilotState "measured control pilot state";
CM_ SG_ 3221225472 CCL_ACChargingPossible "Signals, that the CCL is ready that the VCU can contol the OBC to charge";
CM_ SG_ 3221225472 CCL_ProximityPinState "CCS Rype of plug and max current measured at PP Resistor";
CM_ SG_ 3221225472 CCL_ControlPilotDutyCycle "Measured CP Dutycycle";
CM_ SG_ 3221225472 CCL_InletACTemperature "actual AC inlet temperature could be used to limit target current to reduce temperature";
CM_ SG_ 3221225472 CCL_HVPlugTemperature "actual HV Plug temperature could be used to limit  target current to reduce temperature";
CM_ SG_ 3221225472 CCL_HVSwitchTemperature "actual HV switch temperature could be used to limit target target current to reduce temperature";
CM_ SG_ 3221225472 CCL_InletDCTemperature "actual DC inlet temperature could be used to limit target current to reduce temperature";
CM_ SG_ 3221225472 EVSE_EVSEID "Any ID that uniquely identifies the EVSE. The format of this message element is defined in DIN SPEC 91286. If an SECC cannot provide such ID data, the value of the EVSEID is set to zero (00hex).";
CM_ SG_ 3221225472 VCU_EVCCID "Specifies the EV's identification in a readable format. It contains the MAC address of the EVCC as six hexBinary encoded bytes, i.e. the element shall have a length of six bytes.";
CM_ SG_ 3221225472 VCU_LED4PWM "optional signal:CCL provides 4 LEDs which can be controlled external.if external control is requested (Parameter) the VCU can provide actual PWM value for LED4";
CM_ SG_ 3221225472 VCU_LED3PWM "optional signal:CCL provides 4 LEDs which can be controlled external.if external control is requested (Parameter) the VCU can provide actual PWM value for LED3";
CM_ SG_ 3221225472 VCU_LED2PWM "optional signal:CCL provides 4 LEDs which can be controlled external.if external control is requested (Parameter) the VCU can provide actual PWM value for LED2";
CM_ SG_ 3221225472 VCU_LED1PWM "optional signal:CCL provides 4 LEDs which can be controlled external.if external control is requested (Parameter) the VCU can provide actual PWM value for LED1";
CM_ SG_ 3221225472 EVSE_PresentVoltage "Present voltage of EVSE";
CM_ SG_ 3221225472 EVSE_PresentCurrent "Present current of EVSE";
CM_ SG_ 3221225472 VCU_InletVoltage "optional safety signalif CCL does not measure the inlet voltage the VCU can provide the measured voltage via this signal.";
CM_ SG_ 3221225472 VCU_HVSW2State "The signal represents the state of VCU controlled HVSW2";
CM_ SG_ 3221225472 VCU_HVSW1State "The signal represents the state of VCU controlled HVSW1";
CM_ SG_ 3221225472 VCU_CRC "CRC for safety message (only necessary if safety is required";
CM_ SG_ 3221225472 VCU_SequenceCounter "part of safety message validation";
CM_ SG_ 3221225472 VCU_VehicleVoltage "optional safety signalif CCL does not measure the vehicle voltage the VCU can provide the measured voltage via this signal.";
CM_ SG_ 3221225472 VCU_EmergencySeparation "Safety signal:(parametrizable)Send cyclic from VCU to the CCL if no FALSE is received, the CCL switches to safe state";
CM_ SG_ 3221225472 CCL_HVSW2StateRequest "The signal represents the requested state of VCU controlled HVSW2";
CM_ SG_ 3221225472 CCL_HVSW1StateRequest "The signal represents the requested state of VCU controlled HVSW1";
CM_ SG_ 3221225472 CCL_SequenceCounter "part of safety message validation";
CM_ SG_ 3221225472 CCL_CRC "CRC for safety message (only necessary if safety is required";
CM_ SG_ 3221225472 CCL_IL_HVInlet "Optioanl safety signalThe CCL informs the VCU about the correct connected HV-Plug inter lock to the inlet.";
CM_ SG_ 3221225472 CCL_IL_HVGrid "Optioanl safety signalThe CCL informs the VCU about the correct connected HV-Plug inter lock to the vehicle-grid.";
CM_ SG_ 3221225472 CCL_EmergencyShutdown "With this signal the CCL informs the VCU, that there is an active reason for an emergency shutdown";
CM_ SG_ 3221225472 CCL_PlugState "Safety Signal (Prevent drive off). Based on CCL drive off possible im NO_PLUG is received.The CCL reports if a plug is present at the inlet or not. The CCL differs between only PP detected (mode 1 AC charging) and CP and PP detected (AC /DC)";
CM_ SG_ 3221225472 VCU_EVCabinConditioning "Optional Element for UI Purpose:To signal  that CabinConditioning is active";
CM_ SG_ 3221225472 VCU_EVRESSConditioning "Optional Element for UI Purpose:To signal  that REDDConditioning is active";
CM_ SG_ 3221225472 VCU_EVRemainingTimeToFullSoC "Optional Element:Estimated or calculated time until full charge (EVFULLSOC) is complete";
CM_ SG_ 3221225472 VCU_EVRemainingTimeToBulkSoC "Optional Element:Estimated or calculated time until bulk charge (EVBulkSOC) is complete";
CM_ SG_ 3221225472 VCU_EVBulkChargingComplete "Optional Element for UI Purpose: (fast charging)If set to TRUE, the EV indicates that bulk charge (EVBulkSOC) is complete.";
CM_ SG_ 3221225472 VCU_EVFullSOC "Optional Element:SOC at which the EV considers the battery to be fully charged";
CM_ SG_ 3221225472 VCU_EVBulkSOC "Optional Element for UI purpose:will be displayed on EVSE (if supported) to provide the charging state to the user for fast charging.";
CM_ SG_ 3221225472 CCL_HWVersion "Informative signalHardware version of the CCL";
CM_ SG_ 3221225472 CCL_CANVersion "The CCL provides the implemented and supported Version of the CAN Matrix.";
CM_ SG_ 3221225472 CCL_SWMajorVersion "SW major version to identify SW version";
CM_ SG_ 3221225472 CCL_SWBuildVersion "SW built to identify SW version";
CM_ SG_ 3221225472 CCL_SWMinorVersion "SW minor version to identify SW version";
CM_ SG_ 3221225472 EVSE_MinimumCurrentLimit "Minimum current the EVSE can deliver with the expected accuracy";
CM_ SG_ 3221225472 EVSE_MinimumVoltageLimit "Minimum voltage the EVSE can deliver with the expected accuracy";
CM_ SG_ 3221225472 EVSE_State "Indicates if the internal state of the EVSE.";
CM_ SG_ 3221225472 EVSE_EnergyToBeDelivered "Optional Element:Amount of energy to be delivered by the EVSE";
CM_ SG_ 3221225472 EVSE_PeakCurrentRipple "Peak-to-peak magnitude of the current ripple of the EVSE";
CM_ SG_ 3221225472 EVSE_CurrentRegTolerance "Optional Element:Absolute magnitude of the regulation tolerance of the EVSE";
CM_ SG_ 3221225472 EVSE_CurrentLimitAchieved "True if the EVSE can not provide more current";
CM_ SG_ 3221225472 EVSE_VoltageLimitAchieved "If set to TRUE, the EVSE has reached its voltage limit";
CM_ SG_ 3221225472 EVSE_PowerLimitAchieved "If set to TRUE, the EVSE has reached its power limit";
CM_ SG_ 3221225472 CCL_ActualChargingProtocol "Actual charging protocol agreed between CCL and EV";
CM_ SG_ 3221225472 CCL_DTC_RSL "The CCL needs to set a red stop light if the vehicle needs to be stopped directly due to an CCL error.";
CM_ SG_ 3221225472 CCL_DTC_PL "The CCL detects a malfunction caused by a reversible failure.";
CM_ SG_ 3221225472 CCL_DTC_AWL "Diagnose message amber warning light if the CCL detects an error and needs maintainance.";
CM_ SG_ 3221225472 CCL_ChargingMode "Informative signalThe CCL can support AC (with additional OBC) and DC charging and provides the choosen charging mode to the VCU.If the the connected EVSE is not compatible the signal will switch to not_supported.";
CM_ SG_ 3221225472 CCL_WakeUpReason "informative signalWake up source of the CCLPlug connected/disconnectedCAN-communication (VCU/CHARGING)wake up pin";
CM_ SG_ 3221225472 CCL_LockState "Informative signal about the inlet lock state based on lock fbk signal.The CCL supports a lock fbk measurement with a closed feedback and optional additional fbk for open.If no dedicated open fbk is detectable motor position is used";
CM_ SG_ 3221225472 CCL_HVSWState "The signal represents the summarised state of the controlled HVSWs which is send via CAN";
CM_ SG_ 3221225472 CCL_TargetCurrent "Actual target current send to EVSE:PreCharging-> PreChargeCurrentPowerReduction-> lowered currentnormal-> From VCU receive target current";
CM_ SG_ 3221225472 CCL_State "informative signalinternal state of the CCL";
CM_ SG_ 3221225472 EVSE_MaximumCurrentLimit "Maximum current the EVSE can deliver";
CM_ SG_ 3221225472 EVSE_MaximumVoltageLimit "Maximum voltage the EVSE can deliver";
CM_ SG_ 3221225472 EVSE_MaximumPowerLimit "Optional Element:Maximum power the EVSE can deliver";
CM_ SG_ 3221225472 CCL_ShutdownRequest "informative signalThis signal combines an internal (CCL) and external (EVSE) shutdown signal (button press) to inform the VCU, that a shutdown is triggered.A shutdown can be denied by the VCU (based on parameter), an emergency shutdown not.";
CM_ SG_ 3221225472 CCL_ErrorNumber "Message to provide error reason";
CM_ SG_ 3221225472 EVSE_StatusCode "abstract state of EVSE from external view";
CM_ SG_ 3221225472 CCL_ButtonState "Informative signal.The CCL measures the state of the charge stop button and provides the signal to the VCU.The Button is an optional user interface to wake up the CCL and to quit a charging sequence.";
CM_ SG_ 3221225472 VCU_EVEnergyRequest "Optional Element:Amount of energy the EV requests from the EVSE";
CM_ SG_ 3221225472 VCU_EVTargetCurrent "Current demanded by EV";
CM_ SG_ 3221225472 VCU_EVTargetVoltage "Target Voltage requested by EV";
CM_ SG_ 3221225472 VCU_EVSOC "State of charge of the EV's battery";
CM_ SG_ 3221225472 VCU_EVError "Indicates the EV internal status and errors mandatory for the EVSE.";
CM_ SG_ 3221225472 VCU_EVDCMaximumCurrentLimit "Maximum current supported by the EV";
CM_ SG_ 3221225472 VCU_EVDCMaximumPowerLimit "Optional Element:Maximum power supported by the EV";
CM_ SG_ 3221225472 VCU_EVDCMaximumVoltageLimit "Maximum voltage supported by the EV";
CM_ SG_ 3221225472 VCU_EVEnergyCapacity "Optional Element:Maximum energy capacity supported by the EV";
CM_ SG_ 3221225472 VCU_LockPermission "Mandatory SignalVCU->CCLParmission to close the inlet lock.";
CM_ SG_ 3221225472 VCU_UnlockPermission "Mandatory signal:VCU->CCLPermission to open the LockFor AC Charging the charging cable is removable so the closed lock is a kind of thief protection.";
CM_ SG_ 3221225472 VCU_HVReady "Mandatory SignalVCU-> CCL to communicate, that the HV-System of the vehicle is started up and measured voltage of HV-Grid is valid";
CM_ SG_ 3221225472 VCU_ChargePermission "Mandatory Signal:Permission to connect EV/ EVSE HV-Systems by closing HV-Switches";
CM_ SG_ 3221225472 TotalVehicleDistance_ODO "Accumulated distance traveled by vehicle during its operation.";
CM_ SG_ 3221225472 TripDistance "Distance traveled during all or part of a journey.";
CM_ SG_ 3221225472 Traction_Battery_Total_Used "Accumulated amount of fuel used during vehicle operation.  See SPN 5054 for alternate resolution.";
CM_ SG_ 3221225472 Traction_Motor_Temp "Temperature of liquid found in engine cooling system.";
CM_ SG_ 3221225472 Motor_Speed_RPM "Actual engine speed which is calculated over a minimum crankshaft angle of 720 degrees divided by the number of ...";
CM_ SG_ 3221225472 WheelBasedVehicleSpeed "Speed of the vehicle as calculated from wheel or tailshaft speed.";
CM_ SG_ 3221225472 VEHICLE_IMMOBILIZE "0 : Vehicle Mobilize1 : Vehicle Immobilize";
CM_ SG_ 3221225472 GUN_LOCK_FAULT "0 : Gun Lock OK1 : Gun Lock Fault Detected";
CM_ SG_ 3221225472 TEMP_2_FAULT "0 : Temperature is under set limit1 : Temperature Greater Than set limit";
CM_ SG_ 3221225472 TEMP_1_FAULT "0 : Temperature is under set limit1 : Temperature Greater Than set limit";
CM_ SG_ 3221225472 DIFFERENTIAL_CURRENT_MEAS "Deviation of Set current with Actual current";
CM_ SG_ 3221225472 NEGATIVE_CONTACTOR_CONTROL "0 : Open charging contactor1 : Close charging contactor";
CM_ SG_ 3221225472 CHARGING_STATUS "0 : Vehicle not charging1 : Vehicle charging";
CM_ SG_ 3221225472 POSITIVE_CONTACTOR_CONTROL "0 : Open charging contactor1 : Close charging contactor";
CM_ SG_ 3221225472 VCU_BenchTestSpeedLimitEnable "Need to limit the motor speed on bench/vehicle for safety reasons";
CM_ SG_ 3221225472 VCU_ZeroTorqueSlope "At the moment of 0 torque, the rate of change of torque";
CM_ SG_ 3221225472 VCU_Mode_R "Reserved";
CM_ SG_ 3221225472 VCU_Mode_Braking "Regeneration";
CM_ SG_ 3221225472 VCU_Reserved "idle";
CM_ SG_ 3221225472 VCU_Mode_D "Forward drive";
CM_ SG_ 3221225472 VCU_ASCEnable "Active short Circuit Function Enable";
CM_ SG_ 3221225472 VCU_HillHoldEnable "Hill hold  function enable";
CM_ SG_ 3221225472 VCU_ControlMode "control mode 0 is torque 1 is speed";
CM_ SG_ 3221225472 VCU_Mode_N "Shut down";
CM_ SG_ 3221225472 VCU_Canlife "VCU Vital Signs";
CM_ SG_ 3221225472 VCU_MainRelay "Main relay status";
CM_ SG_ 3221225472 VCU_PreChargedStatus "Precharge contactor status";
CM_ SG_ 3221225472 VCU_Discharge "Active Discharge Command";
CM_ SG_ 3221225472 VCU_Enable "Enable Signal";
CM_ SG_ 3221225472 VCU_SpdReq "Requested Speed from VCU in Speed mode";
CM_ SG_ 3221225472 VCU_TrqReq "Requested torque from VCU in torque mode";
CM_ SG_ 3221225472 A_BMS_Smoke_Concentration "Smoke concentration measured by thermal sensor";
CM_ SG_ 3221225472 A_BMS_Smoke_Sensor_Status "Smoke sensor status";
CM_ SG_ 3221225472 A_BMS_IR_Value_Neg "Insulation resistance value between HV- to LV-";
CM_ SG_ 3221225472 A_BMS_IR_Value_Pos "Insulation resistance value between HV+ to LV-";
CM_ SG_ 3221225472 A_BMS_Insulation_Value "Pack insulation resistance value";
CM_ SG_ 3221225472 A_BMS_Cell_Temp_N_plus_5 "BMS temperature sensor N+5 value";
CM_ SG_ 3221225472 A_BMS_Cell_Temp_N_plus_4 "BMS temperature sensor N+4 value";
CM_ SG_ 3221225472 A_BMS_Cell_Temp_N_plus_3 "BMS temperature sensor N+3 value";
CM_ SG_ 3221225472 A_BMS_Cell_Temp_N_plus_2 "BMS temperature sensor N+2 value";
CM_ SG_ 3221225472 A_BMS_Cell_Temp_N_plus_1 "BMS temperature sensor N+1 value";
CM_ SG_ 3221225472 A_BMS_Cell_Temp_N "BMS temperature sensor N value";
CM_ SG_ 3221225472 A_BMS_Mux_Temp_Data_Counter "Slave No of temperature data";
CM_ SG_ 3221225472 A_BMS_CRC_18FFF1F3 "CRC of this message";
CM_ SG_ 3221225472 A_BMS_Counter_18FFF1F3 "Rolling counter of this message";
CM_ SG_ 3221225472 A_BMS_P2P_Comm_Status4 "Communication status between current pack and pack D";
CM_ SG_ 3221225472 A_BMS_P2P_Comm_Status3 "Communication status between current pack and pack C";
CM_ SG_ 3221225472 A_BMS_P2P_Comm_Status2 "Communication status between current pack and pack B";
CM_ SG_ 3221225472 A_BMS_P2P_Comm_Status1 "Communication status between current pack and pack A";
CM_ SG_ 3221225472 A_BMS_CCL_Derate "CCL derate indication for parallel pack charge protocal";
CM_ SG_ 3221225472 A_BMS_Pack_Voltage "Pack voltage value";
CM_ SG_ 3221225472 A_BMS_Abs_Current "Pack absolute current value";
CM_ SG_ 3221225472 A_BMS_Pack_No "Pack number";
CM_ SG_ 3221225472 A_BMS_Oper_Mode "BMS operation mode";
CM_ SG_ 3221225472 A_BMS_IR_Measure_Seq "Parallel pack insultation measure sequence";
CM_ SG_ 3221225472 A_BMS_CRC_CFF32F3 "CRC of this message";
CM_ SG_ 3221225472 A_BMS_Counter_CFF32F3 "Rolling counter of this message";
CM_ SG_ 3221225472 A_BMS_Total_No_Cells "Total number of cells";
CM_ SG_ 3221225472 A_BMS_Total_Energy "Total energy";
CM_ SG_ 3221225472 A_BMS_Nominal_Capacity "Nominal Capacity";
CM_ SG_ 3221225472 A_BMS_Nominal_Voltage "Nominal voltage";
CM_ SG_ 3221225472 A_BMS_SW_Version "Master BMS software version";
CM_ SG_ 3221225472 A_BMS_CRC_CFF43F3 "CRC of this message";
CM_ SG_ 3221225472 A_BMS_Counter_CFF43F3 "Rolling counter of this message";
CM_ SG_ 3221225472 A_BMS_Slave_Rolling_Counter "Salve BMS CAN message rolling counter";
CM_ SG_ 3221225472 A_BMS_Slave_Comm_Status "Communication status between master and slave";
CM_ SG_ 3221225472 A_BMS_Slave_Vsense_Status "Slave pack vsense status";
CM_ SG_ 3221225472 A_BMS_Slave_AFE_Status "Slave BMS AFE(Analog front end) status";
CM_ SG_ 3221225472 A_BMS_Slave_LV_Supply "Slave BMS power supply value";
CM_ SG_ 3221225472 A_BMS_Slave_SW_Version "Slave BMS software version";
CM_ SG_ 3221225472 A_BMS_Slave_No "Salve No (multiplexed signal)";
CM_ SG_ 3221225472 A_BMS_CRC_CFF8FF3 "CRC of this message";
CM_ SG_ 3221225472 A_BMS_Counter_CFF8FF3 "Rolling counter of this message";
CM_ SG_ 3221225472 A_BMS_SOC_Diff_Value "Difference between maximum and minimum soc value";
CM_ SG_ 3221225472 A_BMS_SOCCal_Flag "Calibration flag for SOC";
CM_ SG_ 3221225472 A_BMS_Real_SOC "Real SOC value";
CM_ SG_ 3221225472 A_BMS_User_SOC "User SOC value";
CM_ SG_ 3221225472 A_BMS_Smoke_Sensor_RC "Rolling counter of smoke sensor";
CM_ SG_ 3221225472 A_BMS_Coolant_Leak_Value "Coolant leakage sensor ADC value";
CM_ SG_ 3221225472 A_BMS_Vsense_Loose_No "Roll broadcast No. of cells that their vesne loose";
CM_ SG_ 3221225472 A_BMS_DTC_Code "Rolling broadcast BMS DTC code";
CM_ SG_ 3221225472 A_BMS_MapAccumAhSoh "Accumulated AH including charge, discharge and regeneration";
CM_ SG_ 3221225472 A_BMS_SOH_Value "Pack SOH value";
CM_ SG_ 3221225472 A_BMS_Coolant_Temp_Out "Outlet coolant temperature";
CM_ SG_ 3221225472 A_BMS_Coolant_Temp_In "Inlet coolant temperature";
CM_ SG_ 3221225472 A_BMS_Min_Cell_Temp_No "Min temperature cell Number";
CM_ SG_ 3221225472 A_BMS_Max_Cell_Temp_No "Max temperature cell number";
CM_ SG_ 3221225472 A_BMS_Min_Cell_Temp "Min cell temperature";
CM_ SG_ 3221225472 A_BMS_Max_Cell_Temp "Max cell temperature";
CM_ SG_ 3221225472 A_BMS_Min_Cell_Volt_No "Min voltage cell Number";
CM_ SG_ 3221225472 A_BMS_Max_Cell_Volt_No "Max voltage cell number";
CM_ SG_ 3221225472 A_BMS_Min_Cell_Volt "Min cell voltage";
CM_ SG_ 3221225472 A_BMS_Max_Cell_Volt "Max cell voltage";
CM_ SG_ 3221225472 A_BMS_CRC_18FFF0F3 "CRC of this message";
CM_ SG_ 3221225472 A_BMS_Counter_18FFF0F3 "Rolling counter of this message";
CM_ SG_ 3221225472 A_BMS_BMS_Cell_Sum_Volt "Sum of cell voltage";
CM_ SG_ 3221225472 A_BMS_Pack_Voltage_V2 "Voltage for negative contactor status monitor";
CM_ SG_ 3221225472 A_BMS_Pack_Voltage_V3 "Pack voltage between rear end of positive contactor and front end of negative contactor";
CM_ SG_ 3221225472 A_BMS_Pack_Voltage_V1 "Pack voltage between front end of positive and negative contactors";
CM_ SG_ 3221225472 A_BMS_CRC_CFF8BF3 "CRC of this message";
CM_ SG_ 3221225472 A_BMS_Counter_CFF8BF3 "Rolling counter of this message";
CM_ SG_ 3221225472 A_BMS_Chrg_Curr_Limit "Charge curent limit";
CM_ SG_ 3221225472 A_BMS_Regen_Curr_Limit "Regen curent limit";
CM_ SG_ 3221225472 A_BMS_Dischg_Curr_Limit "Discharge current limit";
CM_ SG_ 3221225472 A_BMS_CRC_CFF8DF3 "CRC of this message";
CM_ SG_ 3221225472 A_BMS_Counter_CFF8DF3 "Rolling counter of this message";
CM_ SG_ 3221225472 A_BMS_Balacing_Cell_No "No of cells getting balanced";
CM_ SG_ 3221225472 A_BMS_Balance_Enable_Flag "Balancing enable flag";
CM_ SG_ 3221225472 A_BMS_Pack_Curr "Pack current value";
CM_ SG_ 3221225472 A_BMS_Fault_Rank "Highest fault rank";
CM_ SG_ 3221225472 A_BMS_Wake_Up_Source "BMS wake up signal";
CM_ SG_ 3221225472 A_BMS_Key_Status "KL15(key/wakeup) status detected by BMS";
CM_ SG_ 3221225472 A_BMS_IR_Enable_Flag "Insulation measurement enable flag";
CM_ SG_ 3221225472 A_BMS_LV_Power_Supply "BMS master LV power supply enable flag";
CM_ SG_ 3221225472 A_BMS_Pre_Relay_Status "Relection of HV precharge contactor command giving by BMS";
CM_ SG_ 3221225472 A_BMS_Neg_Relay_Status "Relection of HV negative contactor command giving by BMS";
CM_ SG_ 3221225472 A_BMS_Pos_Relay_Status "Relection of HV positive contactor command giving by BMS";
CM_ SG_ 3221225472 A_BMS_HV_Circuit_Status "Indicate whether HV is engaged or not";
CM_ SG_ 3221225472 A_BMS_HVIL_Status "Pack HVIL status";
CM_ SG_ 3221225472 A_BMS_Charging_Done "Charging completed";
CM_ SG_ 3221225472 A_BMS_Pack_Ready "Pack ready";
CM_ SG_ 3221225472 B_BMS_Smoke_Concentration "Smoke concentration measured by thermal sensor";
CM_ SG_ 3221225472 B_BMS_Smoke_Sensor_Status "Smoke sensor status";
CM_ SG_ 3221225472 B_BMS_IR_Value_Neg "Insulation resistance value between HV- to LV-";
CM_ SG_ 3221225472 B_BMS_IR_Value_Pos "Insulation resistance value between HV+ to LV-";
CM_ SG_ 3221225472 B_BMS_Insulation_Value "Pack insulation resistance value";
CM_ SG_ 3221225472 B_BMS_Cell_Temp_N_plus_5 "BMS temperature sensor N+5 value";
CM_ SG_ 3221225472 B_BMS_Cell_Temp_N_plus_4 "BMS temperature sensor N+4 value";
CM_ SG_ 3221225472 B_BMS_Cell_Temp_N_plus_3 "BMS temperature sensor N+3 value";
CM_ SG_ 3221225472 B_BMS_Cell_Temp_N_plus_2 "BMS temperature sensor N+2 value";
CM_ SG_ 3221225472 B_BMS_Cell_Temp_N_plus_1 "BMS temperature sensor N+1 value";
CM_ SG_ 3221225472 B_BMS_Cell_Temp_N "BMS temperature sensor N value";
CM_ SG_ 3221225472 B_BMS_Mux_Temp_Data_Counter "Slave No of temperature data";
CM_ SG_ 3221225472 B_BMS_CRC_18FFF3F4 "CRC of this message";
CM_ SG_ 3221225472 B_BMS_Counter_18FFF3F4 "Rolling counter of this message";
CM_ SG_ 3221225472 B_BMS_P2P_Comm_Status4 "Communication status between current pack and pack D";
CM_ SG_ 3221225472 B_BMS_P2P_Comm_Status3 "Communication status between current pack and pack C";
CM_ SG_ 3221225472 B_BMS_P2P_Comm_Status2 "Communication status between current pack and pack B";
CM_ SG_ 3221225472 B_BMS_P2P_Comm_Status1 "Communication status between current pack and pack A";
CM_ SG_ 3221225472 B_BMS_CCL_Derate "CCL derate indication for parallel pack charge protocal";
CM_ SG_ 3221225472 B_BMS_Pack_Voltage "Pack voltage value";
CM_ SG_ 3221225472 B_BMS_Abs_Current "Pack absolute current value";
CM_ SG_ 3221225472 B_BMS_Pack_No "Pack number";
CM_ SG_ 3221225472 B_BMS_Oper_Mode "BMS operation mode";
CM_ SG_ 3221225472 B_BMS_IR_Measure_Seq "Parallel pack insultation measure sequence";
CM_ SG_ 3221225472 B_BMS_CRC_18FF38F4 "CRC of this message";
CM_ SG_ 3221225472 B_BMS_Counter_18FF38F4 "Rolling counter of this message";
CM_ SG_ 3221225472 B_BMS_Total_No_Cells "Total number of cells";
CM_ SG_ 3221225472 B_BMS_Total_Energy "Total energy";
CM_ SG_ 3221225472 B_BMS_Nominal_Capacity "Nominal Capacity";
CM_ SG_ 3221225472 B_BMS_Nominal_Voltage "Nominal voltage";
CM_ SG_ 3221225472 B_BMS_SW_Version "Master BMS software version";
CM_ SG_ 3221225472 B_BMS_CRC_CFFB5F4 "CRC of this message";
CM_ SG_ 3221225472 B_BMS_Counter_CFFB5F4 "Rolling counter of this message";
CM_ SG_ 3221225472 B_BMS_Slave_Rolling_Counter "Salve BMS CAN message rolling counter";
CM_ SG_ 3221225472 B_BMS_Slave_Comm_Status "Communication status between master and slave";
CM_ SG_ 3221225472 B_BMS_Slave_Vsense_Status "Slave pack vsense status";
CM_ SG_ 3221225472 B_BMS_Slave_AFE_Status "Slave BMS AFE(Analog front end) status";
CM_ SG_ 3221225472 B_BMS_Slave_LV_Supply "Slave BMS power supply value";
CM_ SG_ 3221225472 B_BMS_Slave_SW_Version "Slave BMS software version";
CM_ SG_ 3221225472 B_BMS_Slave_No "Salve No (multiplexed signal)";
CM_ SG_ 3221225472 B_BMS_CRC_CFFB3F4 "CRC of this message";
CM_ SG_ 3221225472 B_BMS_Counter_CFFB3F4 "Rolling counter of this message";
CM_ SG_ 3221225472 B_BMS_SOC_Diff_Value "Difference between maximum and minimum soc value";
CM_ SG_ 3221225472 B_BMS_SOCCal_Flag "Calibration flag for SOC";
CM_ SG_ 3221225472 B_BMS_Real_SOC "Real SOC value";
CM_ SG_ 3221225472 B_BMS_User_SOC "User SOC value";
CM_ SG_ 3221225472 B_BMS_Smoke_Sensor_RC "Rolling counter of smoke sensor";
CM_ SG_ 3221225472 B_BMS_Coolant_Leak_Value "Coolant leakage sensor ADC value";
CM_ SG_ 3221225472 B_BMS_Vsense_Loose_No "Roll broadcast No. of cells that their vesne loose";
CM_ SG_ 3221225472 B_BMS_DTC_Code "Rolling broadcast BMS DTC code";
CM_ SG_ 3221225472 B_BMS_MapAccumAhSoh "Accumulated AH including charge, discharge and regeneration";
CM_ SG_ 3221225472 B_BMS_SOH_Value "Pack SOH value";
CM_ SG_ 3221225472 B_BMS_Coolant_Temp_Out "Outlet coolant temperature";
CM_ SG_ 3221225472 B_BMS_Coolant_Temp_In "Inlet coolant temperature";
CM_ SG_ 3221225472 B_BMS_Min_Cell_Temp_No "Min temperature cell Number";
CM_ SG_ 3221225472 B_BMS_Max_Cell_Temp_No "Max temperature cell number";
CM_ SG_ 3221225472 B_BMS_Min_Cell_Temp "Min cell temperature";
CM_ SG_ 3221225472 B_BMS_Max_Cell_Temp "Max cell temperature";
CM_ SG_ 3221225472 B_BMS_Min_Cell_Volt_No "Min voltage cell Number";
CM_ SG_ 3221225472 B_BMS_Max_Cell_Volt_No "Max voltage cell number";
CM_ SG_ 3221225472 B_BMS_Min_Cell_Volt "Min cell voltage";
CM_ SG_ 3221225472 B_BMS_Max_Cell_Volt "Max cell voltage";
CM_ SG_ 3221225472 B_BMS_CRC_18FFF2F4 "CRC of this message";
CM_ SG_ 3221225472 B_BMS_Counter_18FFF2F4 "Rolling counter of this message";
CM_ SG_ 3221225472 B_BMS_BMS_Cell_Sum_Volt "Sum of cell voltage";
CM_ SG_ 3221225472 B_BMS_Pack_Voltage_V2 "Voltage for negative contactor status monitor";
CM_ SG_ 3221225472 B_BMS_Pack_Voltage_V3 "Pack voltage between rear end of positive contactor and front end of negative contactor";
CM_ SG_ 3221225472 B_BMS_Pack_Voltage_V1 "Pack voltage between front end of positive and negative contactors";
CM_ SG_ 3221225472 B_BMS_CRC_CFFAFF4 "CRC of this message";
CM_ SG_ 3221225472 B_BMS_Counter_CFFAFF4 "Rolling counter of this message";
CM_ SG_ 3221225472 B_BMS_Chrg_Curr_Limit "Charge curent limit";
CM_ SG_ 3221225472 B_BMS_Regen_Curr_Limit "Regen curent limit";
CM_ SG_ 3221225472 B_BMS_Dischg_Curr_Limit "Discharge current limit";
CM_ SG_ 3221225472 B_BMS_CRC_CFFB1F4 "CRC of this message";
CM_ SG_ 3221225472 B_BMS_Counter_CFFB1F4 "Rolling counter of this message";
CM_ SG_ 3221225472 B_BMS_Balacing_Cell_No "No of cells getting balanced";
CM_ SG_ 3221225472 B_BMS_Balance_Enable_Flag "Balancing enable flag";
CM_ SG_ 3221225472 B_BMS_Pack_Curr "Pack current value";
CM_ SG_ 3221225472 B_BMS_Fault_Rank "Highest fault rank";
CM_ SG_ 3221225472 B_BMS_Wake_Up_Source "BMS wake up signal";
CM_ SG_ 3221225472 B_BMS_Key_Status "KL15(key/wakeup) status detected by BMS";
CM_ SG_ 3221225472 B_BMS_IR_Enable_Flag "Insulation measurement enable flag";
CM_ SG_ 3221225472 B_BMS_LV_Power_Supply "BMS master LV power supply enable flag";
CM_ SG_ 3221225472 B_BMS_Pre_Relay_Status "Relection of HV precharge contactor command giving by BMS";
CM_ SG_ 3221225472 B_BMS_Neg_Relay_Status "Relection of HV negative contactor command giving by BMS";
CM_ SG_ 3221225472 B_BMS_Pos_Relay_Status "Relection of HV positive contactor command giving by BMS";
CM_ SG_ 3221225472 B_BMS_HV_Circuit_Status "Indicate whether HV is engaged or not";
CM_ SG_ 3221225472 B_BMS_HVIL_Status "Pack HVIL status";
CM_ SG_ 3221225472 B_BMS_Charging_Done "Charging completed";
CM_ SG_ 3221225472 B_BMS_Pack_Ready "Pack ready";
CM_ SG_ 3221225472 C_BMS_Smoke_Concentration "Smoke concentration measured by thermal sensor";
CM_ SG_ 3221225472 C_BMS_Smoke_Sensor_Status "Smoke sensor status";
CM_ SG_ 3221225472 C_BMS_IR_Value_Neg "Insulation resistance value between HV- to LV-";
CM_ SG_ 3221225472 C_BMS_IR_Value_Pos "Insulation resistance value between HV+ to LV-";
CM_ SG_ 3221225472 C_BMS_Insulation_Value "Pack insulation resistance value";
CM_ SG_ 3221225472 C_BMS_Cell_Temp_N_plus_5 "BMS temperature sensor N+5 value";
CM_ SG_ 3221225472 C_BMS_Cell_Temp_N_plus_4 "BMS temperature sensor N+4 value";
CM_ SG_ 3221225472 C_BMS_Cell_Temp_N_plus_3 "BMS temperature sensor N+3 value";
CM_ SG_ 3221225472 C_BMS_Cell_Temp_N_plus_2 "BMS temperature sensor N+2 value";
CM_ SG_ 3221225472 C_BMS_Cell_Temp_N_plus_1 "BMS temperature sensor N+1 value";
CM_ SG_ 3221225472 C_BMS_Cell_Temp_N "BMS temperature sensor N value";
CM_ SG_ 3221225472 C_BMS_Mux_Temp_Data_Counter "Slave No of temperature data";
CM_ SG_ 3221225472 C_BMS_CRC_18FFF1F5 "CRC of this message";
CM_ SG_ 3221225472 C_BMS_Counter_18FFF1F5 "Rolling counter of this message";
CM_ SG_ 3221225472 C_BMS_P2P_Comm_Status4 "Communication status between current pack and pack D";
CM_ SG_ 3221225472 C_BMS_P2P_Comm_Status3 "Communication status between current pack and pack C";
CM_ SG_ 3221225472 C_BMS_P2P_Comm_Status2 "Communication status between current pack and pack B";
CM_ SG_ 3221225472 C_BMS_P2P_Comm_Status1 "Communication status between current pack and pack A";
CM_ SG_ 3221225472 C_BMS_CCL_Derate "CCL derate indication for parallel pack charge protocal";
CM_ SG_ 3221225472 C_BMS_Pack_Voltage "Pack voltage value";
CM_ SG_ 3221225472 C_BMS_Abs_Current "Pack absolute current value";
CM_ SG_ 3221225472 C_BMS_Pack_No "Pack number";
CM_ SG_ 3221225472 C_BMS_Oper_Mode "BMS operation mode";
CM_ SG_ 3221225472 C_BMS_IR_Measure_Seq "Parallel pack insultation measure sequence";
CM_ SG_ 3221225472 C_BMS_CRC_CFF32F5 "CRC of this message";
CM_ SG_ 3221225472 C_BMS_Counter_CFF32F5 "Rolling counter of this message";
CM_ SG_ 3221225472 C_BMS_Total_No_Cells "Total number of cells";
CM_ SG_ 3221225472 C_BMS_Total_Energy "Total energy";
CM_ SG_ 3221225472 C_BMS_Nominal_Capacity "Nominal Capacity";
CM_ SG_ 3221225472 C_BMS_Nominal_Voltage "Nominal voltage";
CM_ SG_ 3221225472 C_BMS_SW_Version "Master BMS software version";
CM_ SG_ 3221225472 C_BMS_CRC_CFF43F5 "CRC of this message";
CM_ SG_ 3221225472 C_BMS_Counter_CFF43F5 "Rolling counter of this message";
CM_ SG_ 3221225472 C_BMS_Slave_Rolling_Counter "Salve BMS CAN message rolling counter";
CM_ SG_ 3221225472 C_BMS_Slave_Comm_Status "Communication status between master and slave";
CM_ SG_ 3221225472 C_BMS_Slave_Vsense_Status "Slave pack vsense status";
CM_ SG_ 3221225472 C_BMS_Slave_AFE_Status "Slave BMS AFE(Analog front end) status";
CM_ SG_ 3221225472 C_BMS_Slave_LV_Supply "Slave BMS power supply value";
CM_ SG_ 3221225472 C_BMS_Slave_SW_Version "Slave BMS software version";
CM_ SG_ 3221225472 C_BMS_Slave_No "Salve No (multiplexed signal)";
CM_ SG_ 3221225472 C_BMS_CRC_CFF8FF5 "CRC of this message";
CM_ SG_ 3221225472 C_BMS_Counter_CFF8FF5 "Rolling counter of this message";
CM_ SG_ 3221225472 C_BMS_SOC_Diff_Value "Difference between maximum and minimum soc value";
CM_ SG_ 3221225472 C_BMS_SOCCal_Flag "Calibration flag for SOC";
CM_ SG_ 3221225472 C_BMS_Real_SOC "Real SOC value";
CM_ SG_ 3221225472 C_BMS_User_SOC "User SOC value";
CM_ SG_ 3221225472 C_BMS_Smoke_Sensor_RC "Rolling counter of smoke sensor";
CM_ SG_ 3221225472 C_BMS_Coolant_Leak_Value "Coolant leakage sensor ADC value";
CM_ SG_ 3221225472 C_BMS_Vsense_Loose_No "Roll broadcast No. of cells that their vesne loose";
CM_ SG_ 3221225472 C_BMS_DTC_Code "Rolling broadcast BMS DTC code";
CM_ SG_ 3221225472 C_BMS_MapAccumAhSoh "Accumulated AH including charge, discharge and regeneration";
CM_ SG_ 3221225472 C_BMS_SOH_Value "Pack SOH value";
CM_ SG_ 3221225472 C_BMS_Coolant_Temp_Out "Outlet coolant temperature";
CM_ SG_ 3221225472 C_BMS_Coolant_Temp_In "Inlet coolant temperature";
CM_ SG_ 3221225472 C_BMS_Min_Cell_Temp_No "Min temperature cell Number";
CM_ SG_ 3221225472 C_BMS_Max_Cell_Temp_No "Max temperature cell number";
CM_ SG_ 3221225472 C_BMS_Min_Cell_Temp "Min cell temperature";
CM_ SG_ 3221225472 C_BMS_Max_Cell_Temp "Max cell temperature";
CM_ SG_ 3221225472 C_BMS_Min_Cell_Volt_No "Min voltage cell Number";
CM_ SG_ 3221225472 C_BMS_Max_Cell_Volt_No "Max voltage cell number";
CM_ SG_ 3221225472 C_BMS_Min_Cell_Volt "Min cell voltage";
CM_ SG_ 3221225472 C_BMS_Max_Cell_Volt "Max cell voltage";
CM_ SG_ 3221225472 C_BMS_CRC_18FFF0F5 "CRC of this message";
CM_ SG_ 3221225472 C_BMS_Counter_18FFF0F5 "Rolling counter of this message";
CM_ SG_ 3221225472 C_BMS_BMS_Cell_Sum_Volt "Sum of cell voltage";
CM_ SG_ 3221225472 C_BMS_Pack_Voltage_V2 "Voltage for negative contactor status monitor";
CM_ SG_ 3221225472 C_BMS_Pack_Voltage_V3 "Pack voltage between rear end of positive contactor and front end of negative contactor";
CM_ SG_ 3221225472 C_BMS_Pack_Voltage_V1 "Pack voltage between front end of positive and negative contactors";
CM_ SG_ 3221225472 C_BMS_CRC_CFF8DF3 "CRC of this message";
CM_ SG_ 3221225472 C_BMS_Counter_CFF8BF5 "Rolling counter of this message";
CM_ SG_ 3221225472 C_BMS_Chrg_Curr_Limit "Charge curent limit";
CM_ SG_ 3221225472 C_BMS_Regen_Curr_Limit "Regen curent limit";
CM_ SG_ 3221225472 C_BMS_Dischg_Curr_Limit "Discharge current limit";
CM_ SG_ 3221225472 C_BMS_CRC_CFF8DF3 "CRC of this message";
CM_ SG_ 3221225472 C_BMS_Counter_CFF8DF3 "Rolling counter of this message";
CM_ SG_ 3221225472 C_BMS_Balacing_Cell_No "No of cells getting balanced";
CM_ SG_ 3221225472 C_BMS_Balance_Enable_Flag "Balancing enable flag";
CM_ SG_ 3221225472 C_BMS_Pack_Curr "Pack current value";
CM_ SG_ 3221225472 C_BMS_Fault_Rank "Highest fault rank";
CM_ SG_ 3221225472 C_BMS_Wake_Up_Source "BMS wake up signal";
CM_ SG_ 3221225472 C_BMS_Key_Status "KL15(key/wakeup) status detected by BMS";
CM_ SG_ 3221225472 C_BMS_IR_Enable_Flag "Insulation measurement enable flag";
CM_ SG_ 3221225472 C_BMS_LV_Power_Supply "BMS master LV power supply enable flag";
CM_ SG_ 3221225472 C_BMS_Pre_Relay_Status "Relection of HV precharge contactor command giving by BMS";
CM_ SG_ 3221225472 C_BMS_Neg_Relay_Status "Relection of HV negative contactor command giving by BMS";
CM_ SG_ 3221225472 C_BMS_Pos_Relay_Status "Relection of HV positive contactor command giving by BMS";
CM_ SG_ 3221225472 C_BMS_HV_Circuit_Status "Indicate whether HV is engaged or not";
CM_ SG_ 3221225472 C_BMS_HVIL_Status "Pack HVIL status";
CM_ SG_ 3221225472 C_BMS_Charging_Done "Charging completed";
CM_ SG_ 3221225472 C_BMS_Pack_Ready "Pack ready";
CM_ SG_ 3221225472 D_BMS_Smoke_Concentration "Smoke concentration measured by thermal sensor";
CM_ SG_ 3221225472 D_BMS_Smoke_Sensor_Status "Smoke sensor status";
CM_ SG_ 3221225472 D_BMS_IR_Value_Neg "Insulation resistance value between HV- to LV-";
CM_ SG_ 3221225472 D_BMS_IR_Value_Pos "Insulation resistance value between HV+ to LV-";
CM_ SG_ 3221225472 D_BMS_Insulation_Value "Pack insulation resistance value";
CM_ SG_ 3221225472 D_BMS_Cell_Temp_N_plus_5 "BMS temperature sensor N+5 value";
CM_ SG_ 3221225472 D_BMS_Cell_Temp_N_plus_4 "BMS temperature sensor N+4 value";
CM_ SG_ 3221225472 D_BMS_Cell_Temp_N_plus_3 "BMS temperature sensor N+3 value";
CM_ SG_ 3221225472 D_BMS_Cell_Temp_N_plus_2 "BMS temperature sensor N+2 value";
CM_ SG_ 3221225472 D_BMS_Cell_Temp_N_plus_1 "BMS temperature sensor N+1 value";
CM_ SG_ 3221225472 D_BMS_Cell_Temp_N "BMS temperature sensor N value";
CM_ SG_ 3221225472 D_BMS_Mux_Temp_Data_Counter "Slave No of temperature data";
CM_ SG_ 3221225472 D_BMS_CRC_18FFF3F6 "CRC of this message";
CM_ SG_ 3221225472 D_BMS_Counter_18FFF3F6 "Rolling counter of this message";
CM_ SG_ 3221225472 D_BMS_P2P_Comm_Status4 "Communication status between current pack and pack D";
CM_ SG_ 3221225472 D_BMS_P2P_Comm_Status3 "Communication status between current pack and pack C";
CM_ SG_ 3221225472 D_BMS_P2P_Comm_Status2 "Communication status between current pack and pack B";
CM_ SG_ 3221225472 D_BMS_P2P_Comm_Status1 "Communication status between current pack and pack A";
CM_ SG_ 3221225472 D_BMS_CCL_Derate "CCL derate indication for parallel pack charge protocal";
CM_ SG_ 3221225472 D_BMS_Pack_Voltage "Pack voltage value";
CM_ SG_ 3221225472 D_BMS_Abs_Current "Pack absolute current value";
CM_ SG_ 3221225472 D_BMS_Pack_No "Pack number";
CM_ SG_ 3221225472 D_BMS_Oper_Mode "BMS operation mode";
CM_ SG_ 3221225472 D_BMS_IR_Measure_Seq "Parallel pack insultation measure sequence";
CM_ SG_ 3221225472 D_BMS_CRC_18FF38F6 "CRC of this message";
CM_ SG_ 3221225472 D_BMS_Counter_18FF38F6 "Rolling counter of this message";
CM_ SG_ 3221225472 D_BMS_Total_No_Cells "Total number of cells";
CM_ SG_ 3221225472 D_BMS_Total_Energy "Total energy";
CM_ SG_ 3221225472 D_BMS_Nominal_Capacity "Nominal Capacity";
CM_ SG_ 3221225472 D_BMS_Nominal_Voltage "Nominal voltage";
CM_ SG_ 3221225472 D_BMS_SW_Version "Master BMS software version";
CM_ SG_ 3221225472 D_BMS_CRC_CFFB5F6 "CRC of this message";
CM_ SG_ 3221225472 D_BMS_Counter_CFFB5F6 "Rolling counter of this message";
CM_ SG_ 3221225472 D_BMS_Slave_Rolling_Counter "Salve BMS CAN message rolling counter";
CM_ SG_ 3221225472 D_BMS_Slave_Comm_Status "Communication status between master and slave";
CM_ SG_ 3221225472 D_BMS_Slave_Vsense_Status "Slave pack vsense status";
CM_ SG_ 3221225472 D_BMS_Slave_AFE_Status "Slave BMS AFE(Analog front end) status";
CM_ SG_ 3221225472 D_BMS_Slave_LV_Supply "Slave BMS power supply value";
CM_ SG_ 3221225472 D_BMS_Slave_SW_Version "Slave BMS software version";
CM_ SG_ 3221225472 D_BMS_Slave_No "Salve No (multiplexed signal)";
CM_ SG_ 3221225472 D_BMS_CRC_CFFB3F6 "CRC of this message";
CM_ SG_ 3221225472 D_BMS_Counter_CFFB3F6 "Rolling counter of this message";
CM_ SG_ 3221225472 D_BMS_SOC_Diff_Value "Difference between maximum and minimum soc value";
CM_ SG_ 3221225472 D_BMS_SOCCal_Flag "Calibration flag for SOC";
CM_ SG_ 3221225472 D_BMS_Real_SOC "Real SOC value";
CM_ SG_ 3221225472 D_BMS_User_SOC "User SOC value";
CM_ SG_ 3221225472 D_BMS_Smoke_Sensor_RC "Rolling counter of smoke sensor";
CM_ SG_ 3221225472 D_BMS_Coolant_Leak_Value "Coolant leakage sensor ADC value";
CM_ SG_ 3221225472 D_BMS_Vsense_Loose_No "Roll broadcast No. of cells that their vesne loose";
CM_ SG_ 3221225472 D_BMS_DTC_Code "Rolling broadcast BMS DTC code";
CM_ SG_ 3221225472 D_BMS_MapAccumAhSoh "Accumulated AH including charge, discharge and regeneration";
CM_ SG_ 3221225472 D_BMS_SOH_Value "Pack SOH value";
CM_ SG_ 3221225472 D_BMS_Coolant_Temp_Out "Outlet coolant temperature";
CM_ SG_ 3221225472 D_BMS_Coolant_Temp_In "Inlet coolant temperature";
CM_ SG_ 3221225472 D_BMS_Min_Cell_Temp_No "Min temperature cell Number";
CM_ SG_ 3221225472 D_BMS_Max_Cell_Temp_No "Max temperature cell number";
CM_ SG_ 3221225472 D_BMS_Min_Cell_Temp "Min cell temperature";
CM_ SG_ 3221225472 D_BMS_Max_Cell_Temp "Max cell temperature";
CM_ SG_ 3221225472 D_BMS_Min_Cell_Volt_No "Min voltage cell Number";
CM_ SG_ 3221225472 D_BMS_Max_Cell_Volt_No "Max voltage cell number";
CM_ SG_ 3221225472 D_BMS_Min_Cell_Volt "Min cell voltage";
CM_ SG_ 3221225472 D_BMS_Max_Cell_Volt "Max cell voltage";
CM_ SG_ 3221225472 D_BMS_CRC_18FFF2F6 "CRC of this message";
CM_ SG_ 3221225472 D_BMS_Counter_18FFF2F6 "Rolling counter of this message";
CM_ SG_ 3221225472 D_BMS_BMS_Cell_Sum_Volt "Sum of cell voltage";
CM_ SG_ 3221225472 D_BMS_Pack_Voltage_V2 "Voltage for negative contactor status monitor";
CM_ SG_ 3221225472 D_BMS_Pack_Voltage_V3 "Pack voltage between rear end of positive contactor and front end of negative contactor";
CM_ SG_ 3221225472 D_BMS_Pack_Voltage_V1 "Pack voltage between front end of positive and negative contactors";
CM_ SG_ 3221225472 D_BMS_CRC_CFFAFF6 "CRC of this message";
CM_ SG_ 3221225472 D_BMS_Counter_CFFAFF6 "Rolling counter of this message";
CM_ SG_ 3221225472 D_BMS_Chrg_Curr_Limit "Charge curent limit";
CM_ SG_ 3221225472 D_BMS_Regen_Curr_Limit "Regen curent limit";
CM_ SG_ 3221225472 D_BMS_Dischg_Curr_Limit "Discharge current limit";
CM_ SG_ 3221225472 D_BMS_CRC_CFFB1F6 "CRC of this message";
CM_ SG_ 3221225472 D_BMS_Counter_CFFB1F6 "Rolling counter of this message";
CM_ SG_ 3221225472 D_BMS_Balacing_Cell_No "No of cells getting balanced";
CM_ SG_ 3221225472 D_BMS_Balance_Enable_Flag "Balancing enable flag";
CM_ SG_ 3221225472 D_BMS_Pack_Curr "Pack current value";
CM_ SG_ 3221225472 D_BMS_Fault_Rank "Highest fault rank";
CM_ SG_ 3221225472 D_BMS_Wake_Up_Source "BMS wake up signal";
CM_ SG_ 3221225472 D_BMS_Key_Status "KL15(key/wakeup) status detected by BMS";
CM_ SG_ 3221225472 D_BMS_IR_Enable_Flag "Insulation measurement enable flag";
CM_ SG_ 3221225472 D_BMS_LV_Power_Supply "BMS master LV power supply enable flag";
CM_ SG_ 3221225472 D_BMS_Pre_Relay_Status "Relection of HV precharge contactor command giving by BMS";
CM_ SG_ 3221225472 D_BMS_Neg_Relay_Status "Relection of HV negative contactor command giving by BMS";
CM_ SG_ 3221225472 D_BMS_Pos_Relay_Status "Relection of HV positive contactor command giving by BMS";
CM_ SG_ 3221225472 D_BMS_HV_Circuit_Status "Indicate whether HV is engaged or not";
CM_ SG_ 3221225472 D_BMS_HVIL_Status "Pack HVIL status";
CM_ SG_ 3221225472 D_BMS_Charging_Done "Charging completed";
CM_ SG_ 3221225472 D_BMS_Pack_Ready "Pack ready";
CM_ BO_ 2566866471 "REFU AUX DRIVE to VCU";
CM_ BO_ 2566866727 "REFU AUX DRIVE to VCU";
CM_ BO_ 2566866983 "REFU AUX DRIVE to VCU";
CM_ BO_ 2566867239 "REFU AUX DRIVE to VCU";
CM_ SG_ 2499739891 AC_Max_Current "Maximum allowed AC input current. Note: only used in case CP is not available (allowed range is 4A - 125A).";
CM_ SG_ 2499739891 Actual_BatteryCurrent "Actual battery current";
CM_ SG_ 2499739891 Actual_BatteryVoltage "Actual battery voltage";
CM_ BO_ 2565799678 "This PGN is used to send the Address Claiming.";
CM_ SG_ 2566857200 EV_DisconnectingDevice_Status "DC contactors (+/-) status/feedback. Only used if OBC controls DC contactors.";
CM_ SG_ 2566857200 PLC_available "PLC communication modue is available.";
CM_ SG_ 2566857200 CCS_AC_ContactTemp_Sens "CCS Type2 Inlet AC contact temperature sensor status";
CM_ SG_ 2566857200 CCS_DC_ContactTempSens "CCS Type2 Inlet DC contact temperature sensor status.";
CM_ SG_ 2566857200 DC_charging_active "DC charging is active";
CM_ SG_ 2566857200 CCS_PlugLockFailure "CCS plug locking failure";
CM_ SG_ 2566857200 Vac_InRange "AC input voltage is in allowed range.";
CM_ SG_ 2566857200 Fac_InRange "Frequency input line is in allowed range.";
CM_ SG_ 2566857200 AC_Mode "3phase AC or single phase AC is connected.";
CM_ SG_ 2566857200 DeratingVoltage "OBC reduce output current because voltage limit is reached";
CM_ SG_ 2566857200 PreChargeRelay_status "Status of the pre-charge relays (internal OBC).";
CM_ SG_ 2566857200 MainRelay_status "Status of the main relays (internal OBC).";
CM_ SG_ 2566857200 DeratingTemperature "OBC reduce output power because of heat (temperature too high)";
CM_ SG_ 2566857200 OBC_Availability "One or more of the OBC's are available.";
CM_ SG_ 2566857200 InternalCAN_Error "Internal CAN bus (communication Master OBC to Slave OBC's or ePLC Module) is faulty.";
CM_ SG_ 2566857200 ChargeStopActive "\"external Charge Stop (via X3 connector)\" was detected/is set.";
CM_ SG_ 2566857200 OBC1_StateAct "Actual state of the OBC1 (Master OBC).";
CM_ SG_ 2566857200 OBC2_StateAct "Actual state of the OBC2 (1st Slave OBC).";
CM_ SG_ 2566857200 OBC3_StateAct "Actual state of the OBC3 (2nd Slave OBC).";
CM_ SG_ 2566857200 OBC4_StateAct "Actual state of the OBC4 (3rd Slave OBC).";
CM_ SG_ 2566857200 EV_DisconnectingDevPlus_Status "Optional: DC contactors plus status/feedback. Only used if OBC controls DC contactors.";
CM_ SG_ 2566857200 EV_DisconnectingDevMinus_Status "Optional: DC contactors minus status/feedback. Only used if OBC controls DC contactors.";
CM_ SG_ 2566857456 OBC1_Error "Sum Error flag of the Master OBC.";
CM_ SG_ 2566857456 OBC2_Error "Sum Error flag of the 1st slave OBC.";
CM_ SG_ 2566857456 OBC3_Error "Sum Error flag of the 2nd slave OBC.";
CM_ SG_ 2566857456 OBC4_Error "Sum Error flag of the 3rd slave OBC.";
CM_ SG_ 2566857456 OBC1_OverTemp "Internal over temperature Master OBC.";
CM_ SG_ 2566857456 OBC2_OverTemp "Internal over temperature 1st Slave OBC.";
CM_ SG_ 2566857456 OBC3_OverTemp "Internal over temperature 2nd Slave OBC.";
CM_ SG_ 2566857456 OBC4_OverTemp "Internal over temperature 3rd Slave OBC.";
CM_ SG_ 2566857712 OBC_DcHvCurrLimMax "Maximum possible total DC current which can be provided  (depends on number of OBC).";
CM_ SG_ 2566857712 OBC_DcHvVoltLimMax "Maximum possible HV DC Voltage which can be provided";
CM_ SG_ 2566857712 OBC_AcCurrLimMax "Maximum possible AC current (depends on OBC numbers)";
CM_ SG_ 2566857712 OBC_DcPoLimMax "Maximum possible total DC Power which can be provided  (depends on OBC numbers)";
CM_ BO_ 2566857968 "EVCC/OBC to BMS/VCU";
CM_ SG_ 2566857968 OBC_CP_current "Max. AC input current (set by Wallbox) --- control pilot";
CM_ SG_ 2566857968 OBC_PP_current "Absolute max allowed AC current (cable protection) --- proximity pilot";
CM_ SG_ 2566857968 OBC_CAN_Matrix_Version "Implemented CAN matrix version. E.g version 1.5 = 15";
CM_ SG_ 2566857968 CCS_AC_ContactTemp "CCS Type2 AC contact temperature";
CM_ SG_ 2566857968 CCS_DC_ContactTemp "CCS Type2 DC contact temperature";
CM_ BO_ 2566858224 "EVCC/OBC to BMS/VCU";
CM_ SG_ 2566858224 OBC_AcVolt_Act "Actual AC Input Voltage (Average of the 1ph/3ph) --- Master OBC";
CM_ SG_ 2566858224 OBC_AcCurr_Act "Actual AC Input Current (Average of the 1ph/3ph) --- Master OBC";
CM_ SG_ 2566858224 OBC_DCVolt_Act "Actual DC output voltage --- Master OBC";
CM_ SG_ 2566858224 OBC_DCCurr_Act "Actual DC output current --- Master OBC";
CM_ BO_ 2566860272 "EVCC/OBC to BMS/VCU";
CM_ SG_ 2566860272 OBC_Coolant_Temp_1 "Actual temperature of Input water cooling temperature  --- Master OBC";
CM_ SG_ 2566860272 OBC_Coolant_Temp_2 "Actual temperature of Input water cooling temperature (redundant)  --- Master OBC";
CM_ SG_ 2566860272 OBC_SW_Version_Mayor "Will be incremented after a major software change, e.g. new function  --- Master OBC";
CM_ SG_ 2566860272 OBC_SW_Version_Minor "Will be incremented after a minor software change, e.g. parameter change  --- Master OBC";
CM_ SG_ 2566860272 OBC_Serial_Number "OBC serial number";
CM_ SG_ 2349574128 MCU_MAX_ForwardSpeed "MCU forward max. speed";
CM_ SG_ 2349574128 MCU_MAX_ReverseSpeed "MCU reverse max. speed";
CM_ SG_ 2349574128 MCU_MAX_BrakeTorque "Max. permissible braking torque for MCU";
CM_ SG_ 2349574128 MCU_MAX_DriveTorque "Max. permissible driving torque for MCU";
CM_ SG_ 2349508592 MCU_N_FaultNUM "Number of faults";
CM_ SG_ 2349508592 MCU_N_FaultGrade "Fault level";
CM_ SG_ 2349508592 MCU_F_SPEED_OV_WARNING "Speed warning";
CM_ SG_ 2349508592 MCU_F_ACC_UV_WARNING "LV undervoltage warning";
CM_ SG_ 2349508592 MCU_F_MOTOR_TEMP_SENSOR "Motor Temperature Sensor Failure";
CM_ SG_ 2349508592 MCU_F_IGBT_TEMP_SENSOR "IGBT Temperature Sensor Failure";
CM_ SG_ 2349508592 MCU_F_H_W_OC "W-phase hardware overcurrent fault";
CM_ SG_ 2349508592 MCU_F_H_V_OC "V-phase hardware overcurrent fault";
CM_ SG_ 2349508592 MCU_F_H_U_OC "U-phase hardware overcurrent fault";
CM_ SG_ 2349508592 MCU_F_IGBT "IGBT Failure";
CM_ SG_ 2349508592 MCU_F_H_OC "Hardware overcurrent fault";
CM_ SG_ 2349508592 MCU_F_H_OV "Busbar hardware overvoltage faults";
CM_ SG_ 2349508592 MCU_F_ENCORDE "Encoder Failure";
CM_ SG_ 2349508592 MCU_F_LACK_PHASE "Output phase failure";
CM_ SG_ 2349508592 MCU_F_CURRENT_DETECT "Current Detection Fault";
CM_ SG_ 2349508592 MCU_F_GUN_SELF "Throttle self-test malfunction";
CM_ SG_ 2349508592 MCU_F_ACC_UV "LV software undervoltage fault";
CM_ SG_ 2349508592 MCU_F_BUS_OV_H "Severe overvoltage faults";
CM_ SG_ 2349508592 MCU_F_S_OC "Software overcurrent fault";
CM_ SG_ 2349508592 MCU_F_BUS_UV_L "General undervoltage faults";
CM_ SG_ 2349508592 MCU_F_BUS_UV_H "Severe undervoltage faults";
CM_ SG_ 2349508592 MCU_F_BUS_OV_L "General overvoltage faults";
CM_ SG_ 2349508592 MCU_F_CONTROL_OL_L "Controller overload warning fault";
CM_ SG_ 2349508592 MCU_F_CONTROL_OL_H "Controller overload failure";
CM_ SG_ 2349508592 MCU_F_SPEED_OV "Overspeed fault";
CM_ SG_ 2349508592 MCU_F_CAN_OFFLINE "Bus timeout fault";
CM_ SG_ 2349508592 MCU_F_IGBT_OT_L "IGBT general over-temp. faults";
CM_ SG_ 2349508592 MCU_F_IGBT_OT_H "IGBT Severe Over Temp. Failure";
CM_ SG_ 2349508592 MCU_F_MOTOR_OT_L "General motor over-temp. faults";
CM_ SG_ 2349508592 MCU_F_MOTOR_OT_H "Severe motor over-temp. failure";
CM_ SG_ 2349508592 MCU_F_U_UP_IGBT "U-phase upper bridge IGBT failure";
CM_ SG_ 2349508592 MCU_F_U_DOWN_IGBT "U-phase lower bridge IGBT failure";
CM_ SG_ 2349508592 MCU_F_V_UP_IGBT "V-phase upper bridge IGBT failure";
CM_ SG_ 2349508592 MCU_F_V_DOWN_IGBT "V-phase lower bridge IGBT failure";
CM_ SG_ 2349508592 MCU_F_W_UP_IGBT "W-phase upper bridge IGBT failure";
CM_ SG_ 2349508592 MCU_F_W_DOWN_IGBT "W-phase lower bridge IGBT failure";
CM_ SG_ 2349443056 MCU_nMotorTemp "Motor  temperature";
CM_ SG_ 2349443056 MCU_nControllerTemp "Motor controller temperature";
CM_ SG_ 2349443056 MCU_AC_Current "AC effective value";
CM_ SG_ 2349443056 MCU_AC_Voltage "MCU AC Voltage";
CM_ SG_ 2349443056 MCU_DC_Voltage "MCU DC Voltage";
CM_ SG_ 2349377520 MCU_Gear "Reserved";
CM_ SG_ 2349377520 MCU_Run_Direction "Motor direction";
CM_ SG_ 2349377520 MCU_PWM "Enable PWM";
CM_ SG_ 2349377520 MCU_ControlMode "Control Mode";
CM_ SG_ 2349377520 MCU_Ready "Ready";
CM_ SG_ 2349377520 MCU_Fault "Faults";
CM_ SG_ 2349377520 MCU_Drive_or_Brake "DriveRegenerate";
CM_ SG_ 2349377520 MCU_Discharge "Active discharge";
CM_ SG_ 2349377520 MCU_MotorRun "Start/Stop";
CM_ SG_ 2349377520 MCU_Canlife "MCU Life Signal";
CM_ SG_ 2349377520 MCU_reserve1 "Reserved";
CM_ SG_ 2349377520 MCU_nCurrent "DC bus current";
CM_ SG_ 2349377520 MCU_SpdEst "Actual motor Speed";
CM_ SG_ 2349377520 MCU_TrqEst "Motor Output Torque";
BA_DEF_  "BusType" STRING ;
BA_DEF_ BO_  "GenMsgCycleTime" INT 0 65535;
BA_DEF_ SG_  "GenSigStartValue" FLOAT -3.4E+38 3.4E+38;
BA_DEF_DEF_  "BusType" "CAN";
BA_DEF_DEF_  "GenMsgCycleTime" 0;
BA_DEF_DEF_  "GenSigStartValue" 0;
BA_ "GenMsgCycleTime" BO_ 2499739891 100;
BA_ "GenMsgCycleTime" BO_ 2566857200 100;
BA_ "GenMsgCycleTime" BO_ 2566857456 100;
BA_ "GenMsgCycleTime" BO_ 2566857712 100;
BA_ "GenMsgCycleTime" BO_ 2566857968 100;
BA_ "GenMsgCycleTime" BO_ 2566858224 100;
BA_ "GenMsgCycleTime" BO_ 2566860272 100;
BA_ "GenMsgCycleTime" BO_ 2281766656 1000;
BA_ "GenMsgCycleTime" BO_ 2147483904 100;
BA_ "GenMsgCycleTime" BO_ 2147483906 10;
BA_ "GenMsgCycleTime" BO_ 2147483908 100;
BA_ "GenMsgCycleTime" BO_ 2566835255 100;
BA_ "GenMsgCycleTime" BO_ 2566835511 100;
BA_ "GenMsgCycleTime" BO_ 2565808167 100;
BA_ "GenMsgCycleTime" BO_ 2565808183 100;
BA_ "GenMsgCycleTime" BO_ 2147487746 100;
BA_ "GenMsgCycleTime" BO_ 2147547648 100;
BA_ "GenSigStartValue" SG_ 3221225472 EVEnergyRequest 32767;
BA_ "GenSigStartValue" SG_ 3221225472 EVEnergyCapacity 32767;
BA_ "GenSigStartValue" SG_ 3221225472 EVSECompatible 3;
BA_ "GenSigStartValue" SG_ 3221225472 VoltageMatch 3;
BA_ "GenSigStartValue" SG_ 3221225472 ControlPilotState 15;
BA_ "GenSigStartValue" SG_ 3221225472 TCPStatus 3;
BA_ "GenSigStartValue" SG_ 3221225472 ActualChargeProtocol 15;
BA_ "GenSigStartValue" SG_ 3221225472 ProximityPinState 15;
BA_ "GenSigStartValue" SG_ 3221225472 EVWeldingDetectionEnable 3;
BA_ "GenSigStartValue" SG_ 3221225472 EVReady 3;
BA_ "GenSigStartValue" SG_ 3221225472 ChargeStopIndication 3;
BA_ "GenSigStartValue" SG_ 3221225472 ChargeProgressIndication 3;
BA_ "GenSigStartValue" SG_ 3221225472 EVRESSConditioning 3;
BA_ "GenSigStartValue" SG_ 3221225472 EVTimeToFullSoC 262142;
BA_ "GenSigStartValue" SG_ 3221225472 EVTimeToBulkSoC 262142;
BA_ "GenSigStartValue" SG_ 3221225472 EVErrorCode 15;
BA_ "GenSigStartValue" SG_ 3221225472 EVCabinConditioning 3;
BA_ "GenSigStartValue" SG_ 3221225472 EVBulkChargingComplete 3;
BA_ "GenSigStartValue" SG_ 3221225472 EVChargingComplete 3;
BA_ "GenSigStartValue" SG_ 3221225472 EVTargetCurrent 32500;
BA_ "GenSigStartValue" SG_ 3221225472 EVSEStatusCode 15;
BA_ "GenSigStartValue" SG_ 3221225472 EVSEPowerLimitAchieved 3;
BA_ "GenSigStartValue" SG_ 3221225472 EVSEVoltageLimitAchieved 3;
BA_ "GenSigStartValue" SG_ 3221225472 EVSECurrentLimitAchieved 3;
BA_ "GenSigStartValue" SG_ 3221225472 EVSEIsolationStatus 7;
BA_ "GenSigStartValue" SG_ 3221225472 EVTargetCurrent 32500;
BA_ "GenSigStartValue" SG_ 3221225472 Tire_Temperature 8736;
BA_ "GenSigStartValue" SG_ 3221225472 CCL_InletACTemperature 500;
BA_ "GenSigStartValue" SG_ 3221225472 CCL_HVPlugTemperature 500;
BA_ "GenSigStartValue" SG_ 3221225472 CCL_HVSwitchTemperature 500;
BA_ "GenSigStartValue" SG_ 3221225472 CCL_InletDCTemperature 500;
BA_ "GenSigStartValue" SG_ 3221225472 EVSE_EnergyToBeDelivered 655.35;
BA_ "GenSigStartValue" SG_ 3221225472 CCL_TargetCurrent 32500;
BA_ "GenSigStartValue" SG_ 2566835255 COMP_Controller_temp 40;
BA_ "GenSigStartValue" SG_ 2565808167 Battery_Temperature 80;
VAL_ 3221225472 ONCmd 0 "OFF" 1 "ON" ;
VAL_ 3221225472 NotOff2Cmd 0 "voltageoff_on" 1 "voltageoff_off default" ;
VAL_ 3221225472 NotOff3Cmd 0 "faststopon" 1 "faststopoffdefault" ;
VAL_ 3221225472 Enable 0 "Disable" 1 "Enable" ;
VAL_ 3221225472 NotHLGResetCmd 0 "voltageoff_on" 1 "voltageoff_off default" ;
VAL_ 3221225472 NotRFGStopCmd 0 "voltageoff_on" 1 "voltageoff_off default" ;
VAL_ 3221225472 SetpointEn 0 "Disable" 1 "Enable" ;
VAL_ 3221225472 AckResetQuit 0 "Disable" 1 "Enable" ;
VAL_ 3221225472 ONCmd 0 "OFF" 1 "ON" ;
VAL_ 3221225472 NotOff2Cmd 0 "voltageoff_on" 1 "voltageoff_off default" ;
VAL_ 3221225472 NotOff3Cmd 0 "faststopon" 1 "faststopoffdefault" ;
VAL_ 3221225472 Enable 0 "Disable" 1 "Enable" ;
VAL_ 3221225472 NotHLGResetCmd 0 "voltageoff_on" 1 "voltageoff_off default" ;
VAL_ 3221225472 NotRFGStopCmd 0 "voltageoff_on" 1 "voltageoff_off default" ;
VAL_ 3221225472 SetpointEn 0 "Disable" 1 "Enable" ;
VAL_ 3221225472 AckResetQuit 0 "Disable" 1 "Enable" ;
VAL_ 3221225472 OBC_charge_enable 0 "OBC_disable" 1 "OBC_enable" 2 "not used" 3 "SNA" ;
VAL_ 3221225472 Plug_lock_request 0 "unlock" 1 "lock" 2 "not used" 3 "SNA" ;
VAL_ 3221225472 EV_DisconnectingDevice 0 "open" 1 "close" 2 "error" 3 "SNA" ;
VAL_ 3221225472 Inlet_LED_Green 0 "LED_off" 1 "LED_on" 2 "LED_blinking" 3 "SNA" ;
VAL_ 3221225472 Inlet_LED_Blue 0 "LED_off" 1 "LED_on" 2 "LED_blinking" 3 "SNA" ;
VAL_ 3221225472 Inlet_LED_Red 0 "LED_off" 1 "LED_on" 2 "LED_blinking" 3 "SNA" ;
VAL_ 3221225472 EV_DisconnectingDevicePlus 0 "open" 1 "close" 2 "not used" 3 "SNA" ;
VAL_ 3221225472 EV_DisconnectingDeviceMinus 0 "open" 1 "close" 2 "not used" 3 "SNA" ;
VAL_ 3221225472 EVEnergyRequest 65535 "SNA" ;
VAL_ 3221225472 EVEnergyCapacity 65535 "SNA" 65279 "Invalid" ;
VAL_ 3221225472 EVSECompatible 3 "SNA" 2 "Error" 1 "True" 0 "False" ;
VAL_ 3221225472 VoltageMatch 3 "SNA" 2 "Invalid" 1 "True" 0 "False" ;
VAL_ 3221225472 ControlPilotState 14 "Invalid" 15 "SNA" 5 "F" 4 "E" 3 "D" 2 "C" 1 "B" 0 "A" ;
VAL_ 3221225472 ControlPilotDutyCycle 126 "Invalid" 127 "SNA" ;
VAL_ 3221225472 TCPStatus 0 "Not_connected" 1 "TCP_connected" 2 "TLS_connected" 3 "SNA" ;
VAL_ 3221225472 ActualChargeProtocol 15 "SNA" 1 "DIN70121" 2 "ISO15118" 3 "Not_supported" 0 "Not_defined" ;
VAL_ 3221225472 Charge_Plug_Locked 0 "unlocked" 1 "locked" 2 "not used" 3 "SNA" ;
VAL_ 3221225472 ProximityPinState 15 "SNA" 14 "Invalid" 6 "Type2_Connected63A" 5 "Type2_Connected32A" 4 "Type2_Connected20A" 3 "Type2_Connected13A" 2 "Type1_ConnectedButtonPressed" 1 "Type1_Connected" 0 "NotConnected" ;
VAL_ 3221225472 StateMachineState 15 "SNA" 0 "Default" 1 "Init" 2 "Authentication" 3 "Parameter" 4 "Isolation" 5 "PreCharge" 6 "Charge" 7 "Welding" 8 "StopCharge" 9 "SessionStop" 10 "ShutOff" 11 "Paused" 12 "Error" ;
VAL_ 3221225472 EVSECurrentRegulationTolerance 254 "Invalid" 255 "SNA" ;
VAL_ 3221225472 EVSEPeakCurrentRipple 254 "Invalid" 255 "SNA" ;
VAL_ 3221225472 EVSEMinVoltage 65535 "SNA" 65279 "Invalid" ;
VAL_ 3221225472 EVSEMinCurrent 65535 "SNA" 65279 "Invalid" ;
VAL_ 3221225472 EVSEEnergyToBeDelivered 65535 "SNA" 65279 "Invalid" ;
VAL_ 3221225472 EVSEMaxPower 65535 "SNA" 65279 "Invalid" ;
VAL_ 3221225472 EVSEMaxVoltage 65535 "SNA" 65279 "Invalid" ;
VAL_ 3221225472 EVSEMaxCurrent 65535 "SNA" 65279 "Invalid" ;
VAL_ 3221225472 EVWeldingDetectionEnable 3 "SNA" 1 "True" 0 "False" ;
VAL_ 3221225472 EVReady 3 "SNA" 1 "True" 0 "False" ;
VAL_ 3221225472 ChargeStopIndication 3 "SNA" 2 "NoStop" 1 "Pause" 0 "Terminate" ;
VAL_ 3221225472 ChargeProgressIndication 3 "SNA" 2 "Renegotiate" 1 "Stop" 0 "Start" ;
VAL_ 3221225472 ChargeProtocolPriority 255 "SNA" 1 "ISO15118_Only" 2 "DIN first, ISO next" 3 "ISO first, DIN next" 0 "DIN70121_Only" ;
VAL_ 3221225472 EVRESSConditioning 3 "SNA" 1 "True" 0 "False" ;
VAL_ 3221225472 EVTimeToFullSoC 262143 "SNA" ;
VAL_ 3221225472 EVTimeToBulkSoC 262143 "SNA" ;
VAL_ 3221225472 EVErrorCode 11 "NoData" 10 "FAILED_SystemIncompatibility" 9 "Reserved C" 8 "Reserved B" 7 "Reserved A" 6 "FAILED_ChargingVoltageOutOfRange" 5 "FAILED_ChargingCurrentdiff" 4 "FAILED_EVRESSMalfunction" 3 "FAILED_ChargerConnectorLockFault" 2 "FAILED_EVShiftPosition" 1 "FAILED_RESSTemperatureInhibit" 0 "NO_ERROR" 15 "SNA" ;
VAL_ 3221225472 EVCabinConditioning 3 "SNA" 1 "True" 0 "False" ;
VAL_ 3221225472 EVBulkChargingComplete 3 "SNA" 1 "True" 0 "False" ;
VAL_ 3221225472 EVChargingComplete 3 "SNA" 1 "True" 0 "False" ;
VAL_ 3221225472 EVSoC 254 "Invalid" 255 "SNA" ;
VAL_ 3221225472 EVPreChargeVoltage 65535 "SNA" 65279 "Invalid" ;
VAL_ 3221225472 EVTargetVoltage 65535 "SNA" 65279 "Invalid" ;
VAL_ 3221225472 EVTargetCurrent 65535 "SNA" 65279 "Invalid" ;
VAL_ 3221225472 EVBulkSoC 254 "Invalid" 255 "SNA" ;
VAL_ 3221225472 EVFullSoC 254 "Invalid" 255 "SNA" ;
VAL_ 3221225472 EVMaxVoltage 65535 "SNA" 65279 "Invalid" ;
VAL_ 3221225472 EVMaxPower 65535 "SNA" 65279 "Invalid" ;
VAL_ 3221225472 EVMaxCurrent 65535 "SNA" 65279 "Invalid" ;
VAL_ 3221225472 EVSEStatusCode 15 "SNA" 14 "Invalid" 11 "Reserved_C" 10 "Reserved_B" 9 "Reserved_A" 8 "Reserved_9" 7 "Reserved_8" 6 "EVSE_Malfunction" 5 "EVSE_EmergencyShutdown" 4 "EVSE_IsolationMonitoringActive" 3 "EVSE_UtilityInterruptEvent" 2 "EVSE_Shutdown" 1 "EVSE_Ready" 0 "EVSE_NotReady" ;
VAL_ 3221225472 EVSEPowerLimitAchieved 3 "SNA" 1 "True" 0 "False" ;
VAL_ 3221225472 EVSEVoltageLimitAchieved 3 "SNA" 1 "True" 0 "False" ;
VAL_ 3221225472 EVSECurrentLimitAchieved 3 "SNA" 1 "True" 0 "False" ;
VAL_ 3221225472 EVSEIsolationStatus 5 "Checking" 7 "SNA" 4 "No_IMD" 3 "Fault" 2 "Warning" 1 "Valid" 0 "Invalid" ;
VAL_ 3221225472 EVSEPresentCurrent 65535 "SNA" ;
VAL_ 3221225472 EVSEPresentVoltage 65535 "SNA" ;
VAL_ 3221225472 EVPreChargeVoltage 65535 "SNA" 65279 "Invalid" ;
VAL_ 3221225472 EVTargetVoltage 65535 "SNA" 65279 "Invalid" ;
VAL_ 3221225472 EVTargetCurrent 65535 "SNA" 65279 "Invalid" ;
VAL_ 3221225472 EVSEBptMinDischargeCurrent 65535 "SNA" ;
VAL_ 3221225472 EVSEBptMaxDischargeCurrent 65535 "SNA" ;
VAL_ 3221225472 EVSEBptGenMode 0 "Unknown" 1 "EVU_connected" 2 "EVU_disconnected" 3 "SNA" ;
VAL_ 3221225472 EVBptTargetEnergyReq 65535 "SNA" ;
VAL_ 3221225472 EVBptMinVoltage 65535 "SNA" ;
VAL_ 3221225472 EVBptMinV2XEnergyReq 65535 "SNA" ;
VAL_ 3221225472 EVBptMaxV2XEnergyReq 65535 "SNA" ;
VAL_ 3221225472 EVBptMinEnergyReq 65535 "SNA" ;
VAL_ 3221225472 EVBptMaxDischargePower 16777215 "SNA" ;
VAL_ 3221225472 EVBptMaxDischargeCurrent 65535 "SNA" ;
VAL_ 3221225472 EVBptMaxEnergyReq 65535 "SNA" ;
VAL_ 3221225472 EVBptMaxChargePower 16777215 "SNA" ;
VAL_ 3221225472 EVBptMaxChargeCurrent 65535 "SNA" ;
VAL_ 3221225472 EVBptMinDischargeCurrent 65535 "SNA" ;
VAL_ 3221225472 EVBptMinChargeCurrent 65535 "SNA" ;
VAL_ 3221225472 EVBptTargetSoc 255 "SNA" ;
VAL_ 3221225472 EVBptReq 0 "False" 1 "True" ;
VAL_ 3221225472 EVBptCat 1 "BasicFeature" 2 "FutureDevelopment" 3 "SNA" ;
VAL_ 3221225472 EVBptMinDischargePower 16777215 "SNA" ;
VAL_ 3221225472 EVBptMinChargePower 16777215 "SNA" ;
VAL_ 3221225472 CCL_ControlPilotState 15 "SNA" 14 "Invalid" 5 "F" 4 "E" 3 "D" 2 "C" 1 "B" 0 "A" ;
VAL_ 3221225472 CCL_ACChargingPossible 0 "False" 1 "True" ;
VAL_ 3221225472 CCL_ProximityPinState 14 "Invalid" 15 "SNA" 6 "Type2_Connected63A" 5 "Type2_Connected32A" 4 "Type2_Connected20A" 3 "Type2_Connected13A" 2 "Type1_Latched" 1 "Type1_Not_Latched" 0 "Not_Connected" ;
VAL_ 3221225472 CCL_ControlPilotDutyCycle 126 "Invalid" 127 "SNA" ;
VAL_ 3221225472 CCL_InletACTemperature 65534 "Error" 65520 "Low" 65505 "High" 65535 "SNA" ;
VAL_ 3221225472 CCL_HVPlugTemperature 65534 "Error" 65535 "SNA" ;
VAL_ 3221225472 CCL_HVSwitchTemperature 65534 "Error" 65535 "SNA" ;
VAL_ 3221225472 CCL_InletDCTemperature 65534 "Error" 65535 "SNA" ;
VAL_ 3221225472 VCU_LED4PWM 1023 "SNA" ;
VAL_ 3221225472 VCU_LED3PWM 1023 "SNA" ;
VAL_ 3221225472 VCU_LED2PWM 1023 "SNA" ;
VAL_ 3221225472 VCU_LED1PWM 1023 "SNA" ;
VAL_ 3221225472 EVSE_PresentVoltage 65535 "SNA" ;
VAL_ 3221225472 EVSE_PresentCurrent 65535 "SNA" ;
VAL_ 3221225472 VCU_InletVoltage 65535 "SNA" ;
VAL_ 3221225472 VCU_HVSW2State 0 "Open" 1 "Closed" 2 "Error" 3 "SNA" ;
VAL_ 3221225472 VCU_HVSW1State 0 "Open" 1 "Closed" 2 "Error" 3 "SNA" ;
VAL_ 3221225472 VCU_VehicleVoltage 65535 "SNA" ;
VAL_ 3221225472 VCU_EmergencySeparation 0 "False" 1 "True" ;
VAL_ 3221225472 CCL_HVSW2StateRequest 3 "SNA" 1 "CLOSED" 0 "OPEN" ;
VAL_ 3221225472 CCL_HVSW1StateRequest 3 "SNA" 1 "CLOSED" 0 "OPEN" ;
VAL_ 3221225472 CCL_IL_HVInlet 3 "SNA" 2 "ERROR" 1 "CLOSED" 0 "OPEN" ;
VAL_ 3221225472 CCL_IL_HVGrid 3 "SNA" 2 "ERROR" 1 "CLOSED" 0 "OPEN" ;
VAL_ 3221225472 CCL_EmergencyShutdown 0 "False" 1 "True" ;
VAL_ 3221225472 CCL_PlugState 0 "NoPlug" 1 "PlugPresent" 2 "ACPlugPresent" 3 "Defect" 15 "SNA" ;
VAL_ 3221225472 VCU_EVCabinConditioning 3 "SNA" 0 "False" 1 "True" ;
VAL_ 3221225472 VCU_EVRESSConditioning 3 "SNA" 0 "False" 1 "True" ;
VAL_ 3221225472 VCU_EVRemainingTimeToFullSoC 262143 "SNA" ;
VAL_ 3221225472 VCU_EVRemainingTimeToBulkSoC 262143 "SNA" ;
VAL_ 3221225472 VCU_EVBulkChargingComplete 3 "SNA" 0 "False" 1 "True" ;
VAL_ 3221225472 VCU_EVFullSOC 255 "SNA" ;
VAL_ 3221225472 VCU_EVBulkSOC 255 "SNA" ;
VAL_ 3221225472 EVSE_MinimumCurrentLimit 65535 "SNA" ;
VAL_ 3221225472 EVSE_MinimumVoltageLimit 65535 "SNA" ;
VAL_ 3221225472 EVSE_State 15 "SNA" 0 "Default" 1 "Init" 2 "Authentification" 3 "Parameter" 4 "Isolation" 5 "PreCharge" 6 "Charge" 7 "Welding" 8 "PowerOff" 9 "SessionOff" 10 "ShutOff" 11 "Reserved" 12 "Error" ;
VAL_ 3221225472 EVSE_EnergyToBeDelivered 65535 "SNA" ;
VAL_ 3221225472 EVSE_PeakCurrentRipple 255 "SNA" ;
VAL_ 3221225472 EVSE_CurrentRegTolerance 255 "SNA" ;
VAL_ 3221225472 EVSE_CurrentLimitAchieved 0 "False" 1 "True" ;
VAL_ 3221225472 EVSE_VoltageLimitAchieved 0 "False" 1 "True" ;
VAL_ 3221225472 EVSE_PowerLimitAchieved 0 "False" 1 "True" ;
VAL_ 3221225472 CCL_ActualChargingProtocol 15 "SNA" 3 "Not_Supported" 2 "ISO15118" 1 "DIN70121" 0 "Not_Defined" ;
VAL_ 3221225472 CCL_DTC_RSL 0 "False" 1 "True" ;
VAL_ 3221225472 CCL_DTC_PL 0 "False" 1 "True" ;
VAL_ 3221225472 CCL_DTC_AWL 0 "False" 1 "True" ;
VAL_ 3221225472 CCL_ChargingMode 7 "SNA" 5 "Mode4" 4 "Mode3" 3 "Mode2" 2 "Mode1" 1 "NotSupported" 0 "None" ;
VAL_ 3221225472 CCL_WakeUpReason 15 "SNA" 4 "CHARGING_CAN" 3 "VCU_CAN" 2 "PlugConnect/Release" 1 "WU_IN" 0 "UnknownReason" ;
VAL_ 3221225472 CCL_LockState 0 "LockOpen" 1 "LockClosed" 2 "Error" 3 "Moving" 4 "Unclear" 15 "SNA" ;
VAL_ 3221225472 CCL_HVSWState 0 "Open" 1 "ReadyToClose" 2 "Closed" 3 "Error" 15 "SNA" ;
VAL_ 3221225472 CCL_TargetCurrent 65535 "SNA" ;
VAL_ 3221225472 CCL_State 0 "StartUp" 1 "StandBy" 2 "Connected" 3 "Charging" 4 "SafeState" 15 "SNA" ;
VAL_ 3221225472 EVSE_MaximumCurrentLimit 65535 "SNA" ;
VAL_ 3221225472 EVSE_MaximumVoltageLimit 65535 "SNA" ;
VAL_ 3221225472 EVSE_MaximumPowerLimit 65535 "SNA" ;
VAL_ 3221225472 CCL_ShutdownRequest 0 "False" 1 "True" ;
VAL_ 3221225472 CCL_ErrorNumber 117 "SafeState_ParamCheck" 116 "SafeState_EmergencyDisconnect" 115 "SafeState_StackUnderflow" 114 "SafeState_StackOverflow" 113 "SafeState_PlatformOvertemperature" 112 "SafeState_E2EProtection_SEQ" 111 "SafeState_E2EProtection_CRC" 110 "SafeState_Overcurrent" 109 "SafeState_Undervoltage" 108 "SafeState_Overvoltage" 107 "SafeState_NoPlugWhileCharging" 106 "SafeState_Overtemp" 105 "SafeState_NegativeCurrentWhileCharging" 104 "SafeState_NoLockWhileHV" 103 "SafeState_CPPlugCtrl" 102 "SafeState_TempCtrl" 101 "SafeState_InletCtrl" 100 "SafeState_SwitchCtrl" 35 "UnknownChargingCurrent" 34 "UnknownInletVoltage" 33 "UnknownVehicleVoltage" 32 "MissingEVSELimits" 31 "MissingDCHighlevelcommunication" 30 "MissingEVMaxVoltage" 29 "MissingEVMaxCurrent" 28 "MissingLockPermission" 27 "ExternalSwitchFailure" 26 "StopReceivedByCommunication" 25 "MaxVoltageIncompatible" 24 "MinVoltageIncompatible" 23 "MinCurrentIncompatible" 22 "S2OpenRequestReceived" 21 "HVSWStartupError" 20 "CP_ValueOutOfRange" 19 "EmergencyDisconnectReceived" 18 "ReverseCurrentFlowOverLimit" 17 "LockLost" 65535 "SNA" 16 "UnknownStatemschineState" 15 "UnknownSwitchState" 14 "UnknownTemperature" 13 "HVSWTimeout" 12 "IsolationTimeout" 11 "HVReadyTimeout" 10 "SECC_ERROR" 9 "LockingNotPossible" 8 "CCL_internal Error" 7 "PreChargeError" 6 "PaymentIncompatible" 5 "IsolationError" 4 "TemperatureToHigh" 3 "PlugNotDetected" 2 "CommunicationIntermitted" 1 "CommnicationIncompatible" 0 "NoError" ;
VAL_ 3221225472 EVSE_StatusCode 14 "Invalid" 15 "SNA" 6 "EVSE_Malfunction" 0 "EVSE_NotReady" 1 "EVSE_Ready" 2 "EVSE_Shutdown" 3 "EVSE_UtilityInterruptEvent" 4 "EVSE_IsolationMonitoringActive" 5 "EVSE_EmergencyShutdown" ;
VAL_ 3221225472 CCL_ButtonState 0 "NotPressed" 1 "Pressed" 2 "Error" 3 "SNA" ;
VAL_ 3221225472 VCU_EVEnergyRequest 65535 "SNA" ;
VAL_ 3221225472 VCU_EVTargetCurrent 65535 "SNA" ;
VAL_ 3221225472 VCU_EVTargetVoltage 65535 "SNA" ;
VAL_ 3221225472 VCU_EVSOC 255 "SNA" ;
VAL_ 3221225472 VCU_EVError 11 "NoData" 10 "FAILED_ChargingSystemIncom" 6 "FAILED_ChargingVoltageOOR" 5 "FAILED_ChargingCurrentdiff" 9 "Reserved_C" 8 "Reserved_B" 7 "Reserved_A" 0 "NO_ERROR" 1 "FAILED_RESSTemperatureInhibit" 2 "FAILED_EVShiftPosition" 3 "FAILED_ChargerConnectorLockFault" 4 "FAILED_EVRESSMalfunction" ;
VAL_ 3221225472 VCU_EVDCMaximumCurrentLimit 65535 "SNA" ;
VAL_ 3221225472 VCU_EVDCMaximumPowerLimit 65535 "SNA" ;
VAL_ 3221225472 VCU_EVDCMaximumVoltageLimit 65535 "SNA" ;
VAL_ 3221225472 VCU_EVEnergyCapacity 65535 "SNA" ;
VAL_ 3221225472 VCU_LockPermission 0 "False" 1 "True" ;
VAL_ 3221225472 VCU_UnlockPermission 0 "False" 1 "True" ;
VAL_ 3221225472 VCU_HVReady 0 "False" 1 "True" ;
VAL_ 3221225472 VCU_ChargePermission 0 "False" 1 "True" ;
VAL_ 3221225472 SELECTED_APP_PROTOCOL 2 "ISO:15118:2:2013" 1 "DIN:70121:2012" 0 "NONE" ;
VAL_ 3221225472 CP_STATE 4 "CP_STATE E" 3 "CP_STATE D" 2 "CP_STATE C" 1 "CP_STATE B" 0 "CP_STATE A" ;
VAL_ 3221225472 EVSE_ERROR_CODE 19 "Wrong_Energy_Transfer_Mode" 18 "No_Charge_Service_Selected" 16 "Charging_Profile_Invalid" 14 "Power_Delivery_Not_Applied" 13 "Wrong_Charge_Parameter" 6 "Payment_Selection_Invalid" 5 "Service_ID_Invalid" 2 "Sequence_Error" 0 "No_Error" ;
VAL_ 3221225472 EVCC_ERROR_CODES 39 "EVSE Emergency" 38 "EVSE Isolation Status Error" 37 "Wrong Charge Parameter" 36 "Locking Actuator Error" 34 "Temperature Fault" 33 "Response Code Error" 32 "Evse Sequence Error" 31 "CP PP Lost" 30 "HeartBeat Error" 27 "Warning No PWM" 26 "Step Precharge" 25 "Step Cable Check" 24 "Step CPD" 23 "Step Auth" 20 "Step Communcation Setup" 15 "Timeout Session Stop Resp" 14 "Timeout Welding Detection Resp" 13 "Timeout Current Demand Resp" 12 "Timeout Power Delivery Resp" 11 "Timeout Precharge Resp" 10 "Timeout Cable Check Resp" 9 "Timeout CPD Response" 8 "Timeout Auth Response" 7 "Timeout Payment Selection Resp" 6 "Timeout Service Discovery Resp" 5 "Timeout Session Setup Response" 4 "Timeout SAP Response" 3 "Timout SDP Sequence" 2 "Timeout Link Detection" 1 "Timeout Slac Sequence" 0 "NONE" ;
VAL_ 3221225472 TERMINATION_DETAIL 9 "EV_Ready Flag Reception Failure" 8 "Extrenal Actuator Unlock" 7 "Actuator Locking Fault" 36 "Emergency PLC Chip Status" 35 "Emergency Pilot Status" 34 "Emergency Proximity Status" 33 "Emergency High Temperature" 32 "Emergency HeartBeat Error" 31 "Emergency From Evse" 6 "Vehicle Hv Failure" 5 "Evse Invalid Isolation Status" 4 "Evse Wrong Charge Parameter" 3 "Evse Wrong Response Code" 0 "NONE" ;
VAL_ 3221225472 HV_READY 1 "Vehicle HV Isolation OK" 0 "Vehicle HV Isolation Failure" ;
VAL_ 3221225472 FORCE_ACTUATOR_UNLOCK 1 "Actuator Unlock ENABLE" 0 "Actuator Unlock DISABLE" ;
VAL_ 3221225472 EV_ERROR_CODE 11 "ErrorCode_NoData" 10 "ChargingSystemIncompatibility" 9 "Reserved_C" 8 "Reserved_B" 7 "Reserved_A" 6 "FAILED_ChargingVoltageOutOfRange" 5 "FAILED_ChargingCurrentDiff" 4 "FAILED_EVRESSMalfunction" 3 "FAILED_ChargerConnectorLockFault" 2 "FAILED_EVShiftPosition" 1 "FAILED_RESSTemperatureInhibit" 0 "NO_Error" ;
VAL_ 3221225472 VEH_STOP_CHARGING_FLAG 1 "Vehicle_Current_Zero" 0 "None" ;
VAL_ 3221225472 CHARGING_COMPLETE_FLAG 1 "Disable Charging" 0 "Enable Charging " ;
VAL_ 3221225472 EV_READY_FLAG 1 "Ready Fro Charging" 0 "Not Ready" ;
VAL_ 3221225472 EVSE_Protocol_Priority_Selection 1 "ISO 15118-2:2013" 0 "DIN SPEC 70121:2014" ;
VAL_ 3221225472 VEHICLE_IMMOBILIZE 1 "Vehicle Immobilise" 0 "Vehicle Mobilise" ;
VAL_ 3221225472 EVCC_GUN_UNLOCK_REQUEST_STATUS 1 "GUN Unlock Req Pending" 0 "GUN Unlock Req Processed" ;
VAL_ 3221225472 EVCC_GUN_LOCK_REQUEST_STATUS 1 "GUN Lock Req Pending" 0 "GUN Lock Req Processed" ;
VAL_ 3221225472 GUN_LOCK_FEEDBACK 1 "GUN_Locked" 0 "GUN_Unlocked" ;
VAL_ 3221225472 GUN_LOCK_FAULT 1 "GUN Lock Fault" 0 "GUN Lock OK" ;
VAL_ 3221225472 TEMP_2_FAULT 1 "Temp Greater than 70 DegC" 0 "Temp Under Permissible Limit" ;
VAL_ 3221225472 TEMP_1_FAULT 1 "Temp Greater than 70 DegC" 0 "Temp Under Permissible Limit" ;
VAL_ 3221225472 EV_Error_Code 11 "ErrorCode_NoData" 10 "ChargingSystemIncompatibility" 9 "Reserved_C" 8 "Reserved_B" 7 "Reserved_A" 6 "FAILED_ChargingVoltageOutOfRange" 5 "FAILED_ChargingCurrentDiff" 4 "FAILED_EVRESSMalfunction" 3 "FAILED_ChargerConnectorLockFault" 2 "FAILED_EVShiftPosition" 1 "FAILED_RESSTemperatureInhibit" 0 "NO_Error" ;
VAL_ 3221225472 NEGATIVE_CONTACTOR_CONTROL 1 "Close Charging Contactor" 0 "Open Charging Contactor" ;
VAL_ 3221225472 CHARGING_STATUS 1 "Vehicle Charging" 0 "Vehicle Not Charging" ;
VAL_ 3221225472 POSITIVE_CONTACTOR_CONTROL 1 "Close Charging Contactor" 0 "Open Charging Contactor" ;
VAL_ 3221225472 GUN_DETECTED 1 "GUN Detected" 0 "GUN Not Detected" ;
VAL_ 3221225472 EVCC_READY 1 "Ready Fro Charging" 0 "Not Ready" ;
VAL_ 3221225472 EVCC_STATUS_CODE 35 "Session_End" 134 "Type2_unlock_enabled_exit" 133 "Type2_Status_GunLockFault" 132 "Type2_TerminateChargingEvcc" 131 "Type2_Status_duty_fault" 130 "Type2_Status_charging_ongoing" 129 "Type2_Status_vehicle_immobilise" 128 "Type2_Status_gun_detected" 34 "Welding_Detection_Failed" 33 "Welding_Detection_Success" 32 "Welding_Detection_Ongoing" 31 "Charging_Failed" 30 "Charging_Success" 29 "Charging_Ongoing" 28 "Precharge_Failed" 27 "Precharge_Success" 26 "Precharge_Ongoing" 25 "Cable_Check_Isolation_Failed" 24 "Cable_Check_Isolation_Success" 23 "Cable_Check_Isolation_Ongoing" 22 "Charging_Params_Exchange_Failed" 21 "Charging_Params_Exchange_Success" 20 "Charging_Params_Exchange_Ongoing" 19 "Authenticating_Failed" 18 "Authenticating_Success" 17 "Authenticating_Ongoing" 16 "Payment_Selection_Failed" 15 "Payment_Selection_Success" 14 "Service_Discovery_Failed" 13 "Service_Discovery_Success" 12 "Session_Setup_Failed" 11 "Session_Setup_Success" 10 "Protocol_Handshake_Failed" 9 "Protocol_Handshake_Success" 8 "TCP_link_Failed" 7 "TCP_link_established" 6 "SECC_discovery_Failed" 5 "SECC_discovery_Success" 4 "SECC_discovery_ongoing" 3 "Slac_Failed" 2 "Slac_Success" 1 "Slacc_Ongoing" 0 "Intilizing" ;
VAL_ 3221225472 VCU_Mode 2 "VCU_Override" 1 "ON" 0 "OFF" ;
VAL_ 3221225472 VCU_Ctrl_Mode 1 "FanMode" 0 "CoolingMode" ;
VAL_ 3221225472 VCU_BenchTestSpeedLimitEnable 1 "Enable speed limit" 0 "No speed limit" ;
VAL_ 3221225472 VCU_Mode_R 1 "R Mode" 0 "Null" ;
VAL_ 3221225472 VCU_Mode_Braking 1 "Validity" 0 "Null" ;
VAL_ 3221225472 VCU_Reserved 1 "N mode" 0 "Null" ;
VAL_ 3221225472 VCU_Mode_D 1 "D Mode" 0 "Null" ;
VAL_ 3221225472 VCU_ControlMode 1 "Speed mode" 0 "Torque mode" ;
VAL_ 3221225472 VCU_Mode_N 1 "Validity" 0 "Null" ;
VAL_ 3221225472 VCU_MainRelay 1 "Main relay turn on" 0 "Main relay turn off" ;
VAL_ 3221225472 VCU_PreChargedStatus 1 " Pre-Charge Contactor turn on" 0 " Pre-Charge Contactor turn off" ;
VAL_ 3221225472 VCU_Discharge 1 "Active discharge on" 0 "Active discharge off" ;
VAL_ 3221225472 VCU_Enable 1 "Enabled" 0 "Not enabled" ;
VAL_ 3221225472 D_BMS_Rank_3_Fault 29 "Thermal runaway lvl4" 28 "Pack volt unbalance lvl3" 27 "P2P comm lost lvl3" 26 "Precharge fail lvl3" 25 "Coolant leak lvl3" 24 "Negative relay weld lvl3" 23 "Positive relay weld lvl3" 22 "Regen over current lvl3" 21 "Pack under volt lvl3" 20 "Pack over volt lvl3" 19 "Slave comm lost lvl3" 18 "Insulation low lvl3" 17 "HVIL break lvl3" 16 "VCU comm lost lvl3" 15 "Vsense loose lvl3" 14 "Slave LV high lvl3" 13 "Slave LV low lvl3" 12 "Master LV high lvl3" 11 "Master LV low lvl3" 10 "Temp sensor fail lvl3" 9 "Hall comm lost lvl3" 8 "Hall HW fail lvl3" 7 "AFE daisy chain fail lvl3" 6 "Dischg over current lvl3" 5 "Chrg over current lvl3" 4 "Cell under temp lvl3" 3 "Cell over temp lvl3" 2 "Cell under volt lvl3" 1 "Cell over volt lvl3" 0 "No Fault" ;
VAL_ 3221225472 D_BMS_Rank_2_Fault 22 "Smoke sensor comm lost lvl2" 21 "Smoke sensor HW fail lvl2" 20 "Cell high DT lvl2" 19 "Slave comm lost lvl2" 18 "Insulation low lvl2" 17 "HVIL break lvl2" 16 "VCU comm lost lvl2" 15 "Vsense loose lvl2" 14 "Slave LV high lvl2" 13 "Slave LV low lvl2" 12 "Master LV high lvl2" 11 "Master LV low lvl2" 10 "Temp sensor fail lvl2" 9 "Hall HW fail lvl2" 8 "Hall HW fail lvl2" 7 "AFE daisy chain fail lvl2" 6 "Dischg over current lvl2" 5 "Chrg over current lvl2" 4 "Cell under temp lvl2" 3 "Cell over temp lvl2" 2 "Cell under volt lvl2" 1 "Cell over volt lvl2" 0 "No Fault" ;
VAL_ 3221225472 D_BMS_Rank_1_Fault 14 "Slave FW mismatch lvl1" 13 "Pack volt unbalance lvl1" 12 "P2P comm lost lvl1" 11 "Coolant out temp hw fail lvl1" 10 "Coolant in temp sensor fail lvl1" 9 "VCAN busoff lvl1" 8 "CRC mismatch lvl1" 7 "Low SOC lvl1" 6 "Low SOH lvl1" 5 "Coolant leak lvl1" 4 "Pack volt mismatch lvl1" 3 "Cell high DT lvl1" 2 "Cell under volt lvl1" 1 "Cell over volt lvl1" 0 "No Fault" ;
VAL_ 3221225472 C_BMS_Rank_3_Fault 29 "Thermal runaway lvl4" 28 "Pack volt unbalance lvl3" 27 "P2P comm lost lvl3" 26 "Precharge fail lvl3" 25 "Coolant leak lvl3" 24 "Negative relay weld lvl3" 23 "Positive relay weld lvl3" 22 "Regen over current lvl3" 21 "Pack under volt lvl3" 20 "Pack over volt lvl3" 19 "Slave comm lost lvl3" 18 "Insulation low lvl3" 17 "HVIL break lvl3" 16 "VCU comm lost lvl3" 15 "Vsense loose lvl3" 14 "Slave LV high lvl3" 13 "Slave LV low lvl3" 12 "Master LV high lvl3" 11 "Master LV low lvl3" 10 "Temp sensor fail lvl3" 9 "Hall comm lost lvl3" 8 "Hall HW fail lvl3" 7 "AFE daisy chain fail lvl3" 6 "Dischg over current lvl3" 5 "Chrg over current lvl3" 4 "Cell under temp lvl3" 3 "Cell over temp lvl3" 2 "Cell under volt lvl3" 1 "Cell over volt lvl3" 0 "No Fault" ;
VAL_ 3221225472 C_BMS_Rank_2_Fault 22 "Smoke sensor comm lost lvl2" 21 "Smoke sensor HW fail lvl2" 20 "Cell high DT lvl2" 19 "Slave comm lost lvl2" 18 "Insulation low lvl2" 17 "HVIL break lvl2" 16 "VCU comm lost lvl2" 15 "Vsense loose lvl2" 14 "Slave LV high lvl2" 13 "Slave LV low lvl2" 12 "Master LV high lvl2" 11 "Master LV low lvl2" 10 "Temp sensor fail lvl2" 9 "Hall HW fail lvl2" 8 "Hall HW fail lvl2" 7 "AFE daisy chain fail lvl2" 6 "Dischg over current lvl2" 5 "Chrg over current lvl2" 4 "Cell under temp lvl2" 3 "Cell over temp lvl2" 2 "Cell under volt lvl2" 1 "Cell over volt lvl2" 0 "No Fault" ;
VAL_ 3221225472 C_BMS_Rank_1_Fault 14 "Slave FW mismatch lvl1" 13 "Pack volt unbalance lvl1" 12 "P2P comm lost lvl1" 11 "Coolant out temp hw fail lvl1" 10 "Coolant in temp sensor fail lvl1" 9 "VCAN busoff lvl1" 8 "CRC mismatch lvl1" 7 "Low SOC lvl1" 6 "Low SOH lvl1" 5 "Coolant leak lvl1" 4 "Pack volt mismatch lvl1" 3 "Cell high DT lvl1" 2 "Cell under volt lvl1" 1 "Cell over volt lvl1" 0 "No Fault" ;
VAL_ 3221225472 B_BMS_Rank_3_Fault 29 "Thermal runaway lvl4" 28 "Pack volt unbalance lvl3" 27 "P2P comm lost lvl3" 26 "Precharge fail lvl3" 25 "Coolant leak lvl3" 24 "Negative relay weld lvl3" 23 "Positive relay weld lvl3" 22 "Regen over current lvl3" 21 "Pack under volt lvl3" 20 "Pack over volt lvl3" 19 "Slave comm lost lvl3" 18 "Insulation low lvl3" 17 "HVIL break lvl3" 16 "VCU comm lost lvl3" 15 "Vsense loose lvl3" 14 "Slave LV high lvl3" 13 "Slave LV low lvl3" 12 "Master LV high lvl3" 11 "Master LV low lvl3" 10 "Temp sensor fail lvl3" 9 "Hall comm lost lvl3" 8 "Hall HW fail lvl3" 7 "AFE daisy chain fail lvl3" 6 "Dischg over current lvl3" 5 "Chrg over current lvl3" 4 "Cell under temp lvl3" 3 "Cell over temp lvl3" 2 "Cell under volt lvl3" 1 "Cell over volt lvl3" 0 "No Fault" ;
VAL_ 3221225472 B_BMS_Rank_2_Fault 22 "Smoke sensor comm lost lvl2" 21 "Smoke sensor HW fail lvl2" 20 "Cell high DT lvl2" 19 "Slave comm lost lvl2" 18 "Insulation low lvl2" 17 "HVIL break lvl2" 16 "VCU comm lost lvl2" 15 "Vsense loose lvl2" 14 "Slave LV high lvl2" 13 "Slave LV low lvl2" 12 "Master LV high lvl2" 11 "Master LV low lvl2" 10 "Temp sensor fail lvl2" 9 "Hall HW fail lvl2" 8 "Hall HW fail lvl2" 7 "AFE daisy chain fail lvl2" 6 "Dischg over current lvl2" 5 "Chrg over current lvl2" 4 "Cell under temp lvl2" 3 "Cell over temp lvl2" 2 "Cell under volt lvl2" 1 "Cell over volt lvl2" 0 "No Fault" ;
VAL_ 3221225472 B_BMS_Rank_1_Fault 14 "Slave FW mismatch lvl1" 13 "Pack volt unbalance lvl1" 12 "P2P comm lost lvl1" 11 "Coolant out temp hw fail lvl1" 10 "Coolant in temp sensor fail lvl1" 9 "VCAN busoff lvl1" 8 "CRC mismatch lvl1" 7 "Low SOC lvl1" 6 "Low SOH lvl1" 5 "Coolant leak lvl1" 4 "Pack volt mismatch lvl1" 3 "Cell high DT lvl1" 2 "Cell under volt lvl1" 1 "Cell over volt lvl1" 0 "No Fault" ;
VAL_ 3221225472 A_BMS_Rank_3_Fault 29 "Thermal runaway lvl4" 28 "Pack volt unbalance lvl3" 27 "P2P comm lost lvl3" 26 "Precharge fail lvl3" 25 "Coolant leak lvl3" 24 "Negative relay weld lvl3" 23 "Positive relay weld lvl3" 22 "Regen over current lvl3" 21 "Pack under volt lvl3" 20 "Pack over volt lvl3" 19 "Slave comm lost lvl3" 18 "Insulation low lvl3" 17 "HVIL break lvl3" 16 "VCU comm lost lvl3" 15 "Vsense loose lvl3" 14 "Slave LV high lvl3" 13 "Slave LV low lvl3" 12 "Master LV high lvl3" 11 "Master LV low lvl3" 10 "Temp sensor fail lvl3" 9 "Hall comm lost lvl3" 8 "Hall HW fail lvl3" 7 "AFE daisy chain fail lvl3" 6 "Dischg over current lvl3" 5 "Chrg over current lvl3" 4 "Cell under temp lvl3" 3 "Cell over temp lvl3" 2 "Cell under volt lvl3" 1 "Cell over volt lvl3" 0 "No Fault" ;
VAL_ 3221225472 A_BMS_Rank_2_Fault 22 "Smoke sensor comm lost lvl2" 21 "Smoke sensor HW fail lvl2" 20 "Cell high DT lvl2" 19 "Slave comm lost lvl2" 18 "Insulation low lvl2" 17 "HVIL break lvl2" 16 "VCU comm lost lvl2" 15 "Vsense loose lvl2" 14 "Slave LV high lvl2" 13 "Slave LV low lvl2" 12 "Master LV high lvl2" 11 "Master LV low lvl2" 10 "Temp sensor fail lvl2" 9 "Hall HW fail lvl2" 8 "Hall HW fail lvl2" 7 "AFE daisy chain fail lvl2" 6 "Dischg over current lvl2" 5 "Chrg over current lvl2" 4 "Cell under temp lvl2" 3 "Cell over temp lvl2" 2 "Cell under volt lvl2" 1 "Cell over volt lvl2" 0 "No Fault" ;
VAL_ 3221225472 A_BMS_Rank_1_Fault 14 "Slave FW mismatch lvl1" 13 "Pack volt unbalance lvl1" 12 "P2P comm lost lvl1" 11 "Coolant out temp hw fail lvl1" 10 "Coolant in temp sensor fail lvl1" 9 "VCAN busoff lvl1" 8 "CRC mismatch lvl1" 7 "Low SOC lvl1" 6 "Low SOH lvl1" 5 "Coolant leak lvl1" 4 "Pack volt mismatch lvl1" 3 "Cell high DT lvl1" 2 "Cell under volt lvl1" 1 "Cell over volt lvl1" 0 "No Fault" ;
VAL_ 3221225472 VCU_BMS_No_of_Packs 4 "0 Packs" 3 "3 Packs" 2 "2 Packs" 1 "1 Pack" 0 "0 Pack" ;
VAL_ 3221225472 VCU_BMS_Response_CRC_Fail 1 "Fail" 0 "Not Fail" ;
VAL_ 3221225472 VCU_BMS_Charge_Flag 1 "Charge On" 0 "Charge Off" ;
VAL_ 3221225472 VCU_BMS_Insulation_Enable 1 "ON" 0 "OFF" ;
VAL_ 3221225472 VCU_BMS_MainC_Close 1 "ON" 0 "OFF" ;
VAL_ 3221225472 VCU_BMS_EPO 1 "ON" 0 "OFF" ;
VAL_ 3221225472 VCU_BMS_Enable 1 "ON" 0 "OFF" ;
VAL_ 3221225472 A_BMS_Smoke_Sensor_Status 3 "Power supply under voltage" 2 "Power supply over voltage" 1 "Optical device malfunction" 0 "Normal" ;
VAL_ 3221225472 A_BMS_Mux_Temp_Data_Counter 1 "Slave No 2" 0 "Slave No 1" ;
VAL_ 3221225472 A_BMS_P2P_Comm_Status4 1 "Communication online" 0 "Communication lost" ;
VAL_ 3221225472 A_BMS_P2P_Comm_Status3 1 "Communication online" 0 "Communication lost" ;
VAL_ 3221225472 A_BMS_P2P_Comm_Status2 1 "Communication online" 0 "Communication lost" ;
VAL_ 3221225472 A_BMS_P2P_Comm_Status1 1 "Communication online" 0 "Communication lost" ;
VAL_ 3221225472 A_BMS_Oper_Mode 7 "Ready to sleep" 6 "Fault" 5 "Charge" 4 "Discharge" 3 "Precharge" 2 "PV difference check" 1 "Standby" 0 "Initialization" ;
VAL_ 3221225472 A_BMS_IR_Measure_Seq 7 "Stop IR measurement" 4 "packD to measure IR" 3 "packC to measure IR" 2 "packB to measure IR" 1 "packA to measure IR" ;
VAL_ 3221225472 A_BMS_Slave_Comm_Status 1 "Communication online" 0 "Communication lost" ;
VAL_ 3221225472 A_BMS_Slave_Vsense_Status 1 "Description for the value '0x1'" 0 "Vsense circuit open" ;
VAL_ 3221225472 A_BMS_Slave_AFE_Status 1 "AFE status ok" 0 "AFE status not ok" ;
VAL_ 3221225472 A_BMS_Slave_No 1 "Slave No 2" 0 "Slave No 1" ;
VAL_ 3221225472 A_BMS_Balance_Enable_Flag 1 "ON" 0 "OFF" ;
VAL_ 3221225472 A_BMS_Fault_Rank 4 "Fourth Fault Level" 3 "Third Fault Level" 2 "Second Fault Level" 1 "First Fault Level" 0 "No Fault" ;
VAL_ 3221225472 A_BMS_Wake_Up_Source 2 "Wake up by thermal sensor" 1 "Wake up by key" 0 "No wake up source" ;
VAL_ 3221225472 A_BMS_Key_Status 1 "Key On" 0 "Key Off" ;
VAL_ 3221225472 A_BMS_IR_Enable_Flag 1 "Insulation Enabled" 0 "Insulation Disabled" ;
VAL_ 3221225472 A_BMS_Pre_Relay_Status 1 "Close" 0 "Open" ;
VAL_ 3221225472 A_BMS_Neg_Relay_Status 1 "Close" 0 "Open" ;
VAL_ 3221225472 A_BMS_Pos_Relay_Status 1 "Close" 0 "Open" ;
VAL_ 3221225472 A_BMS_HV_Circuit_Status 1 "Close" 0 "Open" ;
VAL_ 3221225472 A_BMS_HVIL_Status 1 "ON" 0 "OFF" ;
VAL_ 3221225472 A_BMS_Pack_Ready 1 "Pack Ready" 0 "Pack Not Ready" ;
VAL_ 3221225472 B_BMS_Smoke_Sensor_Status 3 "Power supply under voltage" 2 "Power supply over voltage" 1 "Optical device malfunction" 0 "Normal" ;
VAL_ 3221225472 B_BMS_Mux_Temp_Data_Counter 1 "Slave No 2" 0 "Slave No 1" ;
VAL_ 3221225472 B_BMS_P2P_Comm_Status4 1 "Communication online" 0 "Communication lost" ;
VAL_ 3221225472 B_BMS_P2P_Comm_Status3 1 "Communication online" 0 "Communication lost" ;
VAL_ 3221225472 B_BMS_P2P_Comm_Status2 1 "Communication online" 0 "Communication lost" ;
VAL_ 3221225472 B_BMS_P2P_Comm_Status1 1 "Communication online" 0 "Communication lost" ;
VAL_ 3221225472 B_BMS_Oper_Mode 7 "Ready to sleep" 6 "Fault" 5 "Charge" 4 "Discharge" 3 "Precharge" 2 "PV difference check" 1 "Standby" 0 "Initialization" ;
VAL_ 3221225472 B_BMS_IR_Measure_Seq 7 "Stop IR measurement" 4 "packD to measure IR" 3 "packC to measure IR" 2 "packB to measure IR" 1 "packA to measure IR" ;
VAL_ 3221225472 B_BMS_Slave_Comm_Status 1 "Communication online" 0 "Communication lost" ;
VAL_ 3221225472 B_BMS_Slave_Vsense_Status 1 "Description for the value '0x1'" 0 "Vsense circuit open" ;
VAL_ 3221225472 B_BMS_Slave_AFE_Status 1 "AFE status ok" 0 "AFE status not ok" ;
VAL_ 3221225472 B_BMS_Slave_No 1 "Slave No 2" 0 "Slave No 1" ;
VAL_ 3221225472 B_BMS_Balance_Enable_Flag 1 "ON" 0 "OFF" ;
VAL_ 3221225472 B_BMS_Fault_Rank 4 "Fourth Fault Level" 3 "Third Fault Level" 2 "Second Fault Level" 1 "First Fault Level" 0 "No Fault" ;
VAL_ 3221225472 B_BMS_Wake_Up_Source 2 "Wake up by thermal sensor" 1 "Wake up by key" 0 "No wake up source" ;
VAL_ 3221225472 B_BMS_Key_Status 1 "Key On" 0 "Key Off" ;
VAL_ 3221225472 B_BMS_IR_Enable_Flag 1 "Insulation Enabled" 0 "Insulation Disabled" ;
VAL_ 3221225472 B_BMS_Pre_Relay_Status 1 "Close" 0 "Open" ;
VAL_ 3221225472 B_BMS_Neg_Relay_Status 1 "Close" 0 "Open" ;
VAL_ 3221225472 B_BMS_Pos_Relay_Status 1 "Close" 0 "Open" ;
VAL_ 3221225472 B_BMS_HV_Circuit_Status 1 "Close" 0 "Open" ;
VAL_ 3221225472 B_BMS_HVIL_Status 1 "ON" 0 "OFF" ;
VAL_ 3221225472 B_BMS_Pack_Ready 1 "Pack Ready" 0 "Pack Not Ready" ;
VAL_ 3221225472 C_BMS_Smoke_Sensor_Status 3 "Power supply under voltage" 2 "Power supply over voltage" 1 "Optical device malfunction" 0 "Normal" ;
VAL_ 3221225472 C_BMS_Mux_Temp_Data_Counter 1 "Slave No 2" 0 "Slave No 1" ;
VAL_ 3221225472 C_BMS_P2P_Comm_Status4 1 "Communication online" 0 "Communication lost" ;
VAL_ 3221225472 C_BMS_P2P_Comm_Status3 1 "Communication online" 0 "Communication lost" ;
VAL_ 3221225472 C_BMS_P2P_Comm_Status2 1 "Communication online" 0 "Communication lost" ;
VAL_ 3221225472 C_BMS_P2P_Comm_Status1 1 "Communication online" 0 "Communication lost" ;
VAL_ 3221225472 C_BMS_Oper_Mode 7 "Ready to sleep" 6 "Fault" 5 "Charge" 4 "Discharge" 3 "Precharge" 2 "PV difference check" 1 "Standby" 0 "Initialization" ;
VAL_ 3221225472 C_BMS_IR_Measure_Seq 7 "Stop IR measurement" 4 "packD to measure IR" 3 "packC to measure IR" 2 "packB to measure IR" 1 "packA to measure IR" ;
VAL_ 3221225472 C_BMS_Slave_Comm_Status 1 "Communication online" 0 "Communication lost" ;
VAL_ 3221225472 C_BMS_Slave_Vsense_Status 1 "Description for the value '0x1'" 0 "Vsense circuit open" ;
VAL_ 3221225472 C_BMS_Slave_AFE_Status 1 "AFE status ok" 0 "AFE status not ok" ;
VAL_ 3221225472 C_BMS_Slave_No 1 "Slave No 2" 0 "Slave No 1" ;
VAL_ 3221225472 C_BMS_Balance_Enable_Flag 1 "ON" 0 "OFF" ;
VAL_ 3221225472 C_BMS_Fault_Rank 4 "Fourth Fault Level" 3 "Third Fault Level" 2 "Second Fault Level" 1 "First Fault Level" 0 "No Fault" ;
VAL_ 3221225472 C_BMS_Wake_Up_Source 2 "Wake up by thermal sensor" 1 "Wake up by key" 0 "No wake up source" ;
VAL_ 3221225472 C_BMS_Key_Status 1 "Key On" 0 "Key Off" ;
VAL_ 3221225472 C_BMS_IR_Enable_Flag 1 "Insulation Enabled" 0 "Insulation Disabled" ;
VAL_ 3221225472 C_BMS_Pre_Relay_Status 1 "Close" 0 "Open" ;
VAL_ 3221225472 C_BMS_Neg_Relay_Status 1 "Close" 0 "Open" ;
VAL_ 3221225472 C_BMS_Pos_Relay_Status 1 "Close" 0 "Open" ;
VAL_ 3221225472 C_BMS_HV_Circuit_Status 1 "Close" 0 "Open" ;
VAL_ 3221225472 C_BMS_HVIL_Status 1 "ON" 0 "OFF" ;
VAL_ 3221225472 C_BMS_Pack_Ready 1 "Pack Ready" 0 "Pack Not Ready" ;
VAL_ 3221225472 D_BMS_Smoke_Sensor_Status 3 "Power supply under voltage" 2 "Power supply over voltage" 1 "Optical device malfunction" 0 "Normal" ;
VAL_ 3221225472 D_BMS_Mux_Temp_Data_Counter 1 "Slave No 2" 0 "Slave No 1" ;
VAL_ 3221225472 D_BMS_P2P_Comm_Status4 1 "Communication online" 0 "Communication lost" ;
VAL_ 3221225472 D_BMS_P2P_Comm_Status3 1 "Communication online" 0 "Communication lost" ;
VAL_ 3221225472 D_BMS_P2P_Comm_Status2 1 "Communication online" 0 "Communication lost" ;
VAL_ 3221225472 D_BMS_P2P_Comm_Status1 1 "Communication online" 0 "Communication lost" ;
VAL_ 3221225472 D_BMS_Oper_Mode 7 "Ready to sleep" 6 "Fault" 5 "Charge" 4 "Discharge" 3 "Precharge" 2 "PV difference check" 1 "Standby" 0 "Initialization" ;
VAL_ 3221225472 D_BMS_IR_Measure_Seq 7 "Stop IR measurement" 4 "packD to measure IR" 3 "packC to measure IR" 2 "packB to measure IR" 1 "packA to measure IR" ;
VAL_ 3221225472 D_BMS_Slave_Comm_Status 1 "Communication online" 0 "Communication lost" ;
VAL_ 3221225472 D_BMS_Slave_Vsense_Status 1 "Description for the value '0x1'" 0 "Vsense circuit open" ;
VAL_ 3221225472 D_BMS_Slave_AFE_Status 1 "AFE status ok" 0 "AFE status not ok" ;
VAL_ 3221225472 D_BMS_Slave_No 1 "Slave No 2" 0 "Slave No 1" ;
VAL_ 3221225472 D_BMS_Balance_Enable_Flag 1 "ON" 0 "OFF" ;
VAL_ 3221225472 D_BMS_Fault_Rank 4 "Fourth Fault Level" 3 "Third Fault Level" 2 "Second Fault Level" 1 "First Fault Level" 0 "No Fault" ;
VAL_ 3221225472 D_BMS_Wake_Up_Source 2 "Wake up by thermal sensor" 1 "Wake up by key" 0 "No wake up source" ;
VAL_ 3221225472 D_BMS_Key_Status 1 "Key On" 0 "Key Off" ;
VAL_ 3221225472 D_BMS_IR_Enable_Flag 1 "Insulation Enabled" 0 "Insulation Disabled" ;
VAL_ 3221225472 D_BMS_Pre_Relay_Status 1 "Close" 0 "Open" ;
VAL_ 3221225472 D_BMS_Neg_Relay_Status 1 "Close" 0 "Open" ;
VAL_ 3221225472 D_BMS_Pos_Relay_Status 1 "Close" 0 "Open" ;
VAL_ 3221225472 D_BMS_HV_Circuit_Status 1 "Close" 0 "Open" ;
VAL_ 3221225472 D_BMS_HVIL_Status 1 "ON" 0 "OFF" ;
VAL_ 3221225472 D_BMS_Pack_Ready 1 "Pack Ready" 0 "Pack Not Ready" ;
VAL_ 2499739891 AC_Max_Current 65535 "SNA" 65279 "Invalid" ;
VAL_ 2499739891 Actual_BatteryCurrent 65535 "SNA" 65279 "Invalid" ;
VAL_ 2499739891 Actual_BatteryVoltage 65535 "SNA" 65279 "Invalid" ;
VAL_ 2566857200 EV_DisconnectingDevice_Status 0 "opened" 1 "closed" 2 "error" 3 "SNA" ;
VAL_ 2566857200 PLC_available 0 "not available" 1 "available" 2 "reserved" 3 "SNA" ;
VAL_ 2566857200 CCS_AC_ContactTemp_Sens 0 "no error" 1 "over temperature" 2 "temperature warning" 3 "SNA" ;
VAL_ 2566857200 CCS_DC_ContactTempSens 0 "no error" 1 "over temperature" 2 "temperature warning" 3 "SNA" ;
VAL_ 2566857200 DC_charging_active 0 "inactive" 1 "active" 2 "not used" 3 "SNA" ;
VAL_ 2566857200 CCS_PlugLockFailure 0 "no error" 1 "error" 2 "reserved" 3 "SNA" ;
VAL_ 2566857200 Vac_InRange 0 "out of range" 1 "in range" 2 "reserved" 3 "SNA" ;
VAL_ 2566857200 Fac_InRange 0 "out of range" 1 "in range" 2 "reserved" 3 "SNA" ;
VAL_ 2566857200 AC_Mode 0 "3phase" 1 "1phase" 2 "reserved" 3 "SNA" ;
VAL_ 2566857200 DeratingVoltage 0 "inactive" 1 "active" 2 "not used" 3 "SNA" ;
VAL_ 2566857200 PreChargeRelay_status 0 "open" 1 "closed" 2 "fault" 3 "SNA" ;
VAL_ 2566857200 MainRelay_status 0 "open" 1 "closed" 2 "fault" 3 "SNA" ;
VAL_ 2566857200 DeratingTemperature 0 "inactive" 1 "active" 2 "not used" 3 "SNA" ;
VAL_ 2566857200 OBC_Availability 0 "no OBC" 1 "OBC available" 2 "not used" 3 "SNA" ;
VAL_ 2566857200 InternalCAN_Error 0 "no error" 1 "error" 2 "reserved" 3 "SNA" ;
VAL_ 2566857200 ChargeStopActive 0 "inactive" 1 "active" 2 "not used" 3 "SNA" ;
VAL_ 2566857200 OBC1_StateAct 0 "unknown" 1 "sleep" 2 "wakeup" 3 "standby" 4 "ready4charge" 5 "charging" 6 "shutdown" 7 "reserved" 15 "SNA" ;
VAL_ 2566857200 OBC2_StateAct 0 "unknown" 1 "sleep" 2 "wakeup" 3 "standby" 4 "ready4charge" 5 "charging" 6 "shutdown" 7 "reserved" 15 "SNA" ;
VAL_ 2566857200 OBC3_StateAct 0 "unknown" 1 "sleep" 2 "wakeup" 3 "standby" 4 "ready4charge" 5 "charging" 6 "shutdown" 7 "reserved" 15 "SNA" ;
VAL_ 2566857200 OBC4_StateAct 0 "unknown" 1 "sleep" 2 "wakeup" 3 "standby" 4 "ready4charge" 5 "charging" 6 "shutdown" 7 "reserved" 15 "SNA" ;
VAL_ 2566857200 EV_DisconnectingDevPlus_Status 0 "opened" 1 "closed" 2 "error" 3 "SNA" ;
VAL_ 2566857200 EV_DisconnectingDevMinus_Status 0 "opened" 1 "closed" 2 "error" 3 "SNA" ;
VAL_ 2566857456 OBC1_Error 0 "no error" 1 "error" 2 "locked" 3 "SNA" ;
VAL_ 2566857456 OBC2_Error 0 "no error" 1 "error" 2 "locked" 3 "SNA" ;
VAL_ 2566857456 OBC3_Error 0 "no error" 1 "error" 2 "locked" 3 "SNA" ;
VAL_ 2566857456 OBC4_Error 0 "no error" 1 "error" 2 "locked" 3 "SNA" ;
VAL_ 2566857456 OBC1_OverTemp 0 "no error" 1 "error" 2 "warning" 3 "SNA" ;
VAL_ 2566857456 OBC2_OverTemp 0 "no error" 1 "error" 2 "warning" 3 "SNA" ;
VAL_ 2566857456 OBC3_OverTemp 0 "no error" 1 "error" 2 "warning" 3 "SNA" ;
VAL_ 2566857456 OBC4_OverTemp 0 "no error" 1 "error" 2 "warning" 3 "SNA" ;
VAL_ 2566857712 OBC_DcHvCurrLimMax 65535 "SNA" 65279 "Invalid" ;
VAL_ 2566857712 OBC_DcHvVoltLimMax 65535 "SNA" 65279 "Invalid" ;
VAL_ 2566857712 OBC_AcCurrLimMax 65535 "SNA" 65279 "Invalid" ;
VAL_ 2566857712 OBC_DcPoLimMax 65535 "SNA" 65279 "Invalid" ;
VAL_ 2566857968 OBC_CP_current 65535 "SNA" 65279 "Invalid" ;
VAL_ 2566857968 OBC_PP_current 65535 "SNA" 65279 "Invalid" ;
VAL_ 2566857968 CCS_AC_ContactTemp 254 "Invalid" 255 "SNA" ;
VAL_ 2566857968 CCS_DC_ContactTemp 254 "Invalid" 255 "SNA" ;
VAL_ 2566858224 OBC_AcVolt_Act 65535 "SNA" 65279 "Invalid" ;
VAL_ 2566858224 OBC_AcCurr_Act 65535 "SNA" 65279 "Invalid" ;
VAL_ 2566858224 OBC_DCVolt_Act 65535 "SNA" 65279 "Invalid" ;
VAL_ 2566858224 OBC_DCCurr_Act 65535 "SNA" 65279 "Invalid" ;
VAL_ 2566860272 OBC_Coolant_Temp_1 254 "Invalid" 255 "SNA" ;
VAL_ 2566860272 OBC_Coolant_Temp_2 254 "Invalid" 255 "SNA" ;
VAL_ 2147483906 Brake_Bit 0 "OFF" 1 "ON" ;
VAL_ 2147483908 Park 0 "OFF" 1 "ON" ;
VAL_ 2147483908 Crank 0 "OFF" 1 "ON" ;
VAL_ 2147483908 Ignition 0 "OFF" 1 "ON" ;
VAL_ 2147483908 HV_Enable 0 "OFF" 1 "ON" ;
VAL_ 2147483908 PDU_Cont_Enable 0 "OFF" 1 "ON" ;
VAL_ 2147483908 VCU_Air_comp_enable 0 "OFF" 1 "ON" ;
VAL_ 2566835255 LV_Relay_Status 1 "ON" 0 "OFF" ;
VAL_ 2566835255 HV_Relay_Status 1 "ON" 0 "OFF" ;
VAL_ 2566835255 PUMP1_working_state 3 "Unused" 2 "Disorderly close-down" 1 "Pump operation" 0 "Normal shutdown" ;
VAL_ 2566835255 Ignition_Wake_up 1 "ON" 0 "OFF" ;
VAL_ 2566835255 Pump1_failure_type 64 "Shutoff Protection" 16 "Undervoltage Protection" 8 "Overvoltage Protection" 4 "OverPower Protection" 2 "Overcurrent Protection" 0 "Normal Operation" ;
VAL_ 2566835511 COMP_Compressor_Error 128 "Over Power Drop Frequency" 64 "OverCurrent Drop Frequency" 32 "Communication Error" 16 "Standby Undervoltage" 8 "Standby Overvoltage" 4 "Undervoltage" 2 "Over Voltage" 1 "Over Current" 0 "No Error" ;
VAL_ 2566835511 COMP_Compressor_Enable 2 "Error" 1 "ON" 0 "OFF" ;
VAL_ 2566835511 BCS_Diagnostics_Signal 51 "LV Low Voltage " 49 "Incomplete precharge" 40 "Discharge pressure short to gnd" 39 "C-out temp short-bat/open ckt" 38 "C-out temp short to gnd" 37 "C-in temp short-bat/open ckt" 36 "C-in temp short to gnd" 35 "Amb temp short-bat/open ckt" 34 "Amb temp short to gnd" 33 "C-level short-bat/open ckt/ low" 32 "C-level short to gnd" 8 "Refrigerant leak" 3 "Pump Fault" 5 "Compressor Fault" 7 "C-level short-bat/open ckt/ low" 1 "High press/short-bat/open ckt" 0 "Normal" ;
VAL_ 2349639664 MCU_Rank_3_Fault 26 "IGBT Fault lvl3" 25 "DCBusHardwareOverVoltage lvl3" 24 "Current Detection lvl3" 23 "MotorPhase lvl3" 22 "AuxVoltageUnderVoltage lvl3" 21 "UnderVoltage lvl3" 20 "MotorOverTemp lvl3" 19 "IgbtOverTemp lvl3" 18 "CanBusOffLine lvl3" 17 "OverSpeed lvl3" 16 "ASC lvl 3" 15 "W-phase hardware overcur lvl 3" 14 "V-phase hardware overcur lvl 3" 13 "U-phase hardware overcur lvl 3" 12 "W-phase lower bridge IGBT lvl 3" 11 "W-phase upper bridge IGBT lvl 3" 10 "V-phase lower bridge IGBT lvl 3" 9 "V-phase upper bridge IGBT lvl 3" 8 "U-phase lower bridge IGBT lvl 3" 7 "U-phase upper bridge IGBT lvl 3" 6 "Critical overvoltage lvl 3" 5 "Software overcurrent lvl 3" 4 "Throttle self-test lvl 3" 3 "Data self-test lvl 3" 2 "Resolver lvl 3" 1 "Hardware overcurrent lvl 3" 0 "No Fault" ;
VAL_ 2349639664 MCU_Rank_2_Fault 6 "Motor temp sensor lvl 2" 5 "IGBT Temp Sensor lvl 2" 4 "Motor normal over-temp lvl 2" 3 "IGBT normal over-temp lvl2" 2 "Controller overload lvl 2" 1 "Normal underVoltage lvl 2" 0 "No Fault" ;
VAL_ 2349639664 MCU_Rank_1_Fault 4 "Over speed warning lvl 1" 3 "Aux voltage under warning lvl 1" 2 "Overload pre warning lvl 1" 1 "Normal Overvoltage fault lvl 1" 0 "No Fault" ;
VAL_ 2349508592 MCU_N_FaultGrade 3 "Severity 3 fault" 2 "Severity 2 fault" 1 "Severity 1 fault" 0 "No faults" ;
VAL_ 2349508592 MCU_F_SPEED_OV_WARNING 1 "Fault" 0 "No faults" ;
VAL_ 2349508592 MCU_F_ACC_UV_WARNING 1 "Fault" 0 "No faults" ;
VAL_ 2349508592 MCU_F_MOTOR_TEMP_SENSOR 1 "Fault" 0 "No faults" ;
VAL_ 2349508592 MCU_F_IGBT_TEMP_SENSOR 1 "Fault" 0 "No faults" ;
VAL_ 2349508592 MCU_F_H_W_OC 1 "Fault" 0 "No faults" ;
VAL_ 2349508592 MCU_F_H_V_OC 1 "Fault" 0 "No faults" ;
VAL_ 2349508592 MCU_F_H_U_OC 1 "Fault" 0 "No faults" ;
VAL_ 2349508592 MCU_F_IGBT 1 "Fault" 0 "No faults" ;
VAL_ 2349508592 MCU_F_H_OC 1 "Fault" 0 "No faults" ;
VAL_ 2349508592 MCU_F_H_OV 1 "Fault" 0 "No faults" ;
VAL_ 2349508592 MCU_F_ENCORDE 1 "Fault" 0 "No faults" ;
VAL_ 2349508592 MCU_F_LACK_PHASE 1 "Fault" 0 "No faults" ;
VAL_ 2349508592 MCU_F_CURRENT_DETECT 1 "Fault" 0 "No faults" ;
VAL_ 2349508592 MCU_F_GUN_SELF 1 "Fault" 0 "No faults" ;
VAL_ 2349508592 MCU_F_ACC_UV 1 "Fault" 0 "No faults" ;
VAL_ 2349508592 MCU_F_BUS_OV_H 1 "Fault" 0 "No faults" ;
VAL_ 2349508592 MCU_F_S_OC 1 "Fault" 0 "No faults" ;
VAL_ 2349508592 MCU_F_BUS_UV_L 1 "Fault" 0 "No faults" ;
VAL_ 2349508592 MCU_F_BUS_UV_H 1 "Fault" 0 "No faults" ;
VAL_ 2349508592 MCU_F_BUS_OV_L 1 "Fault" 0 "No faults" ;
VAL_ 2349508592 MCU_F_CONTROL_OL_L 1 "Fault" 0 "No faults" ;
VAL_ 2349508592 MCU_F_CONTROL_OL_H 1 "Fault" 0 "No faults" ;
VAL_ 2349508592 MCU_F_SPEED_OV 1 "Fault" 0 "No faults" ;
VAL_ 2349508592 MCU_F_CAN_OFFLINE 1 "Fault" 0 "No faults" ;
VAL_ 2349508592 MCU_F_IGBT_OT_L 1 "Fault" 0 "No faults" ;
VAL_ 2349508592 MCU_F_IGBT_OT_H 1 "Fault" 0 "No faults" ;
VAL_ 2349508592 MCU_F_MOTOR_OT_L 1 "Fault" 0 "No faults" ;
VAL_ 2349508592 MCU_F_MOTOR_OT_H 1 "Fault" 0 "No faults" ;
VAL_ 2349508592 MCU_F_U_UP_IGBT 1 "Fault" 0 "No faults" ;
VAL_ 2349508592 MCU_F_U_DOWN_IGBT 1 "Fault" 0 "No faults" ;
VAL_ 2349508592 MCU_F_V_UP_IGBT 1 "Fault" 0 "No faults" ;
VAL_ 2349508592 MCU_F_V_DOWN_IGBT 1 "Fault" 0 "No faults" ;
VAL_ 2349508592 MCU_F_W_UP_IGBT 1 "Fault" 0 "No faults" ;
VAL_ 2349508592 MCU_F_W_DOWN_IGBT 1 "Fault" 0 "No faults" ;
VAL_ 2349377520 MCU_Gear 3 "NO Command" 2 "R mode" 1 "D mode" 0 "N mode" ;
VAL_ 2349377520 MCU_Run_Direction 1 "Motor forward" 0 "Motor reversal " ;
VAL_ 2349377520 MCU_PWM 1 "Turn on PWM" 0 "Turn off PWM" ;
VAL_ 2349377520 MCU_ControlMode 1 "SpeedMode" 0 "TorqueMode" ;
VAL_ 2349377520 MCU_Ready 1 " ready" 0 "no ready" ;
VAL_ 2349377520 MCU_Fault 1 "Fault" 0 "No faults" ;
VAL_ 2349377520 MCU_Drive_or_Brake 1 "Drive" 0 "Regenerate" ;
VAL_ 2349377520 MCU_Discharge 1 "Activate" 0 "Forbidden" ;
VAL_ 2349377520 MCU_MotorRun 1 "Run" 0 "Stop" ;
